VERSION ""

NS_ :

BS_:

BU_: EMS EAS
VAL_TABLE_ FMI 31 "ConditionExists" 19 "Received network data in error" 18 "Below normal (moderately severe)" 17 "Below normal (least severe)" 16 "Above normal (moderately severe)" 15 "Above normal (least severe)" 14 "Special intstructions" 13 "Out of calibration" 12 "Bad intelligent device" 11 "Root cause not known" 10 "Abnormal rate of change" 9 "Abnormal update rate" 8 "Abnormal frequency" 7 "Mechanical system not responding" 6 "Current above normal" 5 "Current below normal" 4 "Voltage below normal" 3 "Voltage above normal" 2 "Data erratic" 1 "Below normal (most severe)" 0 "Above normal (most severe)" ;

BO_ 3221225472 VECTOR__INDEPENDENT_SIG_MSG: 0 Vector__XXX
 SG_ AftrTrtmntOtltOxygnSnsrPrlmnryFM : 0|5@1+ (1,0) [0|31] "" Vector__XXX
 SG_ AftrTrtmntOtltNOxSnsrPrlmnryFMI : 0|5@1+ (1,0) [0|31] "" Vector__XXX
 SG_ AftrTrtmntOtltGsSnsorHeaterCtrl : 0|2@1+ (1,0) [0|3] "" Vector__XXX
 SG_ AftrTrtmntOtltGsSnsrHtrPrlmnryFM : 0|5@1+ (1,0) [0|31] "" Vector__XXX
 SG_ AftrTrtmntOtltWdRngO2RdngStable : 0|2@1+ (1,0) [0|3] "" Vector__XXX
 SG_ AftrTrtmntOtletNOxReadingStable : 0|2@1+ (1,0) [0|3] "" Vector__XXX
 SG_ AftrTrtmntOutletGasSensorAtTemp : 0|2@1+ (1,0) [0|3] "" Vector__XXX
 SG_ AftrTrtmntOtltGsSnsrPwerInRange : 0|2@1+ (1,0) [0|3] "" Vector__XXX
 SG_ AfterTreatmentOutletO2 : 0|16@1+ (0.000514,-12) [-12|21] "%" Vector__XXX
 SG_ AfterTreatmentOutletNOx : 0|16@1+ (0.05,-200) [-200|3012.75] "ppm" Vector__XXX
 SG_ RoadSurfaceTemp : 0|16@1+ (0.03125,-273) [-273|1735] "deg" Vector__XXX
 SG_ EngAirInletTemp : 0|8@1+ (1,-40) [-40|210] "deg" Vector__XXX
 SG_ AmbientAirTemp : 0|16@1+ (0.03125,-273) [-273|1735] "deg" Vector__XXX
 SG_ CabInteriorTemp : 0|16@1+ (0.03125,-273) [-273|1735] "deg" Vector__XXX
 SG_ BarometricPress : 0|8@1+ (0.5,0) [0|125] "kPa" Vector__XXX
 SG_ EngDemandPercentTorque : 0|8@1+ (1,-125) [-125|125] "%" Vector__XXX
 SG_ EngStarterMode : 0|4@1+ (1,0) [0|15] "" Vector__XXX
 SG_ SrcAddrssOfCtrllngDvcForEngCtrl : 0|8@1+ (1,0) [0|255] "" Vector__XXX
 SG_ EngSpeed : 0|16@1+ (0.125,0) [0|8031.875] "rpm" Vector__XXX
 SG_ DriversDemandEngPercentTorque : 0|8@1+ (1,-125) [-125|125] "%" Vector__XXX
 SG_ EngTorqueMode : 0|4@1+ (1,0) [0|15] "" Vector__XXX
 SG_ SPN5 : 0|16@1+ (1,0) [0|65536] "" Vector__XXX
 SG_ SPN4 : 0|16@1+ (1,0) [0|65536] "" Vector__XXX
 SG_ SPN3 : 0|16@1+ (1,0) [0|65536] "" Vector__XXX
 SG_ SPN2 : 0|16@1+ (1,0) [0|65536] "" Vector__XXX
 SG_ FailureModeIdentifier5 : 0|5@1+ (1,0) [0|0] "" Vector__XXX
 SG_ FailureModeIdentifier4 : 0|5@1+ (1,0) [0|0] "" Vector__XXX
 SG_ FailureModeIdentifier3 : 0|5@1+ (1,0) [0|0] "" Vector__XXX
 SG_ FlashRedStopLamp : 0|2@1+ (1,0) [0|3] "" Vector__XXX
 SG_ FlashProtectLamp : 0|2@1+ (1,0) [0|3] "" Vector__XXX
 SG_ FlashMalfuncIndicatorLamp : 0|2@1+ (1,0) [0|3] "" Vector__XXX
 SG_ FlashAmberWarningLamp : 0|2@1+ (1,0) [0|3] "" Vector__XXX
 SG_ MalfunctionIndicatorLampStatus : 0|2@1+ (1,0) [0|3] "" Vector__XXX
 SG_ AmberWarningLampStatus : 0|2@1+ (1,0) [0|3] "" Vector__XXX
 SG_ OccurenceCount1 : 0|7@1+ (1,0) [0|126] "" Vector__XXX
 SG_ SPNConversionMethod1 : 0|1@1+ (1,0) [0|1] "" Vector__XXX
 SG_ FailureModeIdentifier1 : 0|5@1+ (1,0) [0|0] "" Vector__XXX
 SG_ SPN1 : 0|16@1+ (1,0) [0|65536] "" Vector__XXX
 SG_ RedStopLampState : 0|2@1+ (1,0) [0|3] "" Vector__XXX
 SG_ ProtectLampStatus : 0|2@1+ (1,0) [0|3] "" Vector__XXX
 SG_ FailureModeIdentifier2 : 0|5@1+ (1,0) [0|0] "" Vector__XXX
 SG_ SPNConversionMethod5 : 0|1@1+ (1,0) [0|1] "" Vector__XXX
 SG_ SPNConversionMethod4 : 0|1@1+ (1,0) [0|1] "" Vector__XXX
 SG_ SPNConversionMethod3 : 0|1@1+ (1,0) [0|1] "" Vector__XXX
 SG_ SPNConversionMethod2 : 0|1@1+ (1,0) [0|1] "" Vector__XXX
 SG_ OccurenceCount5 : 0|7@1+ (1,0) [0|126] "" Vector__XXX
 SG_ OccurenceCount4 : 0|7@1+ (1,0) [0|126] "" Vector__XXX
 SG_ OccurenceCount3 : 0|7@1+ (1,0) [0|126] "" Vector__XXX
 SG_ OccurenceCount2 : 0|7@1+ (1,0) [0|126] "" Vector__XXX
 SG_ SPN5High : 0|3@1+ (1,0) [0|7] "" Vector__XXX
 SG_ SPN4High : 0|3@1+ (1,0) [0|7] "" Vector__XXX
 SG_ SPN3High : 0|3@1+ (1,0) [0|7] "" Vector__XXX
 SG_ SPN2High : 0|3@1+ (1,0) [0|7] "" Vector__XXX
 SG_ SPN1High : 0|3@1+ (1,0) [0|7] "" Vector__XXX
 SG_ SPN5 : 0|16@1+ (1,0) [0|65536] "" Vector__XXX
 SG_ SPN4 : 0|16@1+ (1,0) [0|65536] "" Vector__XXX
 SG_ SPN3 : 0|16@1+ (1,0) [0|65536] "" Vector__XXX
 SG_ SPN2 : 0|16@1+ (1,0) [0|65536] "" Vector__XXX
 SG_ FailureModeIdentifier5 : 0|5@1+ (1,0) [0|0] "" Vector__XXX
 SG_ FailureModeIdentifier4 : 0|5@1+ (1,0) [0|0] "" Vector__XXX
 SG_ OccurenceCount1 : 0|7@1+ (1,0) [0|126] "" Vector__XXX
 SG_ SPNConversionMethod1 : 0|1@1+ (1,0) [0|1] "" Vector__XXX
 SG_ FailureModeIdentifier1 : 0|5@1+ (1,0) [0|0] "" Vector__XXX
 SG_ SPN1 : 0|16@1+ (1,0) [0|65536] "" Vector__XXX
 SG_ MalfunctionIndicatorLampStatus : 0|2@1+ (1,0) [0|3] "" Vector__XXX
 SG_ RedStopLampState : 0|2@1+ (1,0) [0|3] "" Vector__XXX
 SG_ AmberWarningLampStatus : 0|2@1+ (1,0) [0|3] "" Vector__XXX
 SG_ ProtectLampStatus : 0|2@1+ (1,0) [0|3] "" Vector__XXX
 SG_ FailureModeIdentifier3 : 0|5@1+ (1,0) [0|0] "" Vector__XXX
 SG_ FlashRedStopLamp : 0|2@1+ (1,0) [0|3] "" Vector__XXX
 SG_ FlashProtectLamp : 0|2@1+ (1,0) [0|3] "" Vector__XXX
 SG_ FlashMalfuncIndicatorLamp : 0|2@1+ (1,0) [0|3] "" Vector__XXX
 SG_ FlashAmberWarningLamp : 0|2@1+ (1,0) [0|3] "" Vector__XXX
 SG_ FailureModeIdentifier2 : 0|5@1+ (1,0) [0|0] "" Vector__XXX
 SG_ SPNConversionMethod5 : 0|1@1+ (1,0) [0|1] "" Vector__XXX
 SG_ SPNConversionMethod4 : 0|1@1+ (1,0) [0|1] "" Vector__XXX
 SG_ SPNConversionMethod3 : 0|1@1+ (1,0) [0|1] "" Vector__XXX
 SG_ SPNConversionMethod2 : 0|1@1+ (1,0) [0|1] "" Vector__XXX
 SG_ OccurenceCount5 : 0|7@1+ (1,0) [0|126] "" Vector__XXX
 SG_ OccurenceCount4 : 0|7@1+ (1,0) [0|126] "" Vector__XXX
 SG_ OccurenceCount3 : 0|7@1+ (1,0) [0|126] "" Vector__XXX
 SG_ OccurenceCount2 : 0|7@1+ (1,0) [0|126] "" Vector__XXX
 SG_ SPN5High : 0|3@1+ (1,0) [0|7] "" Vector__XXX
 SG_ SPN4High : 0|3@1+ (1,0) [0|7] "" Vector__XXX
 SG_ SPN3High : 0|3@1+ (1,0) [0|7] "" Vector__XXX
 SG_ SPN2High : 0|3@1+ (1,0) [0|7] "" Vector__XXX
 SG_ SPN1High : 0|3@1+ (1,0) [0|7] "" Vector__XXX
 SG_ LastTransitionState : 0|8@1+ (1,0) [0|250] "" Vector__XXX
 SG_ ActualMachineState : 0|8@1+ (1,0) [0|250] "" Vector__XXX
 SG_ ActualDosingQuantity : 0|16@1+ (0.15,0) [0|9638.25] "g/h" Vector__XXX
 SG_ ExhaustGasTemperature : 0|16@1+ (0.03125,-273) [-273|1734.96875] "°C" Vector__XXX
 SG_ ExhaustGasMassFlow : 0|16@1+ (0.05,0) [0|3212.75] "kg/h" Vector__XXX
 SG_ PowerTakeOffEnable : 0|2@1+ (1,0) [0|2] "" Vector__XXX
 SG_ ExhaustGasTemperature : 0|16@1+ (0.03125,-273) [0|0] "°C" Vector__XXX
 SG_ ExhaustGasMassFlow : 0|16@1+ (0.05,0) [0|0] "kg/h" Vector__XXX
 SG_ PowerTakeOffEnable : 0|2@1+ (1,0) [0|0] "" Vector__XXX
 SG_ EngAverageFuelEconomy : 0|16@1+ (0.001953125,0) [0|125.5] "km/L" Vector__XXX
 SG_ EngInstantaneousFuelEconomy : 0|16@1+ (0.001953125,0) [0|125.5] "km/L" Vector__XXX
 SG_ EngFuelRate : 0|16@1+ (0.05,0) [0|3212.75] "L/h" Vector__XXX
 SG_ EngThrottlePos : 0|8@1+ (0.4,0) [0|100] "%" Vector__XXX
 SG_ EngInletAirMassFlowRate : 0|16@1+ (0.05,0) [0|3212.75] "kg/h" Vector__XXX
 SG_ EngExhstGsRcrcltionMassFlowRate : 0|16@1+ (0.05,0) [0|3212.75] "kg/h" Vector__XXX
 SG_ EngVrblGometryTurbo1ActuatorPos : 0|8@1+ (0.4,0) [0|100] "%" Vector__XXX
 SG_ EngVrblGmtryTrbArCtrlShtffValve : 0|2@1+ (1,0) [0|3] "" Vector__XXX
 SG_ EngExhstGsRcirculationValveCtrl : 0|16@1+ (0.0025,0) [0|160.6375] "%" Vector__XXX
 SG_ EngTrb1ClcltedTurbineOutletTemp : 0|16@1+ (0.03125,-273) [-273|1735] "deg" Vector__XXX
 SG_ EngTrb1ClclatedTurbineInletTemp : 0|16@1+ (0.03125,-273) [-273|1735] "deg" Vector__XXX
 SG_ ExhaustGasMass : 0|16@1+ (2,0) [0|128510] "kg" Vector__XXX
 SG_ AftrTrtmntIntakeDewPointMessage : 0|2@1+ (1,0) [0|3] "" Vector__XXX
 SG_ AftrTrtmntExhustDewPointMessage : 0|2@1+ (1,0) [0|3] "" Vector__XXX
 SG_ EstEngPrsticLossesPercentTorque : 0|8@1+ (1,-125) [-125|125] "%" Vector__XXX
 SG_ EngsDsrdOprtngSpdAsymmtryAdjstmn : 0|8@1+ (1,0) [0|250] "" Vector__XXX
 SG_ EngsDesiredOperatingSpeed : 0|16@1+ (0.125,0) [0|8031.875] "rpm" Vector__XXX
 SG_ NominalFrictionPercentTorque : 0|8@1+ (1,-125) [-125|125] "%" Vector__XXX
 SG_ CatalystTankLevelPreliminaryFMI : 0|5@1+ (1,0) [0|31] "" Vector__XXX
 SG_ CatalystTankLevel2 : 0|16@1+ (0.1,0) [0|6425.5] "mm" Vector__XXX
 SG_ SPN5 : 0|16@1+ (1,0) [0|65536] "" Vector__XXX
 SG_ SPN4 : 0|16@1+ (1,0) [0|65536] "" Vector__XXX
 SG_ SPN3 : 0|16@1+ (1,0) [0|65536] "" Vector__XXX
 SG_ SPN2 : 0|16@1+ (1,0) [0|65536] "" Vector__XXX
 SG_ FailureModeIdentifier5 : 0|5@1+ (1,0) [0|0] "" Vector__XXX
 SG_ FailureModeIdentifier4 : 0|5@1+ (1,0) [0|0] "" Vector__XXX
 SG_ FailureModeIdentifier3 : 0|5@1+ (1,0) [0|0] "" Vector__XXX
 SG_ FlashRedStopLamp : 0|2@1+ (1,0) [0|3] "" Vector__XXX
 SG_ FlashProtectLamp : 0|2@1+ (1,0) [0|3] "" Vector__XXX
 SG_ FlashMalfuncIndicatorLamp : 0|2@1+ (1,0) [0|3] "" Vector__XXX
 SG_ FlashAmberWarningLamp : 0|2@1+ (1,0) [0|3] "" Vector__XXX
 SG_ MalfunctionIndicatorLampStatus : 0|2@1+ (1,0) [0|3] "" Vector__XXX
 SG_ AmberWarningLampStatus : 0|2@1+ (1,0) [0|3] "" Vector__XXX
 SG_ OccurenceCount1 : 0|7@1+ (1,0) [0|126] "" Vector__XXX
 SG_ SPNConversionMethod1 : 0|1@1+ (1,0) [0|1] "" Vector__XXX
 SG_ FailureModeIdentifier1 : 0|5@1+ (1,0) [0|0] "" Vector__XXX
 SG_ SPN1 : 0|16@1+ (1,0) [0|65536] "" Vector__XXX
 SG_ RedStopLampState : 0|2@1+ (1,0) [0|3] "" Vector__XXX
 SG_ ProtectLampStatus : 0|2@1+ (1,0) [0|3] "" Vector__XXX
 SG_ FailureModeIdentifier2 : 0|5@1+ (1,0) [0|0] "" Vector__XXX
 SG_ SPNConversionMethod5 : 0|1@1+ (1,0) [0|1] "" Vector__XXX
 SG_ SPNConversionMethod4 : 0|1@1+ (1,0) [0|1] "" Vector__XXX
 SG_ SPNConversionMethod3 : 0|1@1+ (1,0) [0|1] "" Vector__XXX
 SG_ SPNConversionMethod2 : 0|1@1+ (1,0) [0|1] "" Vector__XXX
 SG_ OccurenceCount5 : 0|7@1+ (1,0) [0|126] "" Vector__XXX
 SG_ OccurenceCount4 : 0|7@1+ (1,0) [0|126] "" Vector__XXX
 SG_ OccurenceCount3 : 0|7@1+ (1,0) [0|126] "" Vector__XXX
 SG_ OccurenceCount2 : 0|7@1+ (1,0) [0|126] "" Vector__XXX
 SG_ SPN5High : 0|3@1+ (1,0) [0|7] "" Vector__XXX
 SG_ SPN4High : 0|3@1+ (1,0) [0|7] "" Vector__XXX
 SG_ SPN3High : 0|3@1+ (1,0) [0|7] "" Vector__XXX
 SG_ SPN2High : 0|3@1+ (1,0) [0|7] "" Vector__XXX
 SG_ SPN1High : 0|3@1+ (1,0) [0|7] "" Vector__XXX
 SG_ EngCoolantFilterDiffPress : 0|8@1+ (0.5,0) [0|125] "kPa" Vector__XXX
 SG_ EngExhaustGasTemp : 0|16@1+ (0.03125,-273) [-273|1735] "deg" Vector__XXX
 SG_ EngAirFilter1DiffPress : 0|8@1+ (0.05,0) [0|12.5] "kPa" Vector__XXX
 SG_ EngAirInletPress : 0|8@1+ (2,0) [0|500] "kPa" Vector__XXX
 SG_ EngIntakeManifold1Temp : 0|8@1+ (1,-40) [-40|210] "deg" Vector__XXX
 SG_ EngTurboBoostPress : 0|8@1+ (2,0) [0|500] "kPa" Vector__XXX
 SG_ EngParticulateTrapInletPress : 0|8@1+ (0.5,0) [0|125] "kPa" Vector__XXX
 SG_ EngIntercoolerThermostatOpening : 0|8@1+ (0.4,0) [0|100] "%" Vector__XXX
 SG_ EngIntercoolerTemp : 0|8@1+ (1,-40) [-40|210] "deg" Vector__XXX
 SG_ EngTurboOilTemp : 0|16@1+ (0.03125,-273) [-273|1735] "deg" Vector__XXX
 SG_ EngOilTemp1 : 0|16@1+ (0.03125,-273) [-273|1735] "deg" Vector__XXX
 SG_ EngFuelTemp : 0|8@1+ (1,-40) [-40|210] "deg" Vector__XXX
 SG_ EngCoolantTemp : 0|8@1+ (1,-40) [-40|210] "deg" Vector__XXX
 SG_ EngDemandPercentTorque : 0|8@1+ (1,-125) [-125|125] "%" Vector__XXX
 SG_ EngStarterMode : 0|4@1+ (1,0) [0|15] "" Vector__XXX
 SG_ SrcAddrssOfCtrllngDvcForEngCtrl : 0|8@1+ (1,0) [0|255] "" Vector__XXX
 SG_ EngSpeed : 0|16@1+ (0.125,0) [0|8031.875] "rpm" Vector__XXX
 SG_ ActualEngPercentTorque : 0|8@1+ (1,-125) [-125|125] "%" Vector__XXX
 SG_ DriversDemandEngPercentTorque : 0|8@1+ (1,-125) [-125|125] "%" Vector__XXX
 SG_ EngTorqueMode : 0|4@1+ (1,0) [0|15] "" Vector__XXX
 SG_ AftrTrtmntOtltOxygnSnsrPrlmnryFM : 0|5@1+ (1,0) [0|31] "" Vector__XXX
 SG_ AftrTrtmntOtltNOxSnsrPrlmnryFMI : 0|5@1+ (1,0) [0|31] "" Vector__XXX
 SG_ AftrTrtmntOtltGsSnsorHeaterCtrl : 0|2@1+ (1,0) [0|3] "" Vector__XXX
 SG_ AftrTrtmntOtltGsSnsrHtrPrlmnryFM : 0|5@1+ (1,0) [0|31] "" Vector__XXX
 SG_ AftrTrtmntOtltWdRngO2RdngStable : 0|2@1+ (1,0) [0|3] "" Vector__XXX
 SG_ AftrTrtmntOtletNOxReadingStable : 0|2@1+ (1,0) [0|3] "" Vector__XXX
 SG_ AftrTrtmntOutletGasSensorAtTemp : 0|2@1+ (1,0) [0|3] "" Vector__XXX
 SG_ AftrTrtmntOtltGsSnsrPwerInRange : 0|2@1+ (1,0) [0|3] "" Vector__XXX
 SG_ AfterTreatmentOutletO2 : 0|16@1+ (0.000514,-12) [-12|21] "%" Vector__XXX
 SG_ AfterTreatmentOutletNOx : 0|16@1+ (0.05,-200) [-200|3012.75] "ppm" Vector__XXX
 SG_ RoadSurfaceTemp : 0|16@1+ (0.03125,-273) [-273|1735] "deg" Vector__XXX
 SG_ EngAirInletTemp : 0|8@1+ (1,-40) [-40|210] "deg" Vector__XXX
 SG_ AmbientAirTemp : 0|16@1+ (0.03125,-273) [-273|1735] "deg" Vector__XXX
 SG_ CabInteriorTemp : 0|16@1+ (0.03125,-273) [-273|1735] "deg" Vector__XXX
 SG_ BarometricPress : 0|8@1+ (0.5,0) [0|125] "kPa" Vector__XXX

BO_ 2565406525 ACKM_EAS: 8 EAS
 SG_ AddressBusy m3 : 32|8@1+ (1,0) [0|255] "" Vector__XXX
 SG_ ParameterGroupNumber : 40|24@1+ (1,0) [0|16777215] "" Vector__XXX
 SG_ GroupFunctionValue : 8|8@1+ (1,0) [0|255] "" Vector__XXX
 SG_ ControlByte M : 0|8@1+ (1,0) [0|255] "" Vector__XXX
 SG_ AddressAccessDenied m2 : 32|8@1+ (1,0) [0|255] "" Vector__XXX
 SG_ AddressNegativeAcknowledgement m1 : 32|8@1+ (1,0) [0|255] "" Vector__XXX
 SG_ AddressAcknowledged m0 : 32|8@1+ (1,0) [0|255] "" Vector__XXX

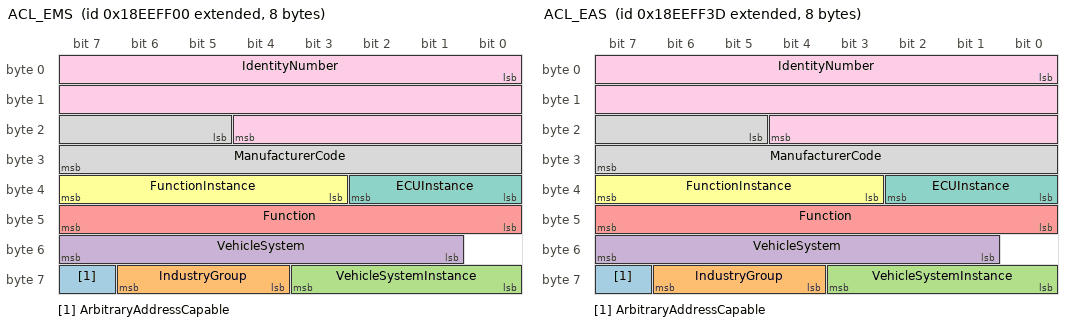
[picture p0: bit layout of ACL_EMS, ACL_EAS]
BO_ 2565799680 ACL_EMS: 8 EMS
 SG_ ArbitraryAddressCapable : 63|1@1+ (1,0) [0|1] "" Vector__XXX
 SG_ IndustryGroup : 60|3@1+ (1,0) [0|7] "" Vector__XXX
 SG_ VehicleSystemInstance : 56|4@1+ (1,0) [0|15] "" Vector__XXX
 SG_ VehicleSystem : 49|7@1+ (1,0) [0|127] "" Vector__XXX
 SG_ Function : 40|8@1+ (1,0) [0|255] "" Vector__XXX
 SG_ FunctionInstance : 35|5@1+ (1,0) [0|31] "" Vector__XXX
 SG_ ECUInstance : 32|3@1+ (1,0) [0|7] "" Vector__XXX
 SG_ ManufacturerCode : 21|11@1+ (1,0) [0|2047] "" Vector__XXX
 SG_ IdentityNumber : 0|21@1+ (1,0) [0|2097152] "" Vector__XXX

BO_ 2565603133 TPDT_EAS: 8 EAS
 SG_ SequenceNumber : 0|8@1+ (1,0) [0|252] "" Vector__XXX

BO_ 2565668669 TPCM_EAS: 8 EAS
 SG_ TotalNumberOfPacketsEoMA m19 : 24|8@1+ (1,0) [0|255] "" Vector__XXX
 SG_ TotalMessageSizeEoMA m19 : 8|16@1+ (1,0) [0|64255] "counts" Vector__XXX
 SG_ TotalMessageSizeBAM m32 : 8|16@1+ (1,0) [0|64255] "counts" Vector__XXX
 SG_ TotalNumberOfPacketsBAM m32 : 24|8@1+ (1,0) [0|255] "" Vector__XXX
 SG_ ConnectionAbortReason m255 : 8|8@1+ (1,0) [0|255] "" Vector__XXX
 SG_ NextPacketNumberToBeSent m17 : 16|8@1+ (1,0) [0|255] "" Vector__XXX
 SG_ NumberOfPacketsThatCanBeSent m17 : 8|8@1+ (1,0) [0|255] "" Vector__XXX
 SG_ PGNumber : 40|24@1+ (1,0) [0|16777200] "" Vector__XXX
 SG_ MaximumNumberOfPackets m16 : 32|8@1+ (1,0) [0|255] "" Vector__XXX
 SG_ TotalNumberOfPackets m16 : 24|8@1+ (1,0) [0|255] "" Vector__XXX
 SG_ TotalMessageSize m16 : 8|16@1+ (1,0) [0|64255] "counts" Vector__XXX
 SG_ ControlByte M : 0|8@1+ (1,0) [0|255] "" Vector__XXX

BO_ 2565799741 ACL_EAS: 8 EAS
 SG_ ArbitraryAddressCapable : 63|1@1+ (1,0) [0|1] "" Vector__XXX
 SG_ IndustryGroup : 60|3@1+ (1,0) [0|7] "" Vector__XXX
 SG_ VehicleSystemInstance : 56|4@1+ (1,0) [0|15] "" Vector__XXX
 SG_ VehicleSystem : 49|7@1+ (1,0) [0|127] "" Vector__XXX
 SG_ Function : 40|8@1+ (1,0) [0|255] "" Vector__XXX
 SG_ FunctionInstance : 35|5@1+ (1,0) [0|31] "" Vector__XXX
 SG_ ECUInstance : 32|3@1+ (1,0) [0|7] "" Vector__XXX
 SG_ ManufacturerCode : 21|11@1+ (1,0) [0|2047] "" Vector__XXX
 SG_ IdentityNumber : 0|21@1+ (1,0) [0|2097152] "" Vector__XXX

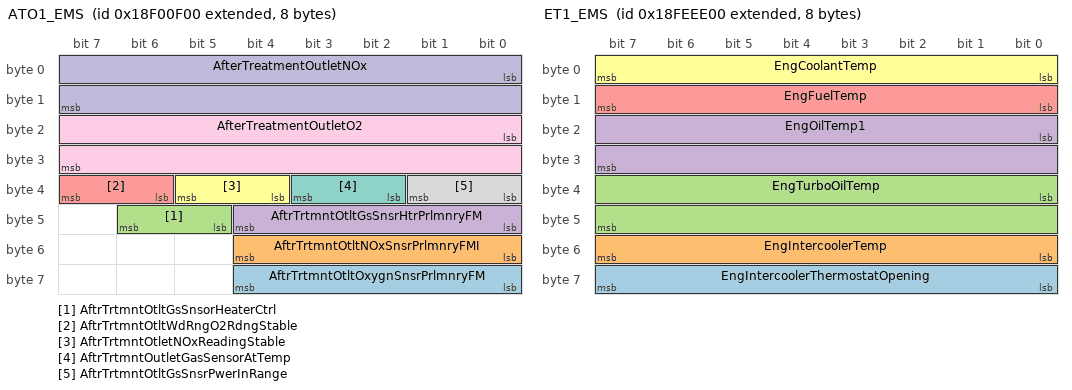
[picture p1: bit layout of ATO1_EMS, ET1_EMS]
BO_ 2565869312 ATO1_EMS: 8 EMS
 SG_ AftrTrtmntOtltOxygnSnsrPrlmnryFM : 56|5@1+ (1,0) [0|31] ""  EAS
 SG_ AftrTrtmntOtltNOxSnsrPrlmnryFMI : 48|5@1+ (1,0) [0|31] ""  EAS
 SG_ AftrTrtmntOtltGsSnsorHeaterCtrl : 45|2@1+ (1,0) [0|3] ""  EAS
 SG_ AftrTrtmntOtltGsSnsrHtrPrlmnryFM : 40|5@1+ (1,0) [0|31] ""  EAS
 SG_ AftrTrtmntOtltWdRngO2RdngStable : 38|2@1+ (1,0) [0|3] ""  EAS
 SG_ AftrTrtmntOtletNOxReadingStable : 36|2@1+ (1,0) [0|3] ""  EAS
 SG_ AftrTrtmntOutletGasSensorAtTemp : 34|2@1+ (1,0) [0|3] ""  EAS
 SG_ AftrTrtmntOtltGsSnsrPwerInRange : 32|2@1+ (1,0) [0|3] ""  EAS
 SG_ AfterTreatmentOutletO2 : 16|16@1+ (0.000514,-12) [-12|21] "%"  EAS
 SG_ AfterTreatmentOutletNOx : 0|16@1+ (0.05,-200) [-200|3012.75] "ppm"  EAS

BO_ 2566843904 ET1_EMS: 8 EMS
 SG_ EngIntercoolerThermostatOpening : 56|8@1+ (0.4,0) [0|100] "%"  EAS
 SG_ EngIntercoolerTemp : 48|8@1+ (1,-40) [-40|210] "deg"  EAS
 SG_ EngTurboOilTemp : 32|16@1+ (0.03125,-273) [-273|1735] "deg"  EAS
 SG_ EngOilTemp1 : 16|16@1+ (0.03125,-273) [-273|1735] "deg"  EAS
 SG_ EngFuelTemp : 8|8@1+ (1,-40) [-40|210] "deg"  EAS
 SG_ EngCoolantTemp : 0|8@1+ (1,-40) [-40|210] "deg"  EAS

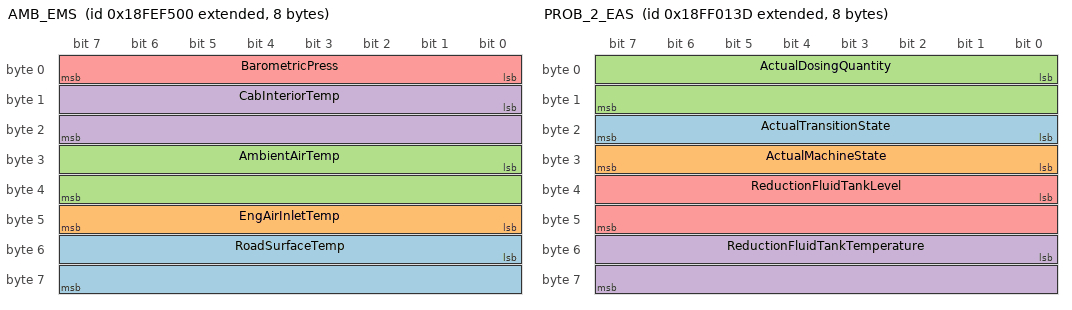
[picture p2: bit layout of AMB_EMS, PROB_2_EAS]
BO_ 2566845696 AMB_EMS: 8 EMS
 SG_ RoadSurfaceTemp : 48|16@1+ (0.03125,-273) [-273|1735] "deg"  EAS
 SG_ EngAirInletTemp : 40|8@1+ (1,-40) [-40|210] "deg"  EAS
 SG_ AmbientAirTemp : 24|16@1+ (0.03125,-273) [-273|1735] "deg"  EAS
 SG_ CabInteriorTemp : 8|16@1+ (0.03125,-273) [-273|1735] "deg"  EAS
 SG_ BarometricPress : 0|8@1+ (0.5,0) [0|125] "kPa"  EAS

BO_ 2364488960 PROA_1_EMS: 8 EMS
 SG_ RequestedUreaQuantity : 48|16@1+ (1,0) [0|64255] "g/h"  EAS

BO_ 2566848829 PROB_2_EAS: 8 EAS
 SG_ ActualTransitionState : 16|8@1+ (1,0) [0|250] "" Vector__XXX
 SG_ ActualMachineState : 24|8@1+ (1,0) [0|250] "" Vector__XXX
 SG_ ActualDosingQuantity : 0|16@1+ (0.15,0) [0|9638.25] "g/h" Vector__XXX
 SG_ ReductionFluidTankTemperature : 48|16@1+ (0.03125,-273) [-273|1734.96875] "°C" Vector__XXX
 SG_ ReductionFluidTankLevel : 32|16@1+ (0.4,0) [0|25702] "%" Vector__XXX

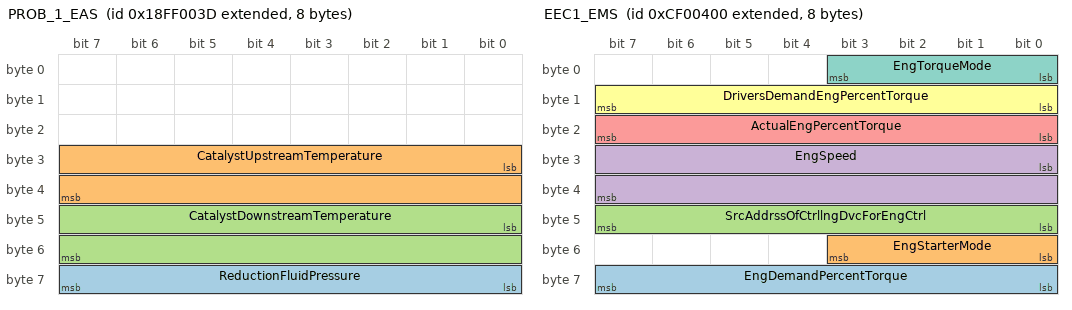
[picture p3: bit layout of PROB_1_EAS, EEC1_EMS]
BO_ 2566848573 PROB_1_EAS: 8 EAS
 SG_ ReductionFluidPressure : 56|8@1+ (2,0) [0|500] "kPa" Vector__XXX
 SG_ CatalystUpstreamTemperature : 24|16@1+ (0.03125,-273) [-273|1734.96875] "°C" Vector__XXX
 SG_ CatalystDownstreamTemperature : 40|16@1+ (0.03125,-273) [-273|1734.96875] "°C" Vector__XXX

BO_ 2364539904 EEC1_EMS: 8 EMS
 SG_ EngDemandPercentTorque : 56|8@1+ (1,-125) [-125|125] "%"  EAS
 SG_ EngStarterMode : 48|4@1+ (1,0) [0|15] ""  EAS
 SG_ SrcAddrssOfCtrllngDvcForEngCtrl : 40|8@1+ (1,0) [0|255] ""  EAS
 SG_ EngSpeed : 24|16@1+ (0.125,0) [0|8031.875] "rpm"  EAS
 SG_ ActualEngPercentTorque : 16|8@1+ (1,-125) [-125|125] "%"  EAS
 SG_ DriversDemandEngPercentTorque : 8|8@1+ (1,-125) [-125|125] "%"  EAS
 SG_ EngTorqueMode : 0|4@1+ (1,0) [0|15] ""  EAS

BO_ 2566835005 DM2_EAS: 22 EAS
 SG_ SPN5 : 144|16@1+ (1,0) [0|65536] "" Vector__XXX
 SG_ SPN4 : 112|16@1+ (1,0) [0|65536] "" Vector__XXX
 SG_ SPN3 : 80|16@1+ (1,0) [0|65536] "" Vector__XXX
 SG_ SPN2 : 48|16@1+ (1,0) [0|65536] "" Vector__XXX
 SG_ FailureModeIdentifier5 : 160|5@1+ (1,0) [0|0] "" Vector__XXX
 SG_ FailureModeIdentifier4 : 128|5@1+ (1,0) [0|0] "" Vector__XXX
 SG_ OccurenceCount1 : 40|7@1+ (1,0) [0|126] "" Vector__XXX
 SG_ SPNConversionMethod1 : 47|1@1+ (1,0) [0|1] "" Vector__XXX
 SG_ FailureModeIdentifier1 : 32|5@1+ (1,0) [0|0] "" Vector__XXX
 SG_ SPN1 : 16|16@1+ (1,0) [0|65536] "" Vector__XXX
 SG_ MalfunctionIndicatorLampStatus : 6|2@1+ (1,0) [0|3] "" Vector__XXX
 SG_ RedStopLampState : 4|2@1+ (1,0) [0|3] "" Vector__XXX
 SG_ AmberWarningLampStatus : 2|2@1+ (1,0) [0|3] "" Vector__XXX
 SG_ ProtectLampStatus : 0|2@1+ (1,0) [0|3] "" Vector__XXX
 SG_ FailureModeIdentifier3 : 96|5@1+ (1,0) [0|0] "" Vector__XXX
 SG_ FlashRedStopLamp : 12|2@1+ (1,0) [0|3] "" Vector__XXX
 SG_ FlashProtectLamp : 8|2@1+ (1,0) [0|3] "" Vector__XXX
 SG_ FlashMalfuncIndicatorLamp : 14|2@1+ (1,0) [0|3] "" Vector__XXX
 SG_ FlashAmberWarningLamp : 10|2@1+ (1,0) [0|3] "" Vector__XXX
 SG_ FailureModeIdentifier2 : 64|5@1+ (1,0) [0|0] "" Vector__XXX
 SG_ SPNConversionMethod5 : 175|1@1+ (1,0) [0|1] "" Vector__XXX
 SG_ SPNConversionMethod4 : 143|1@1+ (1,0) [0|1] "" Vector__XXX
 SG_ SPNConversionMethod3 : 111|1@1+ (1,0) [0|1] "" Vector__XXX
 SG_ SPNConversionMethod2 : 79|1@1+ (1,0) [0|1] "" Vector__XXX
 SG_ OccurenceCount5 : 168|7@1+ (1,0) [0|126] "" Vector__XXX
 SG_ OccurenceCount4 : 136|7@1+ (1,0) [0|126] "" Vector__XXX
 SG_ OccurenceCount3 : 104|7@1+ (1,0) [0|126] "" Vector__XXX
 SG_ OccurenceCount2 : 72|7@1+ (1,0) [0|126] "" Vector__XXX
 SG_ SPN5High : 165|3@1+ (1,0) [0|7] "" Vector__XXX
 SG_ SPN4High : 133|3@1+ (1,0) [0|7] "" Vector__XXX
 SG_ SPN3High : 101|3@1+ (1,0) [0|7] "" Vector__XXX
 SG_ SPN2High : 69|3@1+ (1,0) [0|7] "" Vector__XXX
 SG_ SPN1High : 37|3@1+ (1,0) [0|7] "" Vector__XXX

BO_ 2566834749 DM1_EAS: 22 EAS
 SG_ SPN5 : 144|16@1+ (1,0) [0|65536] "" Vector__XXX
 SG_ SPN4 : 112|16@1+ (1,0) [0|65536] "" Vector__XXX
 SG_ SPN3 : 80|16@1+ (1,0) [0|65536] "" Vector__XXX
 SG_ SPN2 : 48|16@1+ (1,0) [0|65536] "" Vector__XXX
 SG_ FailureModeIdentifier5 : 160|5@1+ (1,0) [0|0] "" Vector__XXX
 SG_ FailureModeIdentifier4 : 128|5@1+ (1,0) [0|0] "" Vector__XXX
 SG_ FailureModeIdentifier3 : 96|5@1+ (1,0) [0|0] "" Vector__XXX
 SG_ FlashRedStopLamp : 12|2@1+ (1,0) [0|3] "" Vector__XXX
 SG_ FlashProtectLamp : 8|2@1+ (1,0) [0|3] "" Vector__XXX
 SG_ FlashMalfuncIndicatorLamp : 14|2@1+ (1,0) [0|3] "" Vector__XXX
 SG_ FlashAmberWarningLamp : 10|2@1+ (1,0) [0|3] "" Vector__XXX
 SG_ MalfunctionIndicatorLampStatus : 6|2@1+ (1,0) [0|3] "" Vector__XXX
 SG_ AmberWarningLampStatus : 2|2@1+ (1,0) [0|3] "" Vector__XXX
 SG_ OccurenceCount1 : 40|7@1+ (1,0) [0|126] "" Vector__XXX
 SG_ SPNConversionMethod1 : 47|1@1+ (1,0) [0|1] "" Vector__XXX
 SG_ FailureModeIdentifier1 : 32|5@1+ (1,0) [0|0] "" Vector__XXX
 SG_ SPN1 : 16|16@1+ (1,0) [0|65536] "" Vector__XXX
 SG_ RedStopLampState : 4|2@1+ (1,0) [0|3] "" Vector__XXX
 SG_ ProtectLampStatus : 0|2@1+ (1,0) [0|3] "" Vector__XXX
 SG_ FailureModeIdentifier2 : 64|5@1+ (1,0) [0|0] "" Vector__XXX
 SG_ SPNConversionMethod5 : 175|1@1+ (1,0) [0|1] "" Vector__XXX
 SG_ SPNConversionMethod4 : 143|1@1+ (1,0) [0|1] "" Vector__XXX
 SG_ SPNConversionMethod3 : 111|1@1+ (1,0) [0|1] "" Vector__XXX
 SG_ SPNConversionMethod2 : 79|1@1+ (1,0) [0|1] "" Vector__XXX
 SG_ OccurenceCount5 : 168|7@1+ (1,0) [0|126] "" Vector__XXX
 SG_ OccurenceCount4 : 136|7@1+ (1,0) [0|126] "" Vector__XXX
 SG_ OccurenceCount3 : 104|7@1+ (1,0) [0|126] "" Vector__XXX
 SG_ OccurenceCount2 : 72|7@1+ (1,0) [0|126] "" Vector__XXX
 SG_ SPN5High : 165|3@1+ (1,0) [0|7] "" Vector__XXX
 SG_ SPN4High : 133|3@1+ (1,0) [0|7] "" Vector__XXX
 SG_ SPN3High : 101|3@1+ (1,0) [0|7] "" Vector__XXX
 SG_ SPN2High : 69|3@1+ (1,0) [0|7] "" Vector__XXX
 SG_ SPN1High : 37|3@1+ (1,0) [0|7] "" Vector__XXX

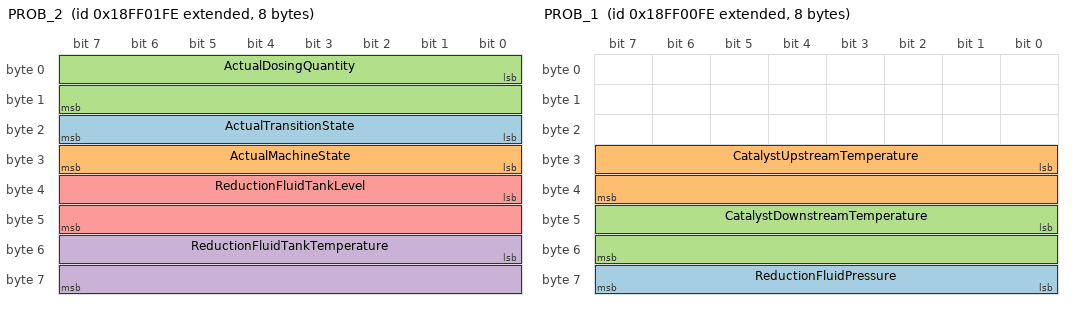
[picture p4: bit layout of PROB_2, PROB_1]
BO_ 2566849022 PROB_2: 8 Vector__XXX
 SG_ ActualTransitionState : 16|8@1+ (1,0) [0|250] "" Vector__XXX
 SG_ ActualMachineState : 24|8@1+ (1,0) [0|250] "" Vector__XXX
 SG_ ActualDosingQuantity : 0|16@1+ (0.15,0) [0|9638.25] "g/h" Vector__XXX
 SG_ ReductionFluidTankTemperature : 48|16@1+ (0.03125,-273) [-273|1734.96875] "°C" Vector__XXX
 SG_ ReductionFluidTankLevel : 32|16@1+ (0.4,0) [0|25702] "%" Vector__XXX

BO_ 2566848766 PROB_1: 8 Vector__XXX
 SG_ ReductionFluidPressure : 56|8@1+ (2,0) [0|500] "kPa" Vector__XXX
 SG_ CatalystUpstreamTemperature : 24|16@1+ (0.03125,-273) [-273|1734.96875] "°C" Vector__XXX
 SG_ CatalystDownstreamTemperature : 40|16@1+ (0.03125,-273) [-273|1734.96875] "°C" Vector__XXX

BO_ 2364538622 PROA_1: 8 Vector__XXX
 SG_ RequestedUreaQuantity : 48|16@1+ (1,0) [0|64255] "g/h" Vector__XXX

BO_ 2633938942 LF: 10 Vector__XXX
 SG_ TotalEngCruiseTime : 48|32@1+ (0.05,0) [0|210554060.75] "hr" Vector__XXX
 SG_ TotalDriveAverageLoadFactor : 40|8@1+ (0.4,0) [0|100] "%" Vector__XXX
 SG_ TripDriveAverageLoadFactor : 32|8@1+ (0.4,0) [0|100] "%" Vector__XXX
 SG_ TripAverageEngSpeed : 16|16@1+ (0.125,0) [0|8031.875] "rpm" Vector__XXX
 SG_ TripMaxEngSpeed : 0|16@1+ (0.125,0) [0|8031.875] "rpm" Vector__XXX

BO_ 2566799614 LD: 8 Vector__XXX
 SG_ ImplementRearWorkLight : 62|2@1+ (1,0) [0|3] "" Vector__XXX
 SG_ ImplementLeftForwardWorkLight : 60|2@1+ (1,0) [0|3] "" Vector__XXX
 SG_ ImplementRightForwardWorkLight : 58|2@1+ (1,0) [0|3] "" Vector__XXX
 SG_ ImplementLeftFacingWorkLight : 54|2@1+ (1,0) [0|3] "" Vector__XXX
 SG_ ImplementRightFacingWorkLight : 52|2@1+ (1,0) [0|3] "" Vector__XXX
 SG_ ImplementOEMOption1Light : 50|2@1+ (1,0) [0|3] "" Vector__XXX
 SG_ ImplementOEMOption2Light : 48|2@1+ (1,0) [0|3] "" Vector__XXX
 SG_ TrctrFrontHighMountedWorkLights : 46|2@1+ (1,0) [0|3] "" Vector__XXX
 SG_ TrctorFrontLowMountedWorkLights : 44|2@1+ (1,0) [0|3] "" Vector__XXX
 SG_ TrctorSideHighMountedWorkLights : 42|2@1+ (1,0) [0|3] "" Vector__XXX
 SG_ TractorSideLowMountedWorkLights : 40|2@1+ (1,0) [0|3] "" Vector__XXX
 SG_ TrctorRearHighMountedWorkLights : 38|2@1+ (1,0) [0|3] "" Vector__XXX
 SG_ TractorRearLowMountedWorkLights : 36|2@1+ (1,0) [0|3] "" Vector__XXX
 SG_ TrctrUndersideMountedWorkLights : 34|2@1+ (1,0) [0|3] "" Vector__XXX
 SG_ RearFogLights : 32|2@1+ (1,0) [0|3] "" Vector__XXX
 SG_ TractorMarkerLight : 30|2@1+ (1,0) [0|3] "" Vector__XXX
 SG_ ImplementMarkerLight : 28|2@1+ (1,0) [0|3] "" Vector__XXX
 SG_ TractorClearanceLight : 26|2@1+ (1,0) [0|3] "" Vector__XXX
 SG_ ImplementClearanceLight : 24|2@1+ (1,0) [0|3] "" Vector__XXX
 SG_ LeftStopLight : 22|2@1+ (1,0) [0|3] "" Vector__XXX
 SG_ RightStopLight : 20|2@1+ (1,0) [0|3] "" Vector__XXX
 SG_ CenterStopLight : 18|2@1+ (1,0) [0|3] "" Vector__XXX
 SG_ BackUpLightAndAlarmHorn : 16|2@1+ (1,0) [0|3] "" Vector__XXX
 SG_ LeftTurnSignalLights : 14|2@1+ (1,0) [0|3] "" Vector__XXX
 SG_ RightTurnSignalLights : 12|2@1+ (1,0) [0|3] "" Vector__XXX
 SG_ RotatingBeaconLight : 10|2@1+ (1,0) [0|3] "" Vector__XXX
 SG_ TractorFrontFogLights : 8|2@1+ (1,0) [0|3] "" Vector__XXX
 SG_ HighBeamHeadLightData : 6|2@1+ (1,0) [0|3] "" Vector__XXX
 SG_ LowBeamHeadLightData : 4|2@1+ (1,0) [0|3] "" Vector__XXX
 SG_ AltBeamHeadLightData : 2|2@1+ (1,0) [0|3] "" Vector__XXX
 SG_ RunningLight : 0|2@1+ (1,0) [0|3] "" Vector__XXX

BO_ 2365473278 LC: 8 Vector__XXX
 SG_ ImplementRearWorkLightCmd : 62|2@1+ (1,0) [0|3] "" Vector__XXX
 SG_ ImplmentLeftForwardWorkLightCmd : 60|2@1+ (1,0) [0|3] "" Vector__XXX
 SG_ ImplmntRightForwardWorkLightCmd : 58|2@1+ (1,0) [0|3] "" Vector__XXX
 SG_ LightingDataRqCmd : 56|2@1+ (1,0) [0|3] "" Vector__XXX
 SG_ ImplementLeftFacingWorkLightCmd : 54|2@1+ (1,0) [0|3] "" Vector__XXX
 SG_ ImplmentRightFacingWorkLightCmd : 52|2@1+ (1,0) [0|3] "" Vector__XXX
 SG_ ImplementOEMOption1LightCmd : 50|2@1+ (1,0) [0|3] "" Vector__XXX
 SG_ ImplementOEMOption2LightCmd : 48|2@1+ (1,0) [0|3] "" Vector__XXX
 SG_ TrctrFrntHghMuntedWorkLightsCmd : 46|2@1+ (1,0) [0|3] "" Vector__XXX
 SG_ TrctrFrntLwMountedWorkLightsCmd : 44|2@1+ (1,0) [0|3] "" Vector__XXX
 SG_ TrctrSdHighMountedWorkLightsCmd : 42|2@1+ (1,0) [0|3] "" Vector__XXX
 SG_ TrctrSdeLowMountedWorkLightsCmd : 40|2@1+ (1,0) [0|3] "" Vector__XXX
 SG_ TrctrRrHighMountedWorkLightsCmd : 38|2@1+ (1,0) [0|3] "" Vector__XXX
 SG_ TrctrRarLowMountedWorkLightsCmd : 36|2@1+ (1,0) [0|3] "" Vector__XXX
 SG_ TrctrUndrsdMountedWorkLightsCmd : 34|2@1+ (1,0) [0|3] "" Vector__XXX
 SG_ RearFogLightCmd : 32|2@1+ (1,0) [0|3] "" Vector__XXX
 SG_ TractorMarkerLightCmd : 30|2@1+ (1,0) [0|3] "" Vector__XXX
 SG_ ImplementMarkerLightCmd : 28|2@1+ (1,0) [0|3] "" Vector__XXX
 SG_ TractorClearanceLightCmd : 26|2@1+ (1,0) [0|3] "" Vector__XXX
 SG_ ImplementClearanceLightCmd : 24|2@1+ (1,0) [0|3] "" Vector__XXX
 SG_ LeftStopLightCmd : 22|2@1+ (1,0) [0|3] "" Vector__XXX
 SG_ RightStopLightCmd : 20|2@1+ (1,0) [0|3] "" Vector__XXX
 SG_ CenterStopLightCmd : 18|2@1+ (1,0) [0|3] "" Vector__XXX
 SG_ BackUpLightAndAlarmHornCmd : 16|2@1+ (1,0) [0|3] "" Vector__XXX
 SG_ LeftTurnSignalLightsCmd : 14|2@1+ (1,0) [0|3] "" Vector__XXX
 SG_ RightTurnSignalLightsCmd : 12|2@1+ (1,0) [0|3] "" Vector__XXX
 SG_ RotatingBeaconLightCmd : 10|2@1+ (1,0) [0|3] "" Vector__XXX
 SG_ TractorFrontFogLightsCmd : 8|2@1+ (1,0) [0|3] "" Vector__XXX
 SG_ HighBeamHeadLightCmd : 6|2@1+ (1,0) [0|3] "" Vector__XXX
 SG_ LowBeamHeadLightCmd : 4|2@1+ (1,0) [0|3] "" Vector__XXX
 SG_ AltBeamHeadLightCmd : 2|2@1+ (1,0) [0|3] "" Vector__XXX
 SG_ RunningLightCmd : 0|2@1+ (1,0) [0|3] "" Vector__XXX

BO_ 2365485822 LBC: 8 Vector__XXX
 SG_ BladeCtrlMode : 16|8@1+ (1,0) [0|255] "" Vector__XXX
 SG_ BladeDurationAndDirection : 0|16@1+ (0.1,-3276.8) [-3276.8|3148.7] "sec" Vector__XXX

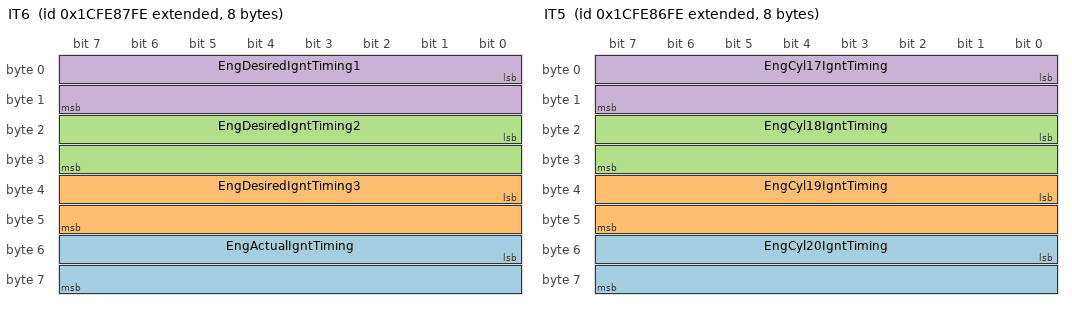
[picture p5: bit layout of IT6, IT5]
BO_ 2633926654 IT6: 8 Vector__XXX
 SG_ EngActualIgntTiming : 48|16@1+ (0.0078125,-200) [-200|301.99] "deg" Vector__XXX
 SG_ EngDesiredIgntTiming3 : 32|16@1+ (0.0078125,-200) [-200|301.99] "deg" Vector__XXX
 SG_ EngDesiredIgntTiming2 : 16|16@1+ (0.0078125,-200) [-200|301.99] "deg" Vector__XXX
 SG_ EngDesiredIgntTiming1 : 0|16@1+ (0.0078125,-200) [-200|301.99] "deg" Vector__XXX

BO_ 2633926398 IT5: 8 Vector__XXX
 SG_ EngCyl20IgntTiming : 48|16@1+ (0.0078125,-200) [-200|301.99] "deg" Vector__XXX
 SG_ EngCyl19IgntTiming : 32|16@1+ (0.0078125,-200) [-200|301.99] "deg" Vector__XXX
 SG_ EngCyl18IgntTiming : 16|16@1+ (0.0078125,-200) [-200|301.99] "deg" Vector__XXX
 SG_ EngCyl17IgntTiming : 0|16@1+ (0.0078125,-200) [-200|301.99] "deg" Vector__XXX

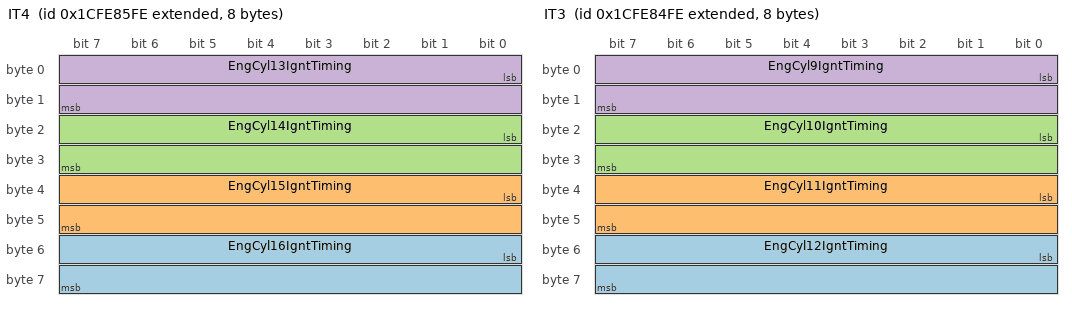
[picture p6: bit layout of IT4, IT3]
BO_ 2633926142 IT4: 8 Vector__XXX
 SG_ EngCyl16IgntTiming : 48|16@1+ (0.0078125,-200) [-200|301.99] "deg" Vector__XXX
 SG_ EngCyl15IgntTiming : 32|16@1+ (0.0078125,-200) [-200|301.99] "deg" Vector__XXX
 SG_ EngCyl14IgntTiming : 16|16@1+ (0.0078125,-200) [-200|301.99] "deg" Vector__XXX
 SG_ EngCyl13IgntTiming : 0|16@1+ (0.0078125,-200) [-200|301.99] "deg" Vector__XXX

BO_ 2633925886 IT3: 8 Vector__XXX
 SG_ EngCyl12IgntTiming : 48|16@1+ (0.0078125,-200) [-200|301.99] "deg" Vector__XXX
 SG_ EngCyl11IgntTiming : 32|16@1+ (0.0078125,-200) [-200|301.99] "deg" Vector__XXX
 SG_ EngCyl10IgntTiming : 16|16@1+ (0.0078125,-200) [-200|301.99] "deg" Vector__XXX
 SG_ EngCyl9IgntTiming : 0|16@1+ (0.0078125,-200) [-200|301.99] "deg" Vector__XXX

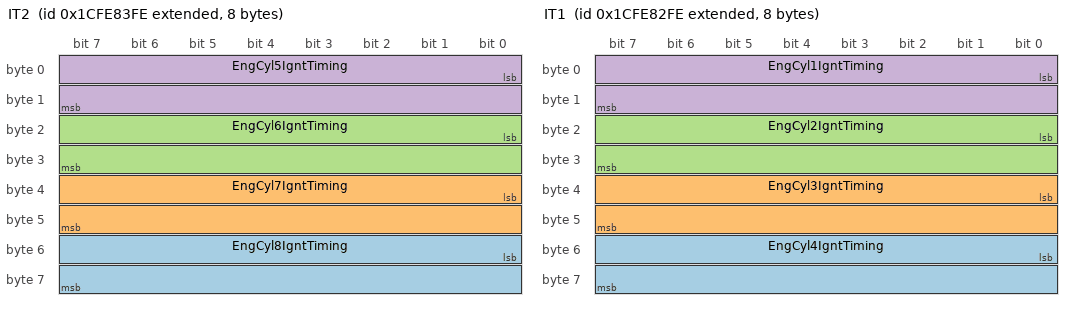
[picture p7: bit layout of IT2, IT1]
BO_ 2633925630 IT2: 8 Vector__XXX
 SG_ EngCyl8IgntTiming : 48|16@1+ (0.0078125,-200) [-200|301.99] "deg" Vector__XXX
 SG_ EngCyl7IgntTiming : 32|16@1+ (0.0078125,-200) [-200|301.99] "deg" Vector__XXX
 SG_ EngCyl6IgntTiming : 16|16@1+ (0.0078125,-200) [-200|301.99] "deg" Vector__XXX
 SG_ EngCyl5IgntTiming : 0|16@1+ (0.0078125,-200) [-200|301.99] "deg" Vector__XXX

BO_ 2633925374 IT1: 8 Vector__XXX
 SG_ EngCyl4IgntTiming : 48|16@1+ (0.0078125,-200) [-200|301.99] "deg" Vector__XXX
 SG_ EngCyl3IgntTiming : 32|16@1+ (0.0078125,-200) [-200|301.99] "deg" Vector__XXX
 SG_ EngCyl2IgntTiming : 16|16@1+ (0.0078125,-200) [-200|301.99] "deg" Vector__XXX
 SG_ EngCyl1IgntTiming : 0|16@1+ (0.0078125,-200) [-200|301.99] "deg" Vector__XXX

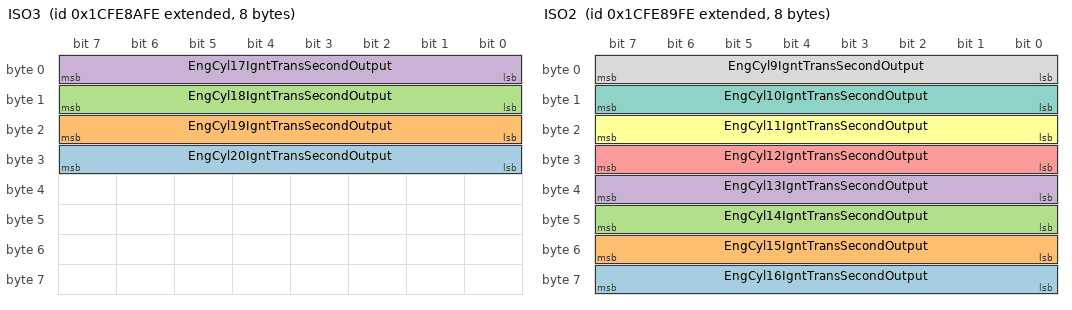
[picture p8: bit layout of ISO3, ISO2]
BO_ 2633927422 ISO3: 8 Vector__XXX
 SG_ EngCyl20IgntTransSecondOutput : 24|8@1+ (1,-125) [-125|125] "%" Vector__XXX
 SG_ EngCyl19IgntTransSecondOutput : 16|8@1+ (1,-125) [-125|125] "%" Vector__XXX
 SG_ EngCyl18IgntTransSecondOutput : 8|8@1+ (1,-125) [-125|125] "%" Vector__XXX
 SG_ EngCyl17IgntTransSecondOutput : 0|8@1+ (1,-125) [-125|125] "%" Vector__XXX

BO_ 2633927166 ISO2: 8 Vector__XXX
 SG_ EngCyl16IgntTransSecondOutput : 56|8@1+ (1,-125) [-125|125] "%" Vector__XXX
 SG_ EngCyl15IgntTransSecondOutput : 48|8@1+ (1,-125) [-125|125] "%" Vector__XXX
 SG_ EngCyl14IgntTransSecondOutput : 40|8@1+ (1,-125) [-125|125] "%" Vector__XXX
 SG_ EngCyl13IgntTransSecondOutput : 32|8@1+ (1,-125) [-125|125] "%" Vector__XXX
 SG_ EngCyl12IgntTransSecondOutput : 24|8@1+ (1,-125) [-125|125] "%" Vector__XXX
 SG_ EngCyl11IgntTransSecondOutput : 16|8@1+ (1,-125) [-125|125] "%" Vector__XXX
 SG_ EngCyl10IgntTransSecondOutput : 8|8@1+ (1,-125) [-125|125] "%" Vector__XXX
 SG_ EngCyl9IgntTransSecondOutput : 0|8@1+ (1,-125) [-125|125] "%" Vector__XXX

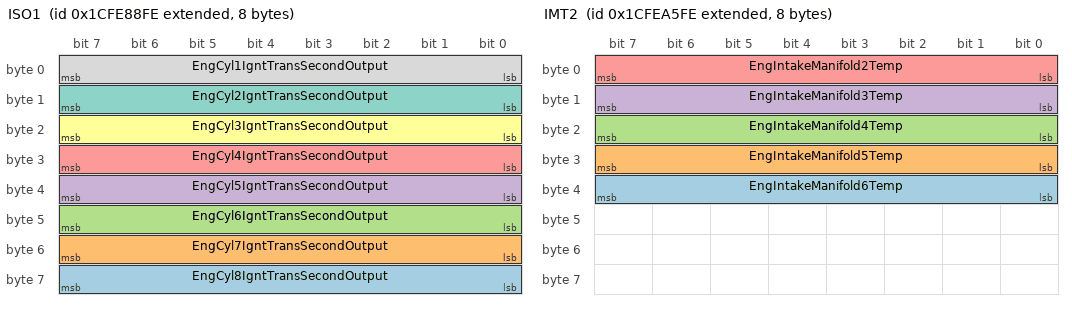
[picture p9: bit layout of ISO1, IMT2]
BO_ 2633926910 ISO1: 8 Vector__XXX
 SG_ EngCyl8IgntTransSecondOutput : 56|8@1+ (1,-125) [-125|125] "%" Vector__XXX
 SG_ EngCyl7IgntTransSecondOutput : 48|8@1+ (1,-125) [-125|125] "%" Vector__XXX
 SG_ EngCyl6IgntTransSecondOutput : 40|8@1+ (1,-125) [-125|125] "%" Vector__XXX
 SG_ EngCyl5IgntTransSecondOutput : 32|8@1+ (1,-125) [-125|125] "%" Vector__XXX
 SG_ EngCyl4IgntTransSecondOutput : 24|8@1+ (1,-125) [-125|125] "%" Vector__XXX
 SG_ EngCyl3IgntTransSecondOutput : 16|8@1+ (1,-125) [-125|125] "%" Vector__XXX
 SG_ EngCyl2IgntTransSecondOutput : 8|8@1+ (1,-125) [-125|125] "%" Vector__XXX
 SG_ EngCyl1IgntTransSecondOutput : 0|8@1+ (1,-125) [-125|125] "%" Vector__XXX

BO_ 2566768894 ISCS: 8 Vector__XXX
 SG_ EngOprtrPrmryIntrmdtSpdSlctStte : 0|4@1+ (1,0) [0|15] "" Vector__XXX

BO_ 2566769406 ISC: 8 Vector__XXX
 SG_ EngOprtrPrmryIntrmdtSpeedSelect : 0|4@1+ (1,0) [0|15] "" Vector__XXX

BO_ 2566839550 IO: 8 Vector__XXX
 SG_ EngTotalIdleHours : 32|32@1+ (0.05,0) [0|210554060.75] "hr" Vector__XXX
 SG_ EngTotalIdleFuelUsed : 0|32@1+ (0.5,0) [0|2105540607.5] "L" Vector__XXX

BO_ 2633934334 IMT2: 8 Vector__XXX
 SG_ EngIntakeManifold6Temp : 32|8@1+ (1,-40) [-40|210] "deg" Vector__XXX
 SG_ EngIntakeManifold5Temp : 24|8@1+ (1,-40) [-40|210] "deg" Vector__XXX
 SG_ EngIntakeManifold4Temp : 16|8@1+ (1,-40) [-40|210] "deg" Vector__XXX
 SG_ EngIntakeManifold3Temp : 8|8@1+ (1,-40) [-40|210] "deg" Vector__XXX
 SG_ EngIntakeManifold2Temp : 0|8@1+ (1,-40) [-40|210] "deg" Vector__XXX

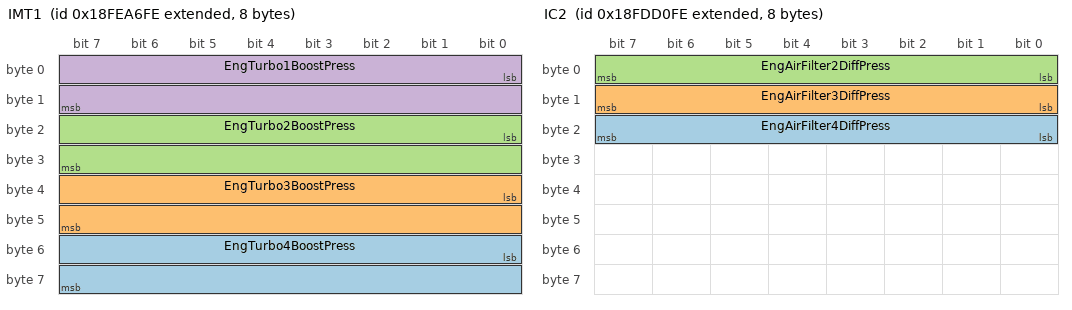
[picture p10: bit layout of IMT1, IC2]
BO_ 2566825726 IMT1: 8 Vector__XXX
 SG_ EngTurbo4BoostPress : 48|16@1+ (0.125,0) [0|8031.875] "kPa" Vector__XXX
 SG_ EngTurbo3BoostPress : 32|16@1+ (0.125,0) [0|8031.875] "kPa" Vector__XXX
 SG_ EngTurbo2BoostPress : 16|16@1+ (0.125,0) [0|8031.875] "kPa" Vector__XXX
 SG_ EngTurbo1BoostPress : 0|16@1+ (0.125,0) [0|8031.875] "kPa" Vector__XXX

BO_ 2566770942 IC2: 8 Vector__XXX
 SG_ EngAirFilter4DiffPress : 16|8@1+ (0.05,0) [0|12.5] "kPa" Vector__XXX
 SG_ EngAirFilter3DiffPress : 8|8@1+ (0.05,0) [0|12.5] "kPa" Vector__XXX
 SG_ EngAirFilter2DiffPress : 0|8@1+ (0.05,0) [0|12.5] "kPa" Vector__XXX

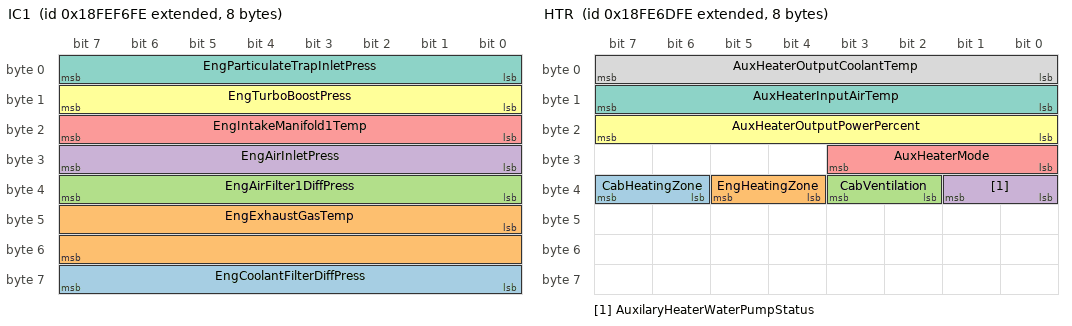
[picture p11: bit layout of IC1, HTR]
BO_ 2566846206 IC1: 8 Vector__XXX
 SG_ EngCoolantFilterDiffPress : 56|8@1+ (0.5,0) [0|125] "kPa" Vector__XXX
 SG_ EngExhaustGasTemp : 40|16@1+ (0.03125,-273) [-273|1735] "deg" Vector__XXX
 SG_ EngAirFilter1DiffPress : 32|8@1+ (0.05,0) [0|12.5] "kPa" Vector__XXX
 SG_ EngAirInletPress : 24|8@1+ (2,0) [0|500] "kPa" Vector__XXX
 SG_ EngIntakeManifold1Temp : 16|8@1+ (1,-40) [-40|210] "deg" Vector__XXX
 SG_ EngTurboBoostPress : 8|8@1+ (2,0) [0|500] "kPa" Vector__XXX
 SG_ EngParticulateTrapInletPress : 0|8@1+ (0.5,0) [0|125] "kPa" Vector__XXX

BO_ 2566811134 HTR: 8 Vector__XXX
 SG_ CabHeatingZone : 38|2@1+ (1,0) [0|3] "" Vector__XXX
 SG_ EngHeatingZone : 36|2@1+ (1,0) [0|3] "" Vector__XXX
 SG_ CabVentilation : 34|2@1+ (1,0) [0|3] "" Vector__XXX
 SG_ AuxilaryHeaterWaterPumpStatus : 32|2@1+ (1,0) [0|3] "" Vector__XXX
 SG_ AuxHeaterMode : 24|4@1+ (1,0) [0|15] "" Vector__XXX
 SG_ AuxHeaterOutputPowerPercent : 16|8@1+ (0.4,0) [0|100] "%" Vector__XXX
 SG_ AuxHeaterInputAirTemp : 8|8@1+ (1,-40) [-40|210] "deg" Vector__XXX
 SG_ AuxHeaterOutputCoolantTemp : 0|8@1+ (1,-40) [-40|210] "deg" Vector__XXX

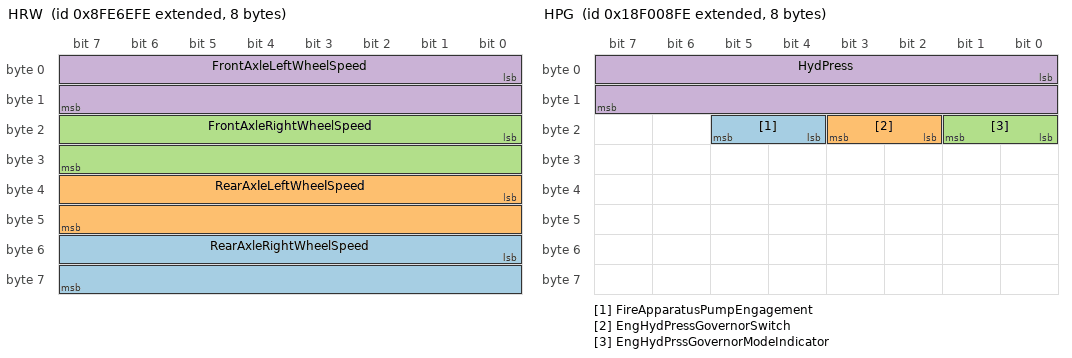
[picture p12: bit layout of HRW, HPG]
BO_ 2298375934 HRW: 8 Vector__XXX
 SG_ RearAxleRightWheelSpeed : 48|16@1+ (0.00390625,0) [0|250.996] "km/h" Vector__XXX
 SG_ RearAxleLeftWheelSpeed : 32|16@1+ (0.00390625,0) [0|250.996] "km/h" Vector__XXX
 SG_ FrontAxleRightWheelSpeed : 16|16@1+ (0.00390625,0) [0|250.996] "km/h" Vector__XXX
 SG_ FrontAxleLeftWheelSpeed : 0|16@1+ (0.00390625,0) [0|250.966] "km/h" Vector__XXX

BO_ 2565867774 HPG: 8 Vector__XXX
 SG_ FireApparatusPumpEngagement : 20|2@1+ (1,0) [0|3] "" Vector__XXX
 SG_ EngHydPressGovernorSwitch : 18|2@1+ (1,0) [0|3] "" Vector__XXX
 SG_ EngHydPrssGovernorModeIndicator : 16|2@1+ (1,0) [0|3] "" Vector__XXX
 SG_ HydPress : 0|16@1+ (2,0) [0|128510] "kPa" Vector__XXX

BO_ 2566841854 HOURS: 8 Vector__XXX
 SG_ EngTotalRevolutions : 32|32@1+ (1000,0) [0|4211081215000] "r" Vector__XXX
 SG_ EngTotalHoursOfOperation : 0|32@1+ (0.05,0) [0|210554060.75] "hr" Vector__XXX

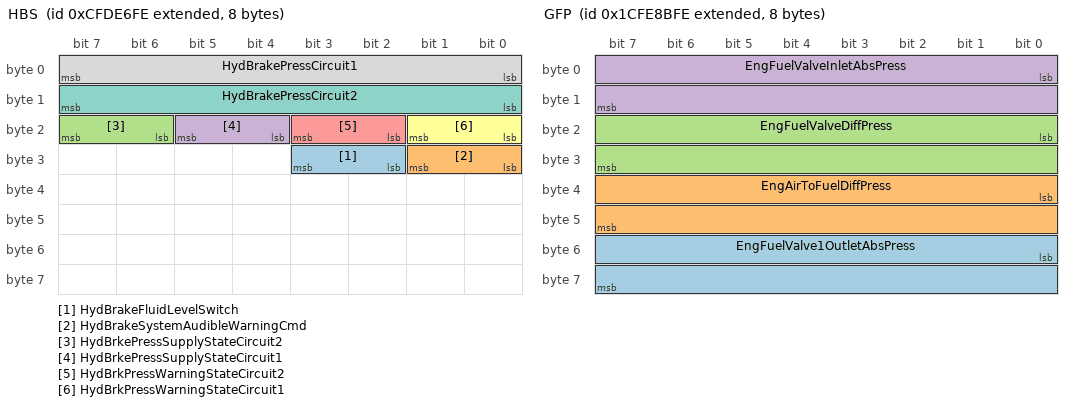
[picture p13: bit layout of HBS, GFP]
BO_ 2365449982 HBS: 8 Vector__XXX
 SG_ HydBrakeFluidLevelSwitch : 26|2@1+ (1,0) [0|3] "" Vector__XXX
 SG_ HydBrakeSystemAudibleWarningCmd : 24|2@1+ (1,0) [0|3] "" Vector__XXX
 SG_ HydBrkePressSupplyStateCircuit2 : 22|2@1+ (1,0) [0|3] "" Vector__XXX
 SG_ HydBrkePressSupplyStateCircuit1 : 20|2@1+ (1,0) [0|3] "" Vector__XXX
 SG_ HydBrkPressWarningStateCircuit2 : 18|2@1+ (1,0) [0|3] "" Vector__XXX
 SG_ HydBrkPressWarningStateCircuit1 : 16|2@1+ (1,0) [0|3] "" Vector__XXX
 SG_ HydBrakePressCircuit2 : 8|8@1+ (100,0) [0|25] "MPa" Vector__XXX
 SG_ HydBrakePressCircuit1 : 0|8@1+ (100,0) [0|25] "MPa" Vector__XXX

BO_ 2633939198 GTFI: 22 Vector__XXX
 SG_ TripDriveFuelEconomy : 160|16@1+ (0.00195313,0) [0|125.5] "km/L" Vector__XXX
 SG_ TripCruiseFuelUsed : 128|32@1+ (0.5,0) [0|2105540607.5] "kg" Vector__XXX
 SG_ TripVehicleIdleFuelUsed : 96|32@1+ (0.5,0) [0|2105540607.5] "kg" Vector__XXX
 SG_ TripPTONonmovingFuelUsed : 64|32@1+ (0.5,0) [0|2105540607.5] "kg" Vector__XXX
 SG_ TripPTOMovingFuelUsed : 32|32@1+ (0.5,0) [0|2105540607.5] "kg" Vector__XXX
 SG_ TripDriveFuelUsed : 0|32@1+ (0.5,0) [0|2105540607.5] "kg" Vector__XXX

BO_ 2633927678 GFP: 8 Vector__XXX
 SG_ EngFuelValve1OutletAbsPress : 48|16@1+ (0.1,0) [0|6425.5] "kPa" Vector__XXX
 SG_ EngAirToFuelDiffPress : 32|16@1+ (0.1,0) [0|6425.5] "kPa" Vector__XXX
 SG_ EngFuelValveDiffPress : 16|16@1+ (0.1,0) [0|6425.5] "kPa" Vector__XXX
 SG_ EngFuelValveInletAbsPress : 0|16@1+ (0.1,0) [0|6425.5] "kPa" Vector__XXX

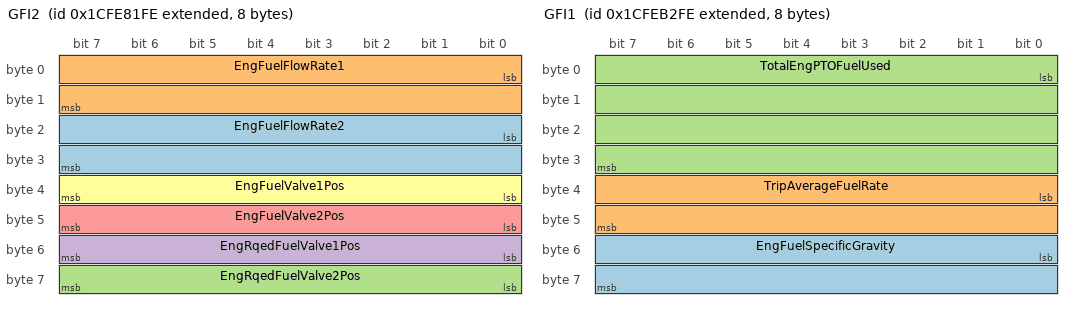
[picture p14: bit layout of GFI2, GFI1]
BO_ 2633925118 GFI2: 8 Vector__XXX
 SG_ EngFuelFlowRate2 : 16|16@1+ (0.1,0) [0|6425.5] "m³/h" Vector__XXX
 SG_ EngFuelFlowRate1 : 0|16@1+ (0.1,0) [0|6425.5] "m³/h" Vector__XXX
 SG_ EngRqedFuelValve2Pos : 56|8@1+ (0.4,0) [0|100] "%" Vector__XXX
 SG_ EngRqedFuelValve1Pos : 48|8@1+ (0.4,0) [0|100] "%" Vector__XXX
 SG_ EngFuelValve2Pos : 40|8@1+ (0.4,0) [0|100] "%" Vector__XXX
 SG_ EngFuelValve1Pos : 32|8@1+ (0.4,0) [0|100] "%" Vector__XXX

BO_ 2633937662 GFI1: 8 Vector__XXX
 SG_ EngFuelSpecificGravity : 48|16@1+ (0.0001,0) [0|6.4255] "" Vector__XXX
 SG_ TripAverageFuelRate : 32|16@1+ (0.05,0) [0|3212.75] "kg/h" Vector__XXX
 SG_ TotalEngPTOFuelUsed : 0|32@1+ (0.5,0) [0|2105540607.5] "kg" Vector__XXX

BO_ 2566804990 GFD: 8 Vector__XXX
 SG_ SpecificHeatRatio : 0|16@1+ (0.001,0) [0|64.255] "" Vector__XXX

BO_ 2633936894 GFC: 8 Vector__XXX
 SG_ TotalFuelUsed : 32|32@1+ (0.5,0) [0|2105540607.5] "kg" Vector__XXX
 SG_ TripFuel : 0|32@1+ (0.5,0) [0|2105540607.5] "kg" Vector__XXX

BO_ 2566757630 SEP2: 8 Vector__XXX
 SG_ SensorSupplyVoltage6 : 16|16@1+ (0.05,0) [0|3212.75] "V" Vector__XXX
 SG_ SensorSupplyVoltage5 : 0|16@1+ (0.05,0) [0|3212.75] "V" Vector__XXX

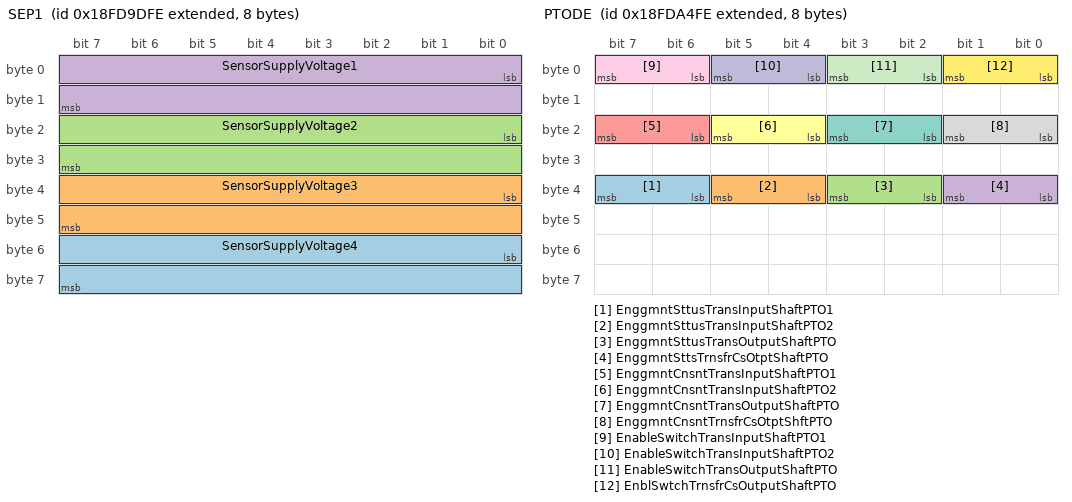
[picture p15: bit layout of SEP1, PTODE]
BO_ 2566757886 SEP1: 8 Vector__XXX
 SG_ SensorSupplyVoltage4 : 48|16@1+ (0.05,0) [0|3212.75] "V" Vector__XXX
 SG_ SensorSupplyVoltage3 : 32|16@1+ (0.05,0) [0|3212.75] "V" Vector__XXX
 SG_ SensorSupplyVoltage2 : 16|16@1+ (0.05,0) [0|3212.75] "V" Vector__XXX
 SG_ SensorSupplyVoltage1 : 0|16@1+ (0.05,0) [0|3212.75] "V" Vector__XXX

BO_ 2566759678 PTODE: 8 Vector__XXX
 SG_ EnggmntSttusTransInputShaftPTO1 : 38|2@1+ (1,0) [0|3] "" Vector__XXX
 SG_ EnggmntSttusTransInputShaftPTO2 : 36|2@1+ (1,0) [0|3] "" Vector__XXX
 SG_ EnggmntSttusTransOutputShaftPTO : 34|2@1+ (1,0) [0|3] "" Vector__XXX
 SG_ EnggmntSttsTrnsfrCsOtptShaftPTO : 32|2@1+ (1,0) [0|3] "" Vector__XXX
 SG_ EnggmntCnsntTransInputShaftPTO1 : 22|2@1+ (1,0) [0|3] "" Vector__XXX
 SG_ EnggmntCnsntTransInputShaftPTO2 : 20|2@1+ (1,0) [0|3] "" Vector__XXX
 SG_ EnggmntCnsntTransOutputShaftPTO : 18|2@1+ (1,0) [0|3] "" Vector__XXX
 SG_ EnggmntCnsntTrnsfrCsOtptShftPTO : 16|2@1+ (1,0) [0|3] "" Vector__XXX
 SG_ EnableSwitchTransInputShaftPTO1 : 6|2@1+ (1,0) [0|3] "" Vector__XXX
 SG_ EnableSwitchTransInputShaftPTO2 : 4|2@1+ (1,0) [0|3] "" Vector__XXX
 SG_ EnableSwitchTransOutputShaftPTO : 2|2@1+ (1,0) [0|3] "" Vector__XXX
 SG_ EnblSwtchTrnsfrCsOutputShaftPTO : 0|2@1+ (1,0) [0|3] "" Vector__XXX

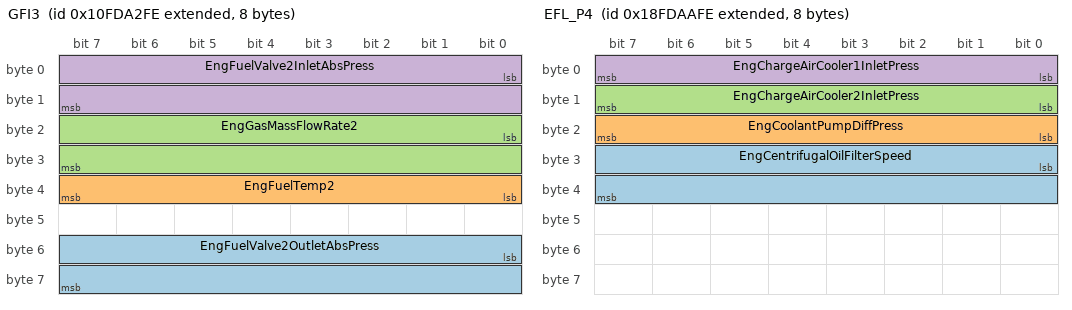
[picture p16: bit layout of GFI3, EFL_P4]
BO_ 2432541438 GFI3: 8 Vector__XXX
 SG_ EngFuelValve2OutletAbsPress : 48|16@1+ (0.1,0) [0|6425.5] "kPa" Vector__XXX
 SG_ EngFuelTemp2 : 32|8@1+ (1,-40) [-40|210] "deg" Vector__XXX
 SG_ EngGasMassFlowRate2 : 16|16@1+ (0.05,0) [0|3212.75] "kg/h" Vector__XXX
 SG_ EngFuelValve2InletAbsPress : 0|16@1+ (0.1,0) [0|6425.5] "kPa" Vector__XXX

BO_ 2566761214 EFL_P4: 8 Vector__XXX
 SG_ EngCentrifugalOilFilterSpeed : 24|16@1+ (4,0) [0|257020] "rpm" Vector__XXX
 SG_ EngCoolantPumpDiffPress : 16|8@1+ (1.64,-7) [-7|403] "kPa" Vector__XXX
 SG_ EngChargeAirCooler2InletPress : 8|8@1+ (2,0) [0|500] "kPa" Vector__XXX
 SG_ EngChargeAirCooler1InletPress : 0|8@1+ (2,0) [0|500] "kPa" Vector__XXX

BO_ 2432541694 EEC6: 8 Vector__XXX
 SG_ EngTurboCompressorCtrl : 0|16@1+ (0.0025,0) [0|160.6375] "%" Vector__XXX

BO_ 2566759934 DC2: 8 Vector__XXX
 SG_ EnableStatusOfDoor10 : 58|2@1+ (1,0) [0|3] "" Vector__XXX
 SG_ OpenStatusOfDoor10 : 56|2@1+ (1,0) [0|3] "" Vector__XXX
 SG_ LockStatusOfDoor10 : 54|2@1+ (1,0) [0|3] "" Vector__XXX
 SG_ EnableStatusOfDoor9 : 52|2@1+ (1,0) [0|3] "" Vector__XXX
 SG_ OpenStatusOfDoor9 : 50|2@1+ (1,0) [0|3] "" Vector__XXX
 SG_ LockStatusOfDoor9 : 48|2@1+ (1,0) [0|3] "" Vector__XXX
 SG_ EnableStatusOfDoor8 : 46|2@1+ (1,0) [0|3] "" Vector__XXX
 SG_ OpenStatusOfDoor8 : 44|2@1+ (1,0) [0|3] "" Vector__XXX
 SG_ LockStatusOfDoor8 : 42|2@1+ (1,0) [0|3] "" Vector__XXX
 SG_ EnableStatusOfDoor7 : 40|2@1+ (1,0) [0|3] "" Vector__XXX
 SG_ OpenStatusOfDoor7 : 38|2@1+ (1,0) [0|3] "" Vector__XXX
 SG_ LockStatusOfDoor7 : 36|2@1+ (1,0) [0|3] "" Vector__XXX
 SG_ EnableStatusOfDoor6 : 34|2@1+ (1,0) [0|3] "" Vector__XXX
 SG_ OpenStatusOfDoor6 : 32|2@1+ (1,0) [0|3] "" Vector__XXX
 SG_ LockStatusOfDoor6 : 30|2@1+ (1,0) [0|3] "" Vector__XXX
 SG_ EnableStatusOfDoor5 : 28|2@1+ (1,0) [0|3] "" Vector__XXX
 SG_ OpenStatusOfDoor5 : 26|2@1+ (1,0) [0|3] "" Vector__XXX
 SG_ LockStatusOfDoor5 : 24|2@1+ (1,0) [0|3] "" Vector__XXX
 SG_ EnableStatusOfDoor4 : 22|2@1+ (1,0) [0|3] "" Vector__XXX
 SG_ OpenStatusOfDoor4 : 20|2@1+ (1,0) [0|3] "" Vector__XXX
 SG_ LockStatusOfDoor4 : 18|2@1+ (1,0) [0|3] "" Vector__XXX
 SG_ EnableStatusOfDoor3 : 16|2@1+ (1,0) [0|3] "" Vector__XXX
 SG_ OpenStatusOfDoor3 : 14|2@1+ (1,0) [0|3] "" Vector__XXX
 SG_ LockStatusOfDoor3 : 12|2@1+ (1,0) [0|3] "" Vector__XXX
 SG_ EnableStatusOfDoor2 : 10|2@1+ (1,0) [0|3] "" Vector__XXX
 SG_ OpenStatusOfDoor2 : 8|2@1+ (1,0) [0|3] "" Vector__XXX
 SG_ LockStatusOfDoor2 : 6|2@1+ (1,0) [0|3] "" Vector__XXX
 SG_ EnableStatusOfDoor1 : 4|2@1+ (1,0) [0|3] "" Vector__XXX
 SG_ OpenStatusOfDoor1 : 2|2@1+ (1,0) [0|3] "" Vector__XXX
 SG_ LockStatusOfDoor1 : 0|2@1+ (1,0) [0|3] "" Vector__XXX

CM_ BU_ EMS "Engine Management System";
CM_ BU_ EAS "Exhaust Aftertreatment System";
CM_ BO_ 3221225472 "This is a message for not used signals, created by Vector CANdb++ DBC OLE DB Provider.";
CM_ SG_ 3221225472 AftrTrtmntOtltGsSnsorHeaterCtrl "Status message indicating the heater status in the warm-up process.Status message indicating the heater status in the warm-up process.";
CM_ SG_ 3221225472 AfterTreatmentOutletO2 "The actual oxidation factor (%O2) of the gas within the exhaust stream.The actual oxidation factor (%O2) of the gas within the exhaust stream.";
CM_ SG_ 3221225472 RoadSurfaceTemp "Indicated temperature of road surface over which vehicle is operating.Indicated temperature of road surface over which vehicle is operating.";
CM_ SG_ 3221225472 EngAirInletTemp "Temperature of air entering vehicle air induction system.Temperature of air entering vehicle air induction system.";
CM_ SG_ 3221225472 AmbientAirTemp "Temperature of air surrounding vehicle.Temperature of air surrounding vehicle.";
CM_ SG_ 3221225472 CabInteriorTemp "Temperature of air inside the part of the vehicle that encloses the driver and vehicle operating controls.Temperature of air inside the part of the vehicle that encloses the driver and vehicle operating controls.";
CM_ SG_ 3221225472 BarometricPress "Absolute air pressure of the atmosphere.Absolute air pressure of the atmosphere.";
CM_ SG_ 3221225472 EngStarterMode "There are several phases in a starting action and different reasons why a start cannot take place.There are several phases in a starting action and different reasons why a start cannot take place.";
CM_ SG_ 3221225472 SrcAddrssOfCtrllngDvcForEngCtrl "The source address of the SAE J1939 device currently controlling the engine.The source address of the SAE J1939 device currently controlling the engine.";
CM_ SG_ 3221225472 EngSpeed "Actual engine speed which is calculated over a minimum crankshaft angle of 720 degrees divided by the number of cylinders.Actual engine speed which is calculated over a minimum crankshaft angle of 720 degrees divided by the number of cylinders.";
CM_ SG_ 3221225472 DriversDemandEngPercentTorque "The requested torque output of the engine by the driver.The requested torque output of the engine by the driver.";
CM_ SG_ 3221225472 EngTorqueMode "State signal which indicates which engine torque mode is currently generating, limiting, or controlling the torque.State signal which indicates which engine torque mode is currently generating, limiting, or controlling the torque.";
CM_ SG_ 3221225472 SPN5 "SPN #5 (Conversion Version 4)SPN #5 (Conversion Version 4)SPN #5 (Conversion Version 4)";
CM_ SG_ 3221225472 SPN4 "SPN #4 (Conversion Version 4)SPN #4 (Conversion Version 4)SPN #4 (Conversion Version 4)";
CM_ SG_ 3221225472 SPN3 "SPN #3 (Conversion Version 4)SPN #3 (Conversion Version 4)SPN #3 (Conversion Version 4)";
CM_ SG_ 3221225472 SPN2 "SPN #2 (Conversion Version 4)SPN #2 (Conversion Version 4)SPN #2 (Conversion Version 4)";
CM_ SG_ 3221225472 FailureModeIdentifier5 "The FMI defines the type of failure detected in the subsystem identified by an SPN.The FMI defines the type of failure detected in the subsystem identified by an SPN.The FMI defines the type of failure detected in the subsystem identified by an SPN.";
CM_ SG_ 3221225472 FailureModeIdentifier4 "The FMI defines the type of failure detected in the subsystem identified by an SPN.The FMI defines the type of failure detected in the subsystem identified by an SPN.The FMI defines the type of failure detected in the subsystem identified by an SPN.";
CM_ SG_ 3221225472 FailureModeIdentifier3 "The FMI defines the type of failure detected in the subsystem identified by an SPN.The FMI defines the type of failure detected in the subsystem identified by an SPN.The FMI defines the type of failure detected in the subsystem identified by an SPN.";
CM_ SG_ 3221225472 FlashRedStopLamp "This parameter provides the capability to flash the RSL (SPN 3039).This parameter provides the capability to flash the RSL (SPN 3039).This parameter provides the capability to flash the RSL (SPN 3039).";
CM_ SG_ 3221225472 FlashProtectLamp "This parameter provides the capability to flash the engine protect lamp (SPN 3041).This parameter provides the capability to flash the engine protect lamp (SPN 3041).This parameter provides the capability to flash the engine protect lamp (SPN 3041).";
CM_ SG_ 3221225472 FlashMalfuncIndicatorLamp "This parameter provides the capability to flash the MIL (SPN 3038).This parameter provides the capability to flash the MIL (SPN 3038).This parameter provides the capability to flash the MIL (SPN 3038).";
CM_ SG_ 3221225472 FlashAmberWarningLamp "This parameter provides the capability to flash the AWL (SPN 3040). This parameter provides the capability to flash the AWL (SPN 3040). This parameter provides the capability to flash the AWL (SPN 3040). ";
CM_ SG_ 3221225472 MalfunctionIndicatorLampStatus "A lamp used to relay only emissions-related trouble code information.A lamp used to relay only emissions-related trouble code information.A lamp used to relay only emissions-related trouble code information.";
CM_ SG_ 3221225472 AmberWarningLampStatus "This lamp is used to relay trouble code information that is reporting a problem with the vehicle system but the vehicle need
not be immediately stopped.This lamp is used to relay trouble code information that is reporting a problem with the vehicle system but the vehicle need
not be immediately stopped.This lamp is used to relay trouble code information that is reporting a problem with the vehicle system but the vehicle need
not be immediately stopped.";
CM_ SG_ 3221225472 OccurenceCount1 "The 7 bit occurence count field contains the number of times a fault has gone from active to previously active.The 7 bit occurence count field contains the number of times a fault has gone from active to previously active.The 7 bit occurence count field contains the number of times a fault has gone from active to previously active.";
CM_ SG_ 3221225472 FailureModeIdentifier1 "The FMI defines the type of failure detected in the subsystem identified by an SPN.The FMI defines the type of failure detected in the subsystem identified by an SPN.The FMI defines the type of failure detected in the subsystem identified by an SPN.";
CM_ SG_ 3221225472 SPN1 "SPN #1 (Conversion Version 4)SPN #1 (Conversion Version 4)SPN #1 (Conversion Version 4)";
CM_ SG_ 3221225472 RedStopLampState "This lamp is uesed to relay trouble code information that is of a severe enought condition that it warrants stopping the vehicle.This lamp is uesed to relay trouble code information that is of a severe enought condition that it warrants stopping the vehicle.This lamp is uesed to relay trouble code information that is of a severe enought condition that it warrants stopping the vehicle.";
CM_ SG_ 3221225472 ProtectLampStatus "This lamp is used to relay trouble code informatio that is reporting a problem with a vehicle system that is most
probably not electronic subsystem related.This lamp is used to relay trouble code informatio that is reporting a problem with a vehicle system that is most
probably not electronic subsystem related.This lamp is used to relay trouble code informatio that is reporting a problem with a vehicle system that is most
probably not electronic subsystem related.";
CM_ SG_ 3221225472 FailureModeIdentifier2 "The FMI defines the type of failure detected in the subsystem identified by an SPN.The FMI defines the type of failure detected in the subsystem identified by an SPN.The FMI defines the type of failure detected in the subsystem identified by an SPN.";
CM_ SG_ 3221225472 OccurenceCount5 "The 7 bit occurence count field contains the number of times a fault has gone from active to previously active.The 7 bit occurence count field contains the number of times a fault has gone from active to previously active.The 7 bit occurence count field contains the number of times a fault has gone from active to previously active.";
CM_ SG_ 3221225472 OccurenceCount4 "The 7 bit occurence count field contains the number of times a fault has gone from active to previously active.The 7 bit occurence count field contains the number of times a fault has gone from active to previously active.The 7 bit occurence count field contains the number of times a fault has gone from active to previously active.";
CM_ SG_ 3221225472 OccurenceCount3 "The 7 bit occurence count field contains the number of times a fault has gone from active to previously active.The 7 bit occurence count field contains the number of times a fault has gone from active to previously active.The 7 bit occurence count field contains the number of times a fault has gone from active to previously active.";
CM_ SG_ 3221225472 OccurenceCount2 "The 7 bit occurence count field contains the number of times a fault has gone from active to previously active.The 7 bit occurence count field contains the number of times a fault has gone from active to previously active.The 7 bit occurence count field contains the number of times a fault has gone from active to previously active.";
CM_ SG_ 3221225472 SPN5High "SPN #5 (Conversion Version 4)SPN #5 (Conversion Version 4)SPN #5 (Conversion Version 4)";
CM_ SG_ 3221225472 SPN4High "SPN #4 (Conversion Version 4)SPN #4 (Conversion Version 4)SPN #4 (Conversion Version 4)";
CM_ SG_ 3221225472 SPN3High "SPN #3 (Conversion Version 4)SPN #3 (Conversion Version 4)SPN #3 (Conversion Version 4)";
CM_ SG_ 3221225472 SPN2High "SPN #2 (Conversion Version 4)SPN #2 (Conversion Version 4)SPN #2 (Conversion Version 4)";
CM_ SG_ 3221225472 SPN1High "SPN #1 (Conversion Version 4)SPN #1 (Conversion Version 4)SPN #1 (Conversion Version 4)";
CM_ SG_ 3221225472 EngAverageFuelEconomy "Average of instantaneous fuel economy for that segment of vehicle operation of interest.";
CM_ SG_ 3221225472 EngInstantaneousFuelEconomy "Current fuel economy at current vehicle velocity.";
CM_ SG_ 3221225472 EngFuelRate "Amount of fuel consumed by engine per unit of time.";
CM_ SG_ 3221225472 EngThrottlePos "The position of the valve used to regulate the supply of a fluid, usually air or fuel/air mixture, to an engine.";
CM_ SG_ 3221225472 EngInletAirMassFlowRate "Mass flow rate of fresh air entering the engine air intake, before any EGR mixer, if used.";
CM_ SG_ 3221225472 EngExhstGsRcrcltionMassFlowRate "Flow rate of gas through the EGR system.";
CM_ SG_ 3221225472 EngVrblGometryTurbo1ActuatorPos "Sensor that measures the position of the variable geometry turbocharger actuator.";
CM_ SG_ 3221225472 EngVrblGmtryTrbArCtrlShtffValve "Isolates vehicle brake air from the Variable Geometry Turbocharger (VGT) system when engine is not running.";
CM_ SG_ 3221225472 EngExhstGsRcirculationValveCtrl "Desired percentage of maximum Exhaust Gas Recirculation (EGR) valve opening.";
CM_ SG_ 3221225472 EngTrb1ClcltedTurbineOutletTemp "Calculated value of turbocharger compressor outlet air temperature.";
CM_ SG_ 3221225472 ExhaustGasMass "Measured/calculated exhaust gas mass upstream of the after-treatment system.";
CM_ SG_ 3221225472 EngsDesiredOperatingSpeed "An indication by the engine of the optimal operating speed of the engine for the current existing conditions.";
CM_ SG_ 3221225472 CatalystTankLevelPreliminaryFMI "Used to identify the applicable J1939-73 FMI that applies to the most significant failure of the catalyst tank level sensor.";
CM_ SG_ 3221225472 CatalystTankLevel2 "The measure of the reagent level in the catalyst tank.";
CM_ SG_ 3221225472 EngExhaustGasTemp "Temperature of combustion byproducts leaving the engine.";
CM_ SG_ 3221225472 EngAirInletPress "Absolute air pressure at inlet to intake manifold or air box.";
CM_ SG_ 3221225472 EngIntakeManifold1Temp "Temperature of pre-combustion air found in intake manifold of engine air supply system.";
CM_ SG_ 3221225472 EngTurboBoostPress "Gage pressure of air measured downstream on the compressor discharge side of the turbocharger.";
CM_ SG_ 3221225472 EngParticulateTrapInletPress "Exhaust back pressure as a result of particle accumulation on filter media placed in the exhaust stream.";
CM_ SG_ 3221225472 EngIntercoolerThermostatOpening "The current position of the thermostat used to regulate the temperature of the engine intercooler.";
CM_ SG_ 3221225472 EngIntercoolerTemp "Temperature of liquid found in the intercooler located after the turbocharger.";
CM_ SG_ 3221225472 EngTurboOilTemp "Temperature of the turbocharger lubricant.";
CM_ SG_ 3221225472 EngOilTemp1 "Temperature of the engine lubricant.";
CM_ SG_ 3221225472 EngFuelTemp "Temperature of fuel entering injectors.";
CM_ SG_ 3221225472 EngCoolantTemp "Temperature of liquid found in engine cooling system.";
CM_ SG_ 3221225472 ActualEngPercentTorque "The calculated output torque of the engine.";
CM_ BO_ 2565406525 "Acknowledgment Message";
CM_ SG_ 2565406525 ParameterGroupNumber "PGN which is requested by Request2 message";
CM_ SG_ 2565406525 GroupFunctionValue "Indicates the acknowledgement response.Indicates the acknowledgement response.Negative Acknowledgement Group Function valuePositive Acknowledgement Group Function value";
CM_ BO_ 2565799680 "Address Claimed";
CM_ BO_ 2565603133 "Transport Protocol - Data Transfer";
CM_ BO_ 2565668669 "Transport Protocol - Connection Management";
CM_ SG_ 2565668669 TotalNumberOfPacketsEoMA "Total number of packets for BAM message.Total number of packets received for RTS/CTS message.Total number of packets for RTS/CTS message.";
CM_ SG_ 2565668669 TotalMessageSizeEoMA "Total message size (in bytes) for BAM message.Total message size (in bytes) for RTS/CTS message.Total message size (in bytes) for RTS/CTS message.";
CM_ SG_ 2565668669 TotalMessageSizeBAM "Total message size (in bytes) for BAM message.Total message size (in bytes) for RTS/CTS message.Total message size (in bytes) for RTS/CTS message.";
CM_ SG_ 2565668669 TotalNumberOfPacketsBAM "Total number of packets for BAM message.Total number of packets received for RTS/CTS message.Total number of packets for RTS/CTS message.";
CM_ SG_ 2565668669 ConnectionAbortReason "Reason for connection abort message.";
CM_ SG_ 2565668669 NextPacketNumberToBeSent "Next Packet Number to be sent (TP.CM_CTS)";
CM_ SG_ 2565668669 NumberOfPacketsThatCanBeSent "Number of Packets that can be sent (TP.CM_CTS)";
CM_ SG_ 2565668669 MaximumNumberOfPackets "Maximum number of packets for RTS/CTS message.";
CM_ SG_ 2565668669 TotalNumberOfPackets "Total number of packets for BAM message.Total number of packets received for RTS/CTS message.Total number of packets for RTS/CTS message.";
CM_ SG_ 2565668669 TotalMessageSize "Total message size (in bytes) for BAM message.Total message size (in bytes) for RTS/CTS message.Total message size (in bytes) for RTS/CTS message.";
CM_ BO_ 2565799741 "Address Claimed";
CM_ BO_ 2565869312 "After Treatment Outlet Gas 1";
CM_ SG_ 2565869312 AftrTrtmntOtltGsSnsorHeaterCtrl "Status message indicating the heater status in the warm-up process.";
CM_ SG_ 2565869312 AfterTreatmentOutletO2 "The actual oxidation factor (%O2) of the gas within the exhaust stream.";
CM_ BO_ 2566843904 "Engine Temperature 1";
CM_ SG_ 2566843904 EngIntercoolerThermostatOpening "The current position of the thermostat used to regulate the temperature of the engine intercooler.";
CM_ SG_ 2566843904 EngIntercoolerTemp "Temperature of liquid found in the intercooler located after the turbocharger.";
CM_ SG_ 2566843904 EngTurboOilTemp "Temperature of the turbocharger lubricant.";
CM_ SG_ 2566843904 EngOilTemp1 "Temperature of the engine lubricant.";
CM_ SG_ 2566843904 EngFuelTemp "Temperature of fuel entering injectors.";
CM_ SG_ 2566843904 EngCoolantTemp "Temperature of liquid found in engine cooling system.";
CM_ BO_ 2566845696 "Ambient Conditions";
CM_ SG_ 2566845696 RoadSurfaceTemp "Indicated temperature of road surface over which vehicle is operating.";
CM_ SG_ 2566845696 EngAirInletTemp "Temperature of air entering vehicle air induction system.";
CM_ SG_ 2566845696 AmbientAirTemp "Temperature of air surrounding vehicle.";
CM_ SG_ 2566845696 CabInteriorTemp "Temperature of air inside the part of the vehicle that encloses the driver and vehicle operating controls.";
CM_ SG_ 2566845696 BarometricPress "Absolute air pressure of the atmosphere.";
CM_ BO_ 2364539904 "Electronic Engine Controller 1";
CM_ SG_ 2364539904 EngStarterMode "There are several phases in a starting action and different reasons why a start cannot take place.";
CM_ SG_ 2364539904 SrcAddrssOfCtrllngDvcForEngCtrl "The source address of the SAE J1939 device currently controlling the engine.";
CM_ SG_ 2364539904 EngSpeed "Actual engine speed which is calculated over a minimum crankshaft angle of 720 degrees divided by the number of cylinders.";
CM_ SG_ 2364539904 ActualEngPercentTorque "The calculated output torque of the engine.";
CM_ SG_ 2364539904 DriversDemandEngPercentTorque "The requested torque output of the engine by the driver.";
CM_ SG_ 2364539904 EngTorqueMode "State signal which indicates which engine torque mode is currently generating, limiting, or controlling the torque.";
CM_ BO_ 2566835005 "Previously active diagnostic trouble codes";
CM_ SG_ 2566835005 SPN5 "SPN #5 (Conversion Version 4)";
CM_ SG_ 2566835005 SPN4 "SPN #4 (Conversion Version 4)";
CM_ SG_ 2566835005 SPN3 "SPN #3 (Conversion Version 4)";
CM_ SG_ 2566835005 SPN2 "SPN #2 (Conversion Version 4)";
CM_ SG_ 2566835005 FailureModeIdentifier5 "The FMI defines the type of failure detected in the subsystem identified by an SPN.";
CM_ SG_ 2566835005 FailureModeIdentifier4 "The FMI defines the type of failure detected in the subsystem identified by an SPN.";
CM_ SG_ 2566835005 OccurenceCount1 "The 7 bit occurence count field contains the number of times a fault has gone from active to previously active.";
CM_ SG_ 2566835005 FailureModeIdentifier1 "The FMI defines the type of failure detected in the subsystem identified by an SPN.";
CM_ SG_ 2566835005 SPN1 "SPN #1 (Conversion Version 4)";
CM_ SG_ 2566835005 MalfunctionIndicatorLampStatus "A lamp used to relay only emissions-related trouble code information.";
CM_ SG_ 2566835005 RedStopLampState "This lamp is uesed to relay trouble code information that is of a severe enought condition that it warrants stopping the vehicle.";
CM_ SG_ 2566835005 AmberWarningLampStatus "This lamp is used to relay trouble code information that is reporting a problem with the vehicle system but the vehicle need
not be immediately stopped.";
CM_ SG_ 2566835005 ProtectLampStatus "This lamp is used to relay trouble code informatio that is reporting a problem with a vehicle system that is most
probably not electronic subsystem related.";
CM_ SG_ 2566835005 FailureModeIdentifier3 "The FMI defines the type of failure detected in the subsystem identified by an SPN.";
CM_ SG_ 2566835005 FlashRedStopLamp "This parameter provides the capability to flash the RSL (SPN 3039).";
CM_ SG_ 2566835005 FlashProtectLamp "This parameter provides the capability to flash the engine protect lamp (SPN 3041).";
CM_ SG_ 2566835005 FlashMalfuncIndicatorLamp "This parameter provides the capability to flash the MIL (SPN 3038).";
CM_ SG_ 2566835005 FlashAmberWarningLamp "This parameter provides the capability to flash the AWL (SPN 3040). ";
CM_ SG_ 2566835005 FailureModeIdentifier2 "The FMI defines the type of failure detected in the subsystem identified by an SPN.";
CM_ SG_ 2566835005 OccurenceCount5 "The 7 bit occurence count field contains the number of times a fault has gone from active to previously active.";
CM_ SG_ 2566835005 OccurenceCount4 "The 7 bit occurence count field contains the number of times a fault has gone from active to previously active.";
CM_ SG_ 2566835005 OccurenceCount3 "The 7 bit occurence count field contains the number of times a fault has gone from active to previously active.";
CM_ SG_ 2566835005 OccurenceCount2 "The 7 bit occurence count field contains the number of times a fault has gone from active to previously active.";
CM_ SG_ 2566835005 SPN5High "SPN #5 (Conversion Version 4)";
CM_ SG_ 2566835005 SPN4High "SPN #4 (Conversion Version 4)";
CM_ SG_ 2566835005 SPN3High "SPN #3 (Conversion Version 4)";
CM_ SG_ 2566835005 SPN2High "SPN #2 (Conversion Version 4)";
CM_ SG_ 2566835005 SPN1High "SPN #1 (Conversion Version 4)";
CM_ BO_ 2566834749 "Active diagnostic trouble codes";
CM_ SG_ 2566834749 SPN5 "SPN #5 (Conversion Version 4)";
CM_ SG_ 2566834749 SPN4 "SPN #4 (Conversion Version 4)";
CM_ SG_ 2566834749 SPN3 "SPN #3 (Conversion Version 4)";
CM_ SG_ 2566834749 SPN2 "SPN #2 (Conversion Version 4)";
CM_ SG_ 2566834749 FailureModeIdentifier5 "The FMI defines the type of failure detected in the subsystem identified by an SPN.";
CM_ SG_ 2566834749 FailureModeIdentifier4 "The FMI defines the type of failure detected in the subsystem identified by an SPN.";
CM_ SG_ 2566834749 FailureModeIdentifier3 "The FMI defines the type of failure detected in the subsystem identified by an SPN.";
CM_ SG_ 2566834749 FlashRedStopLamp "This parameter provides the capability to flash the RSL (SPN 3039).";
CM_ SG_ 2566834749 FlashProtectLamp "This parameter provides the capability to flash the engine protect lamp (SPN 3041).";
CM_ SG_ 2566834749 FlashMalfuncIndicatorLamp "This parameter provides the capability to flash the MIL (SPN 3038).";
CM_ SG_ 2566834749 FlashAmberWarningLamp "This parameter provides the capability to flash the AWL (SPN 3040). ";
CM_ SG_ 2566834749 MalfunctionIndicatorLampStatus "A lamp used to relay only emissions-related trouble code information.";
CM_ SG_ 2566834749 AmberWarningLampStatus "This lamp is used to relay trouble code information that is reporting a problem with the vehicle system but the vehicle need
not be immediately stopped.";
CM_ SG_ 2566834749 OccurenceCount1 "The 7 bit occurence count field contains the number of times a fault has gone from active to previously active.";
CM_ SG_ 2566834749 FailureModeIdentifier1 "The FMI defines the type of failure detected in the subsystem identified by an SPN.";
CM_ SG_ 2566834749 SPN1 "SPN #1 (Conversion Version 4)";
CM_ SG_ 2566834749 RedStopLampState "This lamp is uesed to relay trouble code information that is of a severe enought condition that it warrants stopping the vehicle.";
CM_ SG_ 2566834749 ProtectLampStatus "This lamp is used to relay trouble code informatio that is reporting a problem with a vehicle system that is most
probably not electronic subsystem related.";
CM_ SG_ 2566834749 FailureModeIdentifier2 "The FMI defines the type of failure detected in the subsystem identified by an SPN.";
CM_ SG_ 2566834749 OccurenceCount5 "The 7 bit occurence count field contains the number of times a fault has gone from active to previously active.";
CM_ SG_ 2566834749 OccurenceCount4 "The 7 bit occurence count field contains the number of times a fault has gone from active to previously active.";
CM_ SG_ 2566834749 OccurenceCount3 "The 7 bit occurence count field contains the number of times a fault has gone from active to previously active.";
CM_ SG_ 2566834749 OccurenceCount2 "The 7 bit occurence count field contains the number of times a fault has gone from active to previously active.";
CM_ SG_ 2566834749 SPN5High "SPN #5 (Conversion Version 4)";
CM_ SG_ 2566834749 SPN4High "SPN #4 (Conversion Version 4)";
CM_ SG_ 2566834749 SPN3High "SPN #3 (Conversion Version 4)";
CM_ SG_ 2566834749 SPN2High "SPN #2 (Conversion Version 4)";
CM_ SG_ 2566834749 SPN1High "SPN #1 (Conversion Version 4)";
CM_ BO_ 2633938942 "Engine Speed/Load Factor Information";
CM_ SG_ 2633938942 TotalEngCruiseTime "Total time that the engine has operated in the cruise hold state, excluding time in accelerator override, over the life of the engine.";
CM_ SG_ 2633938942 TripAverageEngSpeed "Average speed of the engine since the last trip reset.";
CM_ SG_ 2633938942 TripMaxEngSpeed "Maximum engine speed achieved since the last trip reset.";
CM_ BO_ 2566799614 "Lighting Data";
CM_ SG_ 2566799614 ImplementRearWorkLight "This parameter provides measured data from the implement rear work lamps.";
CM_ SG_ 2566799614 ImplementLeftForwardWorkLight "This parameter provides measured data from the forward facing work lights toward the left end of the implement.";
CM_ SG_ 2566799614 ImplementRightForwardWorkLight "This parameter provides measured data from the forward facing work lights toward the right end of the implement.";
CM_ SG_ 2566799614 ImplementOEMOption1Light "This parameter provides measured data from the implement OEM option 1 light.";
CM_ SG_ 2566799614 ImplementOEMOption2Light "This parameter provides measured data from the implement OEM option 2 light.";
CM_ SG_ 2566799614 TrctrFrontHighMountedWorkLights "This parameter provides measured data from the tractor front high mounted work lights.";
CM_ SG_ 2566799614 TrctorFrontLowMountedWorkLights "This parameter provides measured data from the tractor front low mounted work lights.";
CM_ SG_ 2566799614 TrctorSideHighMountedWorkLights "This parameter provides measured data from the tractor side high mounted work lights.";
CM_ SG_ 2566799614 TractorSideLowMountedWorkLights "This parameter provides measured data from the tractor side low mounted work lights.";
CM_ SG_ 2566799614 TrctorRearHighMountedWorkLights "This parameter provides measured data from the tractor rear high mounted work lights.";
CM_ SG_ 2566799614 TractorRearLowMountedWorkLights "This parameter provides measured data from the tractor rear low mounted work lights.";
CM_ SG_ 2566799614 TrctrUndersideMountedWorkLights "This parameter provides measured data from the tractor underside mounted work lights.";
CM_ SG_ 2566799614 RearFogLights "This parameter provides measured data from the tractor and/or implement rear fog lights.";
CM_ SG_ 2566799614 TractorClearanceLight "This parameter provides measured data from the tractor high mounted clearance and center ID lights.";
CM_ SG_ 2566799614 ImplementClearanceLight "This parameter provides measured data from an attached implement high mounted clearance lights.";
CM_ SG_ 2566799614 LeftStopLight "This parameter provides measured data from the tractor and attached implement left stop lights.";
CM_ SG_ 2566799614 RightStopLight "This parameter provides measured data from the tractor and attached implement right stop lights.";
CM_ SG_ 2566799614 CenterStopLight "This parameter provides measured data from the tractor and attached implement center stop lights.";
CM_ SG_ 2566799614 BackUpLightAndAlarmHorn "This parameter provides measured data from the back up lights and/ or associated alarm.";
CM_ SG_ 2566799614 LeftTurnSignalLights "This parameter provides measured data from the tractor and attached implement left turn signal lights.";
CM_ SG_ 2566799614 RightTurnSignalLights "This parameter provides measured data from the tractor and attached implement right turn signal lights.";
CM_ SG_ 2566799614 RotatingBeaconLight "This parameter provides measured data from the beacon light on tractor or attached implements.";
CM_ SG_ 2566799614 TractorFrontFogLights "This parameter provides measured data from the tractor front fog lights.";
CM_ SG_ 2566799614 HighBeamHeadLightData "This parameter provides measured data from the tractor high beam head light lamps.";
CM_ SG_ 2566799614 LowBeamHeadLightData "This parameter provides measured data from the tractor low beam head light lamps.";
CM_ SG_ 2566799614 AltBeamHeadLightData "This parameter provides measured data from the tractor alternate beam head light lamps.";
CM_ SG_ 2566799614 RunningLight "This parameter provides measured data from the vehicle’s running lights.";
CM_ BO_ 2365473278 "Lighting Command";
CM_ SG_ 2365473278 ImplementRearWorkLightCmd "Command to activate or de-activate implement rear work lights.";
CM_ SG_ 2365473278 ImplmentLeftForwardWorkLightCmd "Command to activate or de-activate the forward facing work lights toward the left end of the implement.";
CM_ SG_ 2365473278 ImplmntRightForwardWorkLightCmd "Command to activate or de-activate the forward facing work lights toward the right end of the implement.";
CM_ SG_ 2365473278 ImplementLeftFacingWorkLightCmd "Command to activate or de-activate work lights mounted on an implement to illuminate beyond left end of the implement.";
CM_ SG_ 2365473278 ImplmentRightFacingWorkLightCmd "Command to activate or de-activate work lights mounted on an implement to illuminate beyond right end of the implement.";
CM_ SG_ 2365473278 ImplementOEMOption1LightCmd "Command to activate or de-activate an implement OEM option 1 light.";
CM_ SG_ 2365473278 ImplementOEMOption2LightCmd "Command to activate or de-activate an implement OEM option 2 light.";
CM_ SG_ 2365473278 TrctrFrntHghMuntedWorkLightsCmd "Command to activate or de-activate the tractor front high mounted work lights.";
CM_ SG_ 2365473278 TrctrFrntLwMountedWorkLightsCmd "Command to activate or de-activate the tractor front low mounted work lights.";
CM_ SG_ 2365473278 TrctrSdHighMountedWorkLightsCmd "Command to activate or de-activate the tractor side high mounted work lights.";
CM_ SG_ 2365473278 TrctrSdeLowMountedWorkLightsCmd "Command to activate or de-activate the tractor side low mounted work lights.";
CM_ SG_ 2365473278 TrctrRrHighMountedWorkLightsCmd "Command to activate or de-activate the tractor rear high mounted work lights.";
CM_ SG_ 2365473278 TrctrRarLowMountedWorkLightsCmd "Command to activate or de-activate the tractor rear low mounted work lights.";
CM_ SG_ 2365473278 TrctrUndrsdMountedWorkLightsCmd "Command to activate or de-activate the tractor underside mounted work lights.";
CM_ SG_ 2365473278 RearFogLightCmd "Command to activate or de-activate tractor or implement rear fog lights.";
CM_ SG_ 2365473278 ImplementClearanceLightCmd "Command to activate or de-activate the implement high mounted clearance and lights.";
CM_ SG_ 2365473278 RotatingBeaconLightCmd "Command to activate or de-activate slow moving vehicle indicator lights on tractor and/or implements.";
CM_ SG_ 2365473278 TractorFrontFogLightsCmd "Command to activate or de-activate tractor front fog lights.";
CM_ SG_ 2365473278 HighBeamHeadLightCmd "Command to activate or de-activate the tractor high beam head light lamps.";
CM_ SG_ 2365473278 LowBeamHeadLightCmd "Command to activate or de-activate the tractor low beam head light lamps.";
CM_ SG_ 2365473278 AltBeamHeadLightCmd "Command to activate or de-activate the tractor alternate head lights (only low beam is available on alternate head lights).";
CM_ SG_ 2365473278 RunningLightCmd "Command to activate or de-activate the tractor or powered vehicle running lights.";
CM_ BO_ 2365485822 "Laser Leveling System Blade Control";
CM_ SG_ 2365485822 BladeCtrlMode "Allows the user to select the type of blade control for the land leveling system.";
CM_ SG_ 2365485822 BladeDurationAndDirection "Used to indicate the duration and direction that the land leveling system blade moves.";
CM_ BO_ 2633926654 "Ignition Timing 6";
CM_ SG_ 2633926654 EngActualIgntTiming "The actual ignition timing at the current engine conditions.";
CM_ SG_ 2633926654 EngDesiredIgntTiming3 "A programmable timing value specific to the engine’s application.";
CM_ SG_ 2633926654 EngDesiredIgntTiming2 "A programmable timing value specific to the engine’s application.";
CM_ SG_ 2633926654 EngDesiredIgntTiming1 "A programmable timing value specific to the engine’s application.";
CM_ BO_ 2633926398 "Ignition Timing 5";
CM_ SG_ 2633926398 EngCyl20IgntTiming "The ignition timing of the cylinder.";
CM_ SG_ 2633926398 EngCyl19IgntTiming "The ignition timing of the cylinder.";
CM_ SG_ 2633926398 EngCyl18IgntTiming "The ignition timing of the cylinder.";
CM_ SG_ 2633926398 EngCyl17IgntTiming "The ignition timing of the cylinder.";
CM_ BO_ 2633926142 "Ignition Timing 4";
CM_ SG_ 2633926142 EngCyl16IgntTiming "The ignition timing of the cylinder.";
CM_ SG_ 2633926142 EngCyl15IgntTiming "The ignition timing of the cylinder.";
CM_ SG_ 2633926142 EngCyl14IgntTiming "The ignition timing of the cylinder.";
CM_ SG_ 2633926142 EngCyl13IgntTiming "The ignition timing of the cylinder.";
CM_ BO_ 2633925886 "Ignition Timing 3";
CM_ SG_ 2633925886 EngCyl12IgntTiming "The ignition timing of the cylinder.";
CM_ SG_ 2633925886 EngCyl11IgntTiming "The ignition timing of the cylinder.";
CM_ SG_ 2633925886 EngCyl10IgntTiming "The ignition timing of the cylinder.";
CM_ SG_ 2633925886 EngCyl9IgntTiming "The ignition timing of the cylinder.";
CM_ BO_ 2633925630 "Ignition Timing 2";
CM_ SG_ 2633925630 EngCyl8IgntTiming "The ignition timing of the cylinder.";
CM_ SG_ 2633925630 EngCyl7IgntTiming "The ignition timing of the cylinder.";
CM_ SG_ 2633925630 EngCyl6IgntTiming "The ignition timing of the cylinder.";
CM_ SG_ 2633925630 EngCyl5IgntTiming "The ignition timing of the cylinder.";
CM_ BO_ 2633925374 "Ignition Timing 1";
CM_ SG_ 2633925374 EngCyl4IgntTiming "The ignition timing of the cylinder.";
CM_ SG_ 2633925374 EngCyl3IgntTiming "The ignition timing of the cylinder.";
CM_ SG_ 2633925374 EngCyl2IgntTiming "The ignition timing of the cylinder.";
CM_ SG_ 2633925374 EngCyl1IgntTiming "The ignition timing of the cylinder.";
CM_ BO_ 2633927422 "Ignition Transformer Secondary Output 3";
CM_ SG_ 2633927422 EngCyl20IgntTransSecondOutput "This parameter indicates the relative intensity of the secondary output voltage of the ignition transformer.";
CM_ SG_ 2633927422 EngCyl19IgntTransSecondOutput "This parameter indicates the relative intensity of the secondary output voltage of the ignition transformer.";
CM_ SG_ 2633927422 EngCyl18IgntTransSecondOutput "This parameter indicates the relative intensity of the secondary output voltage of the ignition transformer.";
CM_ SG_ 2633927422 EngCyl17IgntTransSecondOutput "This parameter indicates the relative intensity of the secondary output voltage of the ignition transformer.";
CM_ BO_ 2633927166 "Ignition Transformer Secondary Output 2";
CM_ SG_ 2633927166 EngCyl16IgntTransSecondOutput "This parameter indicates the relative intensity of the secondary output voltage of the ignition transformer.";
CM_ SG_ 2633927166 EngCyl15IgntTransSecondOutput "This parameter indicates the relative intensity of the secondary output voltage of the ignition transformer.";
CM_ SG_ 2633927166 EngCyl14IgntTransSecondOutput "This parameter indicates the relative intensity of the secondary output voltage of the ignition transformer.";
CM_ SG_ 2633927166 EngCyl13IgntTransSecondOutput "This parameter indicates the relative intensity of the secondary output voltage of the ignition transformer.";
CM_ SG_ 2633927166 EngCyl12IgntTransSecondOutput "This parameter indicates the relative intensity of the secondary output voltage of the ignition transformer.";
CM_ SG_ 2633927166 EngCyl11IgntTransSecondOutput "This parameter indicates the relative intensity of the secondary output voltage of the ignition transformer.";
CM_ SG_ 2633927166 EngCyl10IgntTransSecondOutput "This parameter indicates the relative intensity of the secondary output voltage of the ignition transformer.";
CM_ SG_ 2633927166 EngCyl9IgntTransSecondOutput "This parameter indicates the relative intensity of the secondary output voltage of the ignition transformer.";
CM_ BO_ 2633926910 "Ignition Transformer Secondary Output 1";
CM_ SG_ 2633926910 EngCyl8IgntTransSecondOutput "This parameter indicates the relative intensity of the secondary output voltage of the ignition transformer.";
CM_ SG_ 2633926910 EngCyl7IgntTransSecondOutput "This parameter indicates the relative intensity of the secondary output voltage of the ignition transformer.";
CM_ SG_ 2633926910 EngCyl6IgntTransSecondOutput "This parameter indicates the relative intensity of the secondary output voltage of the ignition transformer.";
CM_ SG_ 2633926910 EngCyl5IgntTransSecondOutput "This parameter indicates the relative intensity of the secondary output voltage of the ignition transformer.";
CM_ SG_ 2633926910 EngCyl4IgntTransSecondOutput "This parameter indicates the relative intensity of the secondary output voltage of the ignition transformer.";
CM_ SG_ 2633926910 EngCyl3IgntTransSecondOutput "This parameter indicates the relative intensity of the secondary output voltage of the ignition transformer.";
CM_ SG_ 2633926910 EngCyl2IgntTransSecondOutput "This parameter indicates the relative intensity of the secondary output voltage of the ignition transformer.";
CM_ SG_ 2633926910 EngCyl1IgntTransSecondOutput "This parameter indicates the relative intensity of the secondary output voltage of the ignition transformer.";
CM_ BO_ 2566768894 "Operator Primary Intermediate Speed Control state";
CM_ SG_ 2566768894 EngOprtrPrmryIntrmdtSpdSlctStte "13 preprogrammed intermediate speed control settings are availible for the contolling ECM to select.";
CM_ BO_ 2566769406 "Intermediate Speed Control";
CM_ SG_ 2566769406 EngOprtrPrmryIntrmdtSpeedSelect "Allows the operator to select one of 13 preprogrammed Intermediate Speed Control settings.";
CM_ BO_ 2566839550 "Idle Operation";
CM_ SG_ 2566839550 EngTotalIdleHours "Accumulated time of operation of the engine while under idle conditions.";
CM_ SG_ 2566839550 EngTotalIdleFuelUsed "Accumulated amount of fuel used during vehicle operation while under idle conditions.";
CM_ BO_ 2633934334 "Intake Manifold Information 2";
CM_ SG_ 2633934334 EngIntakeManifold6Temp "Temperature of pre-combustion air found in intake manifold number 6 of engine air supply system.";
CM_ SG_ 2633934334 EngIntakeManifold5Temp "Temperature of pre-combustion air found in intake manifold number 5 of engine air supply system.";
CM_ SG_ 2633934334 EngIntakeManifold4Temp "Temperature of pre-combustion air found in intake manifold of engine air supply system.";
CM_ SG_ 2633934334 EngIntakeManifold3Temp "Temperature of pre-combustion air found in intake manifold of engine air supply system.";
CM_ SG_ 2633934334 EngIntakeManifold2Temp "Temperature of pre-combustion air found in intake manifold of engine air supply system.";
CM_ BO_ 2566825726 "Intake Manifold Information 1";
CM_ SG_ 2566825726 EngTurbo4BoostPress "Gage pressure of air measured downstream of the compressor discharge side of the turbocharger.";
CM_ SG_ 2566825726 EngTurbo3BoostPress "Gage pressure of air measured downstream of the compressor discharge side of the turbocharger.";
CM_ SG_ 2566825726 EngTurbo2BoostPress "Gage pressure of air measured downstream of the compressor discharge side of the turbocharger.";
CM_ SG_ 2566825726 EngTurbo1BoostPress "Gage pressure of air measured downstream of the compressor discharge side of the turbocharger.";
CM_ BO_ 2566770942 "Inlet/Exhaust Conditions 2";
CM_ BO_ 2566846206 "Inlet/Exhaust Conditions 1";
CM_ SG_ 2566846206 EngExhaustGasTemp "Temperature of combustion byproducts leaving the engine.";
CM_ SG_ 2566846206 EngAirInletPress "Absolute air pressure at inlet to intake manifold or air box.";
CM_ SG_ 2566846206 EngIntakeManifold1Temp "Temperature of pre-combustion air found in intake manifold of engine air supply system.";
CM_ SG_ 2566846206 EngTurboBoostPress "Gage pressure of air measured downstream on the compressor discharge side of the turbocharger.";
CM_ SG_ 2566846206 EngParticulateTrapInletPress "Exhaust back pressure as a result of particle accumulation on filter media placed in the exhaust stream.";
CM_ BO_ 2566811134 "Heater Information";
CM_ SG_ 2566811134 CabHeatingZone "Parameter indicating whether the cab zone is being heated.";
CM_ SG_ 2566811134 EngHeatingZone "Parameter indicating whether the engine zone is being heated.";
CM_ SG_ 2566811134 CabVentilation "Indicates whether the cab is being ventilated or not.";
CM_ SG_ 2566811134 AuxHeaterOutputPowerPercent "Current auxiliary heater output power, relative to the auxiliary heater maximum output power.";
CM_ SG_ 2566811134 AuxHeaterInputAirTemp "Temperature of the input air in an auxiliary heater system.";
CM_ SG_ 2566811134 AuxHeaterOutputCoolantTemp "Temperature of the auxiliary heater output coolant (I.";
CM_ BO_ 2298375934 "High Resolution Wheel Speed";
CM_ SG_ 2298375934 RearAxleRightWheelSpeed "High resolution measurement of the speed of the right wheel on the rear axle.";
CM_ SG_ 2298375934 RearAxleLeftWheelSpeed "High resolution measurement of the speed of the left wheel on the rear axle.";
CM_ SG_ 2298375934 FrontAxleRightWheelSpeed "High resolution measurement of the speed of the right wheel on the front axle.";
CM_ SG_ 2298375934 FrontAxleLeftWheelSpeed "High resolution measurement of the speed of the left wheel on the front axle.";
CM_ BO_ 2565867774 "Hydraulic Pressure Governor Info";
CM_ SG_ 2565867774 EngHydPrssGovernorModeIndicator "Mode for governor operation is hydraulic pressure control.";
CM_ SG_ 2565867774 HydPress "Hydraulic pressure measured at the output of the hydraulic pump.";
CM_ BO_ 2566841854 "Engine Hours, Revolutions";
CM_ SG_ 2566841854 EngTotalRevolutions "Accumulated number of revolutions of engine crankshaft during its operation.";
CM_ SG_ 2566841854 EngTotalHoursOfOperation "Accumulated time of operation of engine.";
CM_ BO_ 2365449982 "Hydraulic Braking System";
CM_ SG_ 2365449982 HydBrakeFluidLevelSwitch "Signal which indicates whether the hydraulic fluid level in the reservoir(s) is sufficient.";
CM_ SG_ 2365449982 HydBrakeSystemAudibleWarningCmd "Signal which commands an audible warning by the hydraulic braking system.";
CM_ BO_ 2633939198 "Trip Fuel Information (Gaseous)";
CM_ SG_ 2633939198 TripCruiseFuelUsed "Total fuel consumed while the engine is in the cruise hold state since the last trip reset.";
CM_ BO_ 2633927678 "Gaseous Fuel Pressure";
CM_ SG_ 2633927678 EngFuelValve1OutletAbsPress "Absolute Pressure of gas on outlet side of the first or only fuel system control valve.";
CM_ SG_ 2633927678 EngAirToFuelDiffPress "The differential pressure between the gaseous fuel and the air intake manifold.";
CM_ SG_ 2633927678 EngFuelValveDiffPress "The differential pressure between the inlet and the outlet of a gaseous fuel valve.";
CM_ SG_ 2633927678 EngFuelValveInletAbsPress "The absolute pressure at the inlet of the gaseous fuel valve.";
CM_ BO_ 2633925118 "Fuel Information 2 (Gaseous)";
CM_ SG_ 2633925118 EngFuelFlowRate2 "The rate at which the fuel is flowing through a fuel valve.";
CM_ SG_ 2633925118 EngFuelFlowRate1 "The rate at which the fuel is flowing through a fuel valve.";
CM_ SG_ 2633925118 EngRqedFuelValve1Pos "The requested position of a gaseous fuel valve 1 that is metering the fuel flow to the engine.";
CM_ SG_ 2633925118 EngFuelValve2Pos "The position of a gaseous fuel valve that is metering the fuel flow to the engine.";
CM_ SG_ 2633925118 EngFuelValve1Pos "The position of a gaseous fuel valve that is metering the fuel flow to the engine.";
CM_ BO_ 2633937662 "Fuel Information 1 (Gaseous)";
CM_ SG_ 2633937662 EngFuelSpecificGravity "This parameter conveys the specific gravity of the gaseous fuel being used by the engine.";
CM_ SG_ 2633937662 TripAverageFuelRate "Average fuel rate, equal to trip fuel divided by trip time while the engine speed is above zero, since the last trip reset.";
CM_ SG_ 2633937662 TotalEngPTOFuelUsed "Total fuel used while the PTO or remote PTO is in the hold state and engine speed is above zero, over the life of the engine.";
CM_ BO_ 2566804990 "Gaseous Fuel Properties";
CM_ SG_ 2566804990 SpecificHeatRatio "The specific heat ratio of the fuel.";
CM_ BO_ 2633936894 "Fuel Consumption (Gaseous)";
CM_ SG_ 2633936894 TotalFuelUsed "Total fuel consumed (trip drive fuel + trip PTO moving fuel + trip PTO non-moving fuel + trip idle fuel) over the life of the engine.";
CM_ SG_ 2633936894 TripFuel "Total fuel consumed (trip drive fuel + trip PTO moving fuel + trip PTO non-moving fuel + trip idle fuel) since the last trip reset.";
CM_ BO_ 2566757630 "Sensor Electrical Power #2";
CM_ BO_ 2566757886 "Sensor Electrical Power #1";
CM_ BO_ 2566759678 "PTO Drive Engagement";
CM_ SG_ 2566759678 EnggmntSttusTransInputShaftPTO1 "Reports if this specific PTO drive is engaged.";
CM_ SG_ 2566759678 EnggmntSttusTransInputShaftPTO2 "Reports if this specific PTO drive is engaged.";
CM_ SG_ 2566759678 EnggmntSttusTransOutputShaftPTO "Reports if this specific PTO drive is engaged.";
CM_ SG_ 2566759678 EnggmntSttsTrnsfrCsOtptShaftPTO "Reports if this specific PTO drive is engaged.";
CM_ SG_ 2566759678 EnggmntCnsntTransInputShaftPTO1 "Status of the transmission controller’s consent to engage the first or sole PTO drive mounted on the transmission case.";
CM_ SG_ 2566759678 EnggmntCnsntTransInputShaftPTO2 "Status of the transmission controller’s consent to engage the second PTO drive mounted on the transmission case.";
CM_ SG_ 2566759678 EnggmntCnsntTransOutputShaftPTO "Status of the transmission controller’s consent to engage the PTO drive connected to the transmission output shaft.";
CM_ SG_ 2566759678 EnggmntCnsntTrnsfrCsOtptShftPTO "Status of the transmission controller’s consent to engage the PTO drive connected to the transfer case output shaft.";
CM_ BO_ 2432541438 "Fuel Information 3 (Gaseous)";
CM_ SG_ 2432541438 EngFuelValve2OutletAbsPress "Absolute pressure of gas on outlet side of the second fuel system control valve.";
CM_ SG_ 2432541438 EngFuelTemp2 "Temperature 2 of fuel (or gas).";
CM_ BO_ 2566761214 "Engine Fluid Level/Pressure 4";
CM_ SG_ 2566761214 EngCentrifugalOilFilterSpeed "The speed of a rotating (centrifugal) engine oil filter.";
CM_ SG_ 2566761214 EngCoolantPumpDiffPress "The differential pressure measured across the input and output of the engine coolant pump.";
CM_ BO_ 2432541694 "Electronic Engine Controller 6";
CM_ BO_ 2566759934 "Door Control 2";
CM_ SG_ 2566759934 EnableStatusOfDoor10 "Enable status of bus door 10.";
CM_ SG_ 2566759934 EnableStatusOfDoor9 "Enable status of bus door 9.";
CM_ SG_ 2566759934 EnableStatusOfDoor8 "Enable status of bus door 8.";
CM_ SG_ 2566759934 EnableStatusOfDoor7 "Enable status of bus door 7.";
CM_ SG_ 2566759934 EnableStatusOfDoor6 "Enable status of bus door 6.";
CM_ SG_ 2566759934 EnableStatusOfDoor5 "Enable status of bus door 5.";
CM_ SG_ 2566759934 EnableStatusOfDoor4 "Enable status of bus door 4.";
CM_ SG_ 2566759934 EnableStatusOfDoor3 "Enable status of bus door 3.";
CM_ SG_ 2566759934 EnableStatusOfDoor2 "Enable status of bus door 2.";
CM_ SG_ 2566759934 EnableStatusOfDoor1 "Enable status of bus door 1.";
BA_DEF_ BO_  "FrameFormat" ENUM  "StandardCAN","ExtendedCAN","reserved","J1939PG";
BA_DEF_  "Manufacturer" ENUM  "DBAG","VAG","BMW","PAG","GM","Fiat","Vector","DC(NFZ)","FORD";
BA_DEF_ SG_  "SigType" STRING ;
BA_DEF_ SG_  "SPN" INT 0 524287;
BA_DEF_ BO_  "GenMsgRequestable" INT 0 1;
BA_DEF_ BO_  "GenMsgSendType" ENUM  "cyclic","spontan","cyclicIfActive","spontanWithDelay","cyclicAndSpontan","cyclicAndSpontanWithDelay","spontanWithRepetition","cyclicIfActiveAndSpontanWD","noMsgSendType";
BA_DEF_ BO_  "VFrameFormat" ENUM  "StandardCAN","ExtendedCAN","reserved","J1939PG";
BA_DEF_ BO_  "GenMsgCycleTime" INT 0 3600000;
BA_DEF_ BU_  "NodeLayerModules" STRING ;
BA_DEF_ BU_  "NmStationAddress" INT 0 255;
BA_DEF_ BU_  "NmJ1939AAC" INT 0 1;
BA_DEF_ BU_  "NmJ1939IndustryGroup" INT 0 7;
BA_DEF_ BU_  "NmJ1939System" INT 0 127;
BA_DEF_ BU_  "NmJ1939SystemInstance" INT 0 15;
BA_DEF_ BU_  "NmJ1939Function" INT 0 255;
BA_DEF_ BU_  "NmJ1939FunctionInstance" INT 0 7;
BA_DEF_ BU_  "NmJ1939ECUInstance" INT 0 7;
BA_DEF_ BU_  "NmJ1939ManufacturerCode" INT 0 2047;
BA_DEF_ BU_  "NmJ1939IdentityNumber" INT 0 2097151;
BA_DEF_ BU_  "ECU" STRING ;
BA_DEF_  "DatabaseVersion" STRING ;
BA_DEF_  "BusType" STRING ;
BA_DEF_  "ProtocolType" STRING ;
BA_DEF_  "SAE_J1939-75_SpecVersion" STRING ;
BA_DEF_  "SAE_J1939-21_SpecVersion" STRING ;
BA_DEF_  "SAE_J1939-73_SpecVersion" STRING ;
BA_DEF_  "SAE_J1939-71_SpecVersion" STRING ;
BA_DEF_DEF_  "FrameFormat" "J1939PG";
BA_DEF_DEF_  "Manufacturer" "Vector";
BA_DEF_DEF_  "SigType" "";
BA_DEF_DEF_  "SPN" 0;
BA_DEF_DEF_  "GenMsgRequestable" 1;
BA_DEF_DEF_  "GenMsgSendType" "noMsgSendType";
BA_DEF_DEF_  "VFrameFormat" "J1939PG";
BA_DEF_DEF_  "GenMsgCycleTime" 0;
BA_DEF_DEF_  "NodeLayerModules" "J1939_NL.dll";
BA_DEF_DEF_  "NmStationAddress" 254;
BA_DEF_DEF_  "NmJ1939AAC" 0;
BA_DEF_DEF_  "NmJ1939IndustryGroup" 0;
BA_DEF_DEF_  "NmJ1939System" 0;
BA_DEF_DEF_  "NmJ1939SystemInstance" 0;
BA_DEF_DEF_  "NmJ1939Function" 0;
BA_DEF_DEF_  "NmJ1939FunctionInstance" 0;
BA_DEF_DEF_  "NmJ1939ECUInstance" 0;
BA_DEF_DEF_  "NmJ1939ManufacturerCode" 0;
BA_DEF_DEF_  "NmJ1939IdentityNumber" 0;
BA_DEF_DEF_  "ECU" "(null)";
BA_DEF_DEF_  "DatabaseVersion" "";
BA_DEF_DEF_  "BusType" "";
BA_DEF_DEF_  "ProtocolType" "J1939";
BA_DEF_DEF_  "SAE_J1939-75_SpecVersion" "";
BA_DEF_DEF_  "SAE_J1939-21_SpecVersion" "";
BA_DEF_DEF_  "SAE_J1939-73_SpecVersion" "";
BA_DEF_DEF_  "SAE_J1939-71_SpecVersion" "";
BA_ "BusType" "CAN";
BA_ "SAE_J1939-75_SpecVersion" "2005-01-21";
BA_ "SAE_J1939-21_SpecVersion" "2004-10-21";
BA_ "SAE_J1939-73_SpecVersion" "2004-09-17";
BA_ "SAE_J1939-71_SpecVersion" "2005-06-01";
BA_ "DatabaseVersion" "5.2 SP2";
BA_ "NmJ1939AAC" BU_ EMS 1;
BA_ "NmStationAddress" BU_ EMS 0;
BA_ "ECU" BU_ EMS "EMS";
BA_ "NmJ1939ManufacturerCode" BU_ EMS 1861;
BA_ "NmJ1939IndustryGroup" BU_ EMS 1;
BA_ "NmJ1939IdentityNumber" BU_ EMS 2;
BA_ "NmJ1939Function" BU_ EAS 44;
BA_ "NmJ1939AAC" BU_ EAS 1;
BA_ "NmStationAddress" BU_ EAS 61;
BA_ "ECU" BU_ EAS "EAS";
BA_ "NmJ1939IndustryGroup" BU_ EAS 1;
BA_ "NmJ1939ManufacturerCode" BU_ EAS 1861;
BA_ "NmJ1939IdentityNumber" BU_ EAS 1;
BA_ "GenMsgSendType" BO_ 2565869312 0;
BA_ "GenMsgCycleTime" BO_ 2565869312 50;
BA_ "GenMsgSendType" BO_ 2566843904 0;
BA_ "GenMsgCycleTime" BO_ 2566843904 1000;
BA_ "GenMsgSendType" BO_ 2566845696 0;
BA_ "GenMsgCycleTime" BO_ 2566845696 1000;
BA_ "GenMsgSendType" BO_ 2364488960 0;
BA_ "GenMsgCycleTime" BO_ 2364488960 100;
BA_ "GenMsgSendType" BO_ 2566848829 0;
BA_ "GenMsgCycleTime" BO_ 2566848829 100;
BA_ "GenMsgSendType" BO_ 2566848573 0;
BA_ "GenMsgCycleTime" BO_ 2566848573 100;
BA_ "GenMsgSendType" BO_ 2364539904 0;
BA_ "GenMsgCycleTime" BO_ 2364539904 100;
BA_ "GenMsgSendType" BO_ 2566849022 0;
BA_ "GenMsgCycleTime" BO_ 2566849022 100;
BA_ "GenMsgSendType" BO_ 2566848766 0;
BA_ "GenMsgCycleTime" BO_ 2566848766 100;
BA_ "GenMsgSendType" BO_ 2364538622 0;
BA_ "GenMsgCycleTime" BO_ 2364538622 100;
BA_ "GenMsgSendType" BO_ 2365485822 0;
BA_ "GenMsgCycleTime" BO_ 2365485822 50;
BA_ "GenMsgSendType" BO_ 2566768894 0;
BA_ "GenMsgCycleTime" BO_ 2566768894 1000;
BA_ "GenMsgSendType" BO_ 2566769406 0;
BA_ "GenMsgCycleTime" BO_ 2566769406 1000;
BA_ "GenMsgSendType" BO_ 2633934334 0;
BA_ "GenMsgCycleTime" BO_ 2633934334 1000;
BA_ "GenMsgSendType" BO_ 2566825726 0;
BA_ "GenMsgCycleTime" BO_ 2566825726 500;
BA_ "GenMsgSendType" BO_ 2566770942 0;
BA_ "GenMsgCycleTime" BO_ 2566770942 500;
BA_ "GenMsgSendType" BO_ 2566846206 0;
BA_ "GenMsgCycleTime" BO_ 2566846206 500;
BA_ "GenMsgSendType" BO_ 2566811134 0;
BA_ "GenMsgCycleTime" BO_ 2566811134 1000;
BA_ "GenMsgSendType" BO_ 2298375934 0;
BA_ "GenMsgCycleTime" BO_ 2298375934 20;
BA_ "GenMsgSendType" BO_ 2565867774 0;
BA_ "GenMsgCycleTime" BO_ 2565867774 50;
BA_ "GenMsgSendType" BO_ 2365449982 0;
BA_ "GenMsgCycleTime" BO_ 2365449982 100;
BA_ "GenMsgSendType" BO_ 2566757630 0;
BA_ "GenMsgCycleTime" BO_ 2566757630 1000;
BA_ "GenMsgSendType" BO_ 2566757886 0;
BA_ "GenMsgCycleTime" BO_ 2566757886 1000;
BA_ "GenMsgSendType" BO_ 2566759678 0;
BA_ "GenMsgCycleTime" BO_ 2566759678 100;
BA_ "GenMsgSendType" BO_ 2432541438 0;
BA_ "GenMsgCycleTime" BO_ 2432541438 500;
BA_ "GenMsgSendType" BO_ 2566761214 0;
BA_ "GenMsgCycleTime" BO_ 2566761214 500;
BA_ "GenMsgSendType" BO_ 2432541694 0;
BA_ "GenMsgCycleTime" BO_ 2432541694 100;
BA_ "GenMsgSendType" BO_ 2566759934 0;
BA_ "GenMsgCycleTime" BO_ 2566759934 100;
BA_ "SigType" SG_ 3221225472 AftrTrtmntOtltOxygnSnsrPrlmnryFM "RANGE";
BA_ "SPN" SG_ 3221225472 AftrTrtmntOtltOxygnSnsrPrlmnryFM 3235;
BA_ "SigType" SG_ 3221225472 AftrTrtmntOtltNOxSnsrPrlmnryFMI "RANGE";
BA_ "SPN" SG_ 3221225472 AftrTrtmntOtltNOxSnsrPrlmnryFMI 3234;
BA_ "SigType" SG_ 3221225472 AftrTrtmntOtltGsSnsorHeaterCtrl "DISCRETE";
BA_ "SPN" SG_ 3221225472 AftrTrtmntOtltGsSnsorHeaterCtrl 3233;
BA_ "SigType" SG_ 3221225472 AftrTrtmntOtltGsSnsrHtrPrlmnryFM "RANGE";
BA_ "SPN" SG_ 3221225472 AftrTrtmntOtltGsSnsrHtrPrlmnryFM 3232;
BA_ "SigType" SG_ 3221225472 AftrTrtmntOtltWdRngO2RdngStable "DISCRETE";
BA_ "SPN" SG_ 3221225472 AftrTrtmntOtltWdRngO2RdngStable 3231;
BA_ "SigType" SG_ 3221225472 AftrTrtmntOtletNOxReadingStable "DISCRETE";
BA_ "SPN" SG_ 3221225472 AftrTrtmntOtletNOxReadingStable 3230;
BA_ "SigType" SG_ 3221225472 AftrTrtmntOutletGasSensorAtTemp "DISCRETE";
BA_ "SPN" SG_ 3221225472 AftrTrtmntOutletGasSensorAtTemp 3229;
BA_ "SigType" SG_ 3221225472 AftrTrtmntOtltGsSnsrPwerInRange "DISCRETE";
BA_ "SPN" SG_ 3221225472 AftrTrtmntOtltGsSnsrPwerInRange 3228;
BA_ "SigType" SG_ 3221225472 AfterTreatmentOutletO2 "RANGE";
BA_ "SPN" SG_ 3221225472 AfterTreatmentOutletO2 3227;
BA_ "SigType" SG_ 3221225472 AfterTreatmentOutletNOx "RANGE";
BA_ "SPN" SG_ 3221225472 AfterTreatmentOutletNOx 3226;
BA_ "SigType" SG_ 3221225472 RoadSurfaceTemp "RANGE";
BA_ "SPN" SG_ 3221225472 RoadSurfaceTemp 79;
BA_ "SigType" SG_ 3221225472 EngAirInletTemp "RANGE";
BA_ "SPN" SG_ 3221225472 EngAirInletTemp 172;
BA_ "SigType" SG_ 3221225472 AmbientAirTemp "RANGE";
BA_ "SPN" SG_ 3221225472 AmbientAirTemp 171;
BA_ "SigType" SG_ 3221225472 CabInteriorTemp "RANGE";
BA_ "SPN" SG_ 3221225472 CabInteriorTemp 170;
BA_ "SigType" SG_ 3221225472 BarometricPress "RANGE";
BA_ "SPN" SG_ 3221225472 BarometricPress 108;
BA_ "SigType" SG_ 3221225472 EngDemandPercentTorque "RANGE";
BA_ "SPN" SG_ 3221225472 EngDemandPercentTorque 2432;
BA_ "SigType" SG_ 3221225472 EngStarterMode "DISCRETE";
BA_ "SPN" SG_ 3221225472 EngStarterMode 1675;
BA_ "SigType" SG_ 3221225472 SrcAddrssOfCtrllngDvcForEngCtrl "RANGE";
BA_ "SPN" SG_ 3221225472 SrcAddrssOfCtrllngDvcForEngCtrl 1483;
BA_ "SigType" SG_ 3221225472 EngSpeed "RANGE";
BA_ "SPN" SG_ 3221225472 EngSpeed 190;
BA_ "SigType" SG_ 3221225472 DriversDemandEngPercentTorque "RANGE";
BA_ "SPN" SG_ 3221225472 DriversDemandEngPercentTorque 512;
BA_ "SigType" SG_ 3221225472 EngTorqueMode "DISCRETE";
BA_ "SPN" SG_ 3221225472 EngTorqueMode 899;
BA_ "SPN" SG_ 3221225472 FlashRedStopLamp 3039;
BA_ "SPN" SG_ 3221225472 FlashProtectLamp 3041;
BA_ "SigType" SG_ 3221225472 FlashMalfuncIndicatorLamp "DISCRETE";
BA_ "SPN" SG_ 3221225472 FlashMalfuncIndicatorLamp 3038;
BA_ "SPN" SG_ 3221225472 FlashAmberWarningLamp 3040;
BA_ "SigType" SG_ 3221225472 MalfunctionIndicatorLampStatus "DISCRETE";
BA_ "SPN" SG_ 3221225472 MalfunctionIndicatorLampStatus 1213;
BA_ "SigType" SG_ 3221225472 AmberWarningLampStatus "DISCRETE";
BA_ "SPN" SG_ 3221225472 AmberWarningLampStatus 624;
BA_ "SigType" SG_ 3221225472 OccurenceCount1 "RANGE";
BA_ "SPN" SG_ 3221225472 OccurenceCount1 1216;
BA_ "SPN" SG_ 3221225472 SPNConversionMethod1 1706;
BA_ "SPN" SG_ 3221225472 FailureModeIdentifier1 1215;
BA_ "SPN" SG_ 3221225472 SPN1 1214;
BA_ "SigType" SG_ 3221225472 RedStopLampState "DISCRETE";
BA_ "SPN" SG_ 3221225472 RedStopLampState 623;
BA_ "SigType" SG_ 3221225472 ProtectLampStatus "DISCRETE";
BA_ "SPN" SG_ 3221225472 ProtectLampStatus 987;
BA_ "SigType" SG_ 3221225472 OccurenceCount5 "RANGE";
BA_ "SigType" SG_ 3221225472 OccurenceCount4 "RANGE";
BA_ "SigType" SG_ 3221225472 OccurenceCount3 "RANGE";
BA_ "SigType" SG_ 3221225472 OccurenceCount2 "RANGE";
BA_ "SPN" SG_ 3221225472 SPN1High 1214;
BA_ "SigType" SG_ 3221225472 EngAverageFuelEconomy "RANGE";
BA_ "SPN" SG_ 3221225472 EngAverageFuelEconomy 185;
BA_ "SigType" SG_ 3221225472 EngInstantaneousFuelEconomy "RANGE";
BA_ "SPN" SG_ 3221225472 EngInstantaneousFuelEconomy 184;
BA_ "SigType" SG_ 3221225472 EngFuelRate "RANGE";
BA_ "SPN" SG_ 3221225472 EngFuelRate 183;
BA_ "SigType" SG_ 3221225472 EngThrottlePos "RANGE";
BA_ "SPN" SG_ 3221225472 EngThrottlePos 51;
BA_ "SigType" SG_ 3221225472 EngInletAirMassFlowRate "RANGE";
BA_ "SPN" SG_ 3221225472 EngInletAirMassFlowRate 132;
BA_ "SigType" SG_ 3221225472 EngExhstGsRcrcltionMassFlowRate "RANGE";
BA_ "SPN" SG_ 3221225472 EngExhstGsRcrcltionMassFlowRate 2659;
BA_ "SigType" SG_ 3221225472 EngVrblGometryTurbo1ActuatorPos "RANGE";
BA_ "SPN" SG_ 3221225472 EngVrblGometryTurbo1ActuatorPos 2795;
BA_ "SigType" SG_ 3221225472 EngVrblGmtryTrbArCtrlShtffValve "DISCRETE";
BA_ "SPN" SG_ 3221225472 EngVrblGmtryTrbArCtrlShtffValve 2792;
BA_ "SigType" SG_ 3221225472 EngExhstGsRcirculationValveCtrl "RANGE";
BA_ "SPN" SG_ 3221225472 EngExhstGsRcirculationValveCtrl 2791;
BA_ "SigType" SG_ 3221225472 EngTrb1ClcltedTurbineOutletTemp "RANGE";
BA_ "SPN" SG_ 3221225472 EngTrb1ClcltedTurbineOutletTemp 2790;
BA_ "SigType" SG_ 3221225472 EngTrb1ClclatedTurbineInletTemp "RANGE";
BA_ "SPN" SG_ 3221225472 EngTrb1ClclatedTurbineInletTemp 2789;
BA_ "SigType" SG_ 3221225472 ExhaustGasMass "RANGE";
BA_ "SPN" SG_ 3221225472 ExhaustGasMass 3236;
BA_ "SPN" SG_ 3221225472 AftrTrtmntIntakeDewPointMessage 3237;
BA_ "SPN" SG_ 3221225472 AftrTrtmntExhustDewPointMessage 3238;
BA_ "SigType" SG_ 3221225472 EstEngPrsticLossesPercentTorque "RANGE";
BA_ "SPN" SG_ 3221225472 EstEngPrsticLossesPercentTorque 2978;
BA_ "SigType" SG_ 3221225472 EngsDsrdOprtngSpdAsymmtryAdjstmn "RANGE";
BA_ "SPN" SG_ 3221225472 EngsDsrdOprtngSpdAsymmtryAdjstmn 519;
BA_ "SigType" SG_ 3221225472 EngsDesiredOperatingSpeed "RANGE";
BA_ "SPN" SG_ 3221225472 EngsDesiredOperatingSpeed 515;
BA_ "SigType" SG_ 3221225472 NominalFrictionPercentTorque "RANGE";
BA_ "SPN" SG_ 3221225472 NominalFrictionPercentTorque 514;
BA_ "SigType" SG_ 3221225472 CatalystTankLevelPreliminaryFMI "DISCRETE";
BA_ "SPN" SG_ 3221225472 CatalystTankLevelPreliminaryFMI 3532;
BA_ "SigType" SG_ 3221225472 CatalystTankLevel2 "RANGE";
BA_ "SPN" SG_ 3221225472 CatalystTankLevel2 3517;
BA_ "SigType" SG_ 3221225472 EngCoolantFilterDiffPress "RANGE";
BA_ "SPN" SG_ 3221225472 EngCoolantFilterDiffPress 112;
BA_ "SigType" SG_ 3221225472 EngExhaustGasTemp "RANGE";
BA_ "SPN" SG_ 3221225472 EngExhaustGasTemp 173;
BA_ "SigType" SG_ 3221225472 EngAirFilter1DiffPress "RANGE";
BA_ "SPN" SG_ 3221225472 EngAirFilter1DiffPress 107;
BA_ "SigType" SG_ 3221225472 EngAirInletPress "RANGE";
BA_ "SPN" SG_ 3221225472 EngAirInletPress 106;
BA_ "SigType" SG_ 3221225472 EngIntakeManifold1Temp "RANGE";
BA_ "SPN" SG_ 3221225472 EngIntakeManifold1Temp 105;
BA_ "SigType" SG_ 3221225472 EngTurboBoostPress "RANGE";
BA_ "SPN" SG_ 3221225472 EngTurboBoostPress 102;
BA_ "SigType" SG_ 3221225472 EngParticulateTrapInletPress "RANGE";
BA_ "SPN" SG_ 3221225472 EngParticulateTrapInletPress 81;
BA_ "SigType" SG_ 3221225472 EngIntercoolerThermostatOpening "RANGE";
BA_ "SPN" SG_ 3221225472 EngIntercoolerThermostatOpening 1134;
BA_ "SigType" SG_ 3221225472 EngIntercoolerTemp "RANGE";
BA_ "SPN" SG_ 3221225472 EngIntercoolerTemp 52;
BA_ "SigType" SG_ 3221225472 EngTurboOilTemp "RANGE";
BA_ "SPN" SG_ 3221225472 EngTurboOilTemp 176;
BA_ "SigType" SG_ 3221225472 EngOilTemp1 "RANGE";
BA_ "SPN" SG_ 3221225472 EngOilTemp1 175;
BA_ "SigType" SG_ 3221225472 EngFuelTemp "RANGE";
BA_ "SPN" SG_ 3221225472 EngFuelTemp 174;
BA_ "SigType" SG_ 3221225472 EngCoolantTemp "RANGE";
BA_ "SPN" SG_ 3221225472 EngCoolantTemp 110;
BA_ "SigType" SG_ 3221225472 ActualEngPercentTorque "RANGE";
BA_ "SPN" SG_ 3221225472 ActualEngPercentTorque 513;
BA_ "SigType" SG_ 2565406525 ParameterGroupNumber "RANGE";
BA_ "SPN" SG_ 2565406525 ParameterGroupNumber 2574;
BA_ "SigType" SG_ 2565406525 GroupFunctionValue "RANGE";
BA_ "SPN" SG_ 2565406525 GroupFunctionValue 2542;
BA_ "SPN" SG_ 2565406525 ControlByte 2556;
BA_ "SigType" SG_ 2565603133 SequenceNumber "RANGE";
BA_ "SPN" SG_ 2565603133 SequenceNumber 2572;
BA_ "SigType" SG_ 2565668669 TotalNumberOfPacketsEoMA "RANGE";
BA_ "SPN" SG_ 2565668669 TotalNumberOfPacketsEoMA 2558;
BA_ "SigType" SG_ 2565668669 TotalMessageSizeEoMA "RANGE";
BA_ "SPN" SG_ 2565668669 TotalMessageSizeEoMA 2557;
BA_ "SigType" SG_ 2565668669 TotalMessageSizeBAM "RANGE";
BA_ "SPN" SG_ 2565668669 TotalMessageSizeBAM 2557;
BA_ "SigType" SG_ 2565668669 TotalNumberOfPacketsBAM "RANGE";
BA_ "SPN" SG_ 2565668669 TotalNumberOfPacketsBAM 2558;
BA_ "SigType" SG_ 2565668669 ConnectionAbortReason "RANGE";
BA_ "SPN" SG_ 2565668669 ConnectionAbortReason 2570;
BA_ "SigType" SG_ 2565668669 NextPacketNumberToBeSent "RANGE";
BA_ "SPN" SG_ 2565668669 NextPacketNumberToBeSent 2562;
BA_ "SigType" SG_ 2565668669 NumberOfPacketsThatCanBeSent "RANGE";
BA_ "SPN" SG_ 2565668669 NumberOfPacketsThatCanBeSent 2561;
BA_ "SPN" SG_ 2565668669 PGNumber 2560;
BA_ "SigType" SG_ 2565668669 MaximumNumberOfPackets "RANGE";
BA_ "SPN" SG_ 2565668669 MaximumNumberOfPackets 2559;
BA_ "SigType" SG_ 2565668669 TotalNumberOfPackets "RANGE";
BA_ "SPN" SG_ 2565668669 TotalNumberOfPackets 2558;
BA_ "SigType" SG_ 2565668669 TotalMessageSize "RANGE";
BA_ "SPN" SG_ 2565668669 TotalMessageSize 2557;
BA_ "SPN" SG_ 2565668669 ControlByte 2556;
BA_ "SigType" SG_ 2565869312 AftrTrtmntOtltOxygnSnsrPrlmnryFM "RANGE";
BA_ "SPN" SG_ 2565869312 AftrTrtmntOtltOxygnSnsrPrlmnryFM 3235;
BA_ "SigType" SG_ 2565869312 AftrTrtmntOtltNOxSnsrPrlmnryFMI "RANGE";
BA_ "SPN" SG_ 2565869312 AftrTrtmntOtltNOxSnsrPrlmnryFMI 3234;
BA_ "SigType" SG_ 2565869312 AftrTrtmntOtltGsSnsorHeaterCtrl "DISCRETE";
BA_ "SPN" SG_ 2565869312 AftrTrtmntOtltGsSnsorHeaterCtrl 3233;
BA_ "SigType" SG_ 2565869312 AftrTrtmntOtltGsSnsrHtrPrlmnryFM "RANGE";
BA_ "SPN" SG_ 2565869312 AftrTrtmntOtltGsSnsrHtrPrlmnryFM 3232;
BA_ "SigType" SG_ 2565869312 AftrTrtmntOtltWdRngO2RdngStable "DISCRETE";
BA_ "SPN" SG_ 2565869312 AftrTrtmntOtltWdRngO2RdngStable 3231;
BA_ "SigType" SG_ 2565869312 AftrTrtmntOtletNOxReadingStable "DISCRETE";
BA_ "SPN" SG_ 2565869312 AftrTrtmntOtletNOxReadingStable 3230;
BA_ "SigType" SG_ 2565869312 AftrTrtmntOutletGasSensorAtTemp "DISCRETE";
BA_ "SPN" SG_ 2565869312 AftrTrtmntOutletGasSensorAtTemp 3229;
BA_ "SigType" SG_ 2565869312 AftrTrtmntOtltGsSnsrPwerInRange "DISCRETE";
BA_ "SPN" SG_ 2565869312 AftrTrtmntOtltGsSnsrPwerInRange 3228;
BA_ "SigType" SG_ 2565869312 AfterTreatmentOutletO2 "RANGE";
BA_ "SPN" SG_ 2565869312 AfterTreatmentOutletO2 3227;
BA_ "SigType" SG_ 2565869312 AfterTreatmentOutletNOx "RANGE";
BA_ "SPN" SG_ 2565869312 AfterTreatmentOutletNOx 3226;
BA_ "SigType" SG_ 2566843904 EngIntercoolerThermostatOpening "RANGE";
BA_ "SPN" SG_ 2566843904 EngIntercoolerThermostatOpening 1134;
BA_ "SigType" SG_ 2566843904 EngIntercoolerTemp "RANGE";
BA_ "SPN" SG_ 2566843904 EngIntercoolerTemp 52;
BA_ "SigType" SG_ 2566843904 EngTurboOilTemp "RANGE";
BA_ "SPN" SG_ 2566843904 EngTurboOilTemp 176;
BA_ "SigType" SG_ 2566843904 EngOilTemp1 "RANGE";
BA_ "SPN" SG_ 2566843904 EngOilTemp1 175;
BA_ "SigType" SG_ 2566843904 EngFuelTemp "RANGE";
BA_ "SPN" SG_ 2566843904 EngFuelTemp 174;
BA_ "SigType" SG_ 2566843904 EngCoolantTemp "RANGE";
BA_ "SPN" SG_ 2566843904 EngCoolantTemp 110;
BA_ "SigType" SG_ 2566845696 RoadSurfaceTemp "RANGE";
BA_ "SPN" SG_ 2566845696 RoadSurfaceTemp 79;
BA_ "SigType" SG_ 2566845696 EngAirInletTemp "RANGE";
BA_ "SPN" SG_ 2566845696 EngAirInletTemp 172;
BA_ "SigType" SG_ 2566845696 AmbientAirTemp "RANGE";
BA_ "SPN" SG_ 2566845696 AmbientAirTemp 171;
BA_ "SigType" SG_ 2566845696 CabInteriorTemp "RANGE";
BA_ "SPN" SG_ 2566845696 CabInteriorTemp 170;
BA_ "SigType" SG_ 2566845696 BarometricPress "RANGE";
BA_ "SPN" SG_ 2566845696 BarometricPress 108;
BA_ "SPN" SG_ 2566848829 ReductionFluidTankLevel 520196;
BA_ "SPN" SG_ 2566848573 ReductionFluidPressure 520195;
BA_ "SPN" SG_ 2566848573 CatalystUpstreamTemperature 520193;
BA_ "SPN" SG_ 2566848573 CatalystDownstreamTemperature 520192;
BA_ "SigType" SG_ 2364539904 EngDemandPercentTorque "RANGE";
BA_ "SPN" SG_ 2364539904 EngDemandPercentTorque 2432;
BA_ "SigType" SG_ 2364539904 EngStarterMode "DISCRETE";
BA_ "SPN" SG_ 2364539904 EngStarterMode 1675;
BA_ "SigType" SG_ 2364539904 SrcAddrssOfCtrllngDvcForEngCtrl "RANGE";
BA_ "SPN" SG_ 2364539904 SrcAddrssOfCtrllngDvcForEngCtrl 1483;
BA_ "SigType" SG_ 2364539904 EngSpeed "RANGE";
BA_ "SPN" SG_ 2364539904 EngSpeed 190;
BA_ "SigType" SG_ 2364539904 ActualEngPercentTorque "RANGE";
BA_ "SPN" SG_ 2364539904 ActualEngPercentTorque 513;
BA_ "SigType" SG_ 2364539904 DriversDemandEngPercentTorque "RANGE";
BA_ "SPN" SG_ 2364539904 DriversDemandEngPercentTorque 512;
BA_ "SigType" SG_ 2364539904 EngTorqueMode "DISCRETE";
BA_ "SPN" SG_ 2364539904 EngTorqueMode 899;
BA_ "SigType" SG_ 2566835005 OccurenceCount1 "RANGE";
BA_ "SPN" SG_ 2566835005 OccurenceCount1 1216;
BA_ "SPN" SG_ 2566835005 SPNConversionMethod1 1706;
BA_ "SPN" SG_ 2566835005 FailureModeIdentifier1 1215;
BA_ "SPN" SG_ 2566835005 SPN1 1214;
BA_ "SigType" SG_ 2566835005 MalfunctionIndicatorLampStatus "DISCRETE";
BA_ "SPN" SG_ 2566835005 MalfunctionIndicatorLampStatus 1213;
BA_ "SigType" SG_ 2566835005 RedStopLampState "DISCRETE";
BA_ "SPN" SG_ 2566835005 RedStopLampState 623;
BA_ "SigType" SG_ 2566835005 AmberWarningLampStatus "DISCRETE";
BA_ "SPN" SG_ 2566835005 AmberWarningLampStatus 624;
BA_ "SigType" SG_ 2566835005 ProtectLampStatus "DISCRETE";
BA_ "SPN" SG_ 2566835005 ProtectLampStatus 987;
BA_ "SPN" SG_ 2566835005 FlashRedStopLamp 3039;
BA_ "SPN" SG_ 2566835005 FlashProtectLamp 3041;
BA_ "SigType" SG_ 2566835005 FlashMalfuncIndicatorLamp "DISCRETE";
BA_ "SPN" SG_ 2566835005 FlashMalfuncIndicatorLamp 3038;
BA_ "SPN" SG_ 2566835005 FlashAmberWarningLamp 3040;
BA_ "SigType" SG_ 2566835005 OccurenceCount5 "RANGE";
BA_ "SigType" SG_ 2566835005 OccurenceCount4 "RANGE";
BA_ "SigType" SG_ 2566835005 OccurenceCount3 "RANGE";
BA_ "SigType" SG_ 2566835005 OccurenceCount2 "RANGE";
BA_ "SPN" SG_ 2566835005 SPN1High 1214;
BA_ "SPN" SG_ 2566834749 FlashRedStopLamp 3039;
BA_ "SPN" SG_ 2566834749 FlashProtectLamp 3041;
BA_ "SigType" SG_ 2566834749 FlashMalfuncIndicatorLamp "DISCRETE";
BA_ "SPN" SG_ 2566834749 FlashMalfuncIndicatorLamp 3038;
BA_ "SPN" SG_ 2566834749 FlashAmberWarningLamp 3040;
BA_ "SigType" SG_ 2566834749 MalfunctionIndicatorLampStatus "DISCRETE";
BA_ "SPN" SG_ 2566834749 MalfunctionIndicatorLampStatus 1213;
BA_ "SigType" SG_ 2566834749 AmberWarningLampStatus "DISCRETE";
BA_ "SPN" SG_ 2566834749 AmberWarningLampStatus 624;
BA_ "SigType" SG_ 2566834749 OccurenceCount1 "RANGE";
BA_ "SPN" SG_ 2566834749 OccurenceCount1 1216;
BA_ "SPN" SG_ 2566834749 SPNConversionMethod1 1706;
BA_ "SPN" SG_ 2566834749 FailureModeIdentifier1 1215;
BA_ "SPN" SG_ 2566834749 SPN1 1214;
BA_ "SigType" SG_ 2566834749 RedStopLampState "DISCRETE";
BA_ "SPN" SG_ 2566834749 RedStopLampState 623;
BA_ "SigType" SG_ 2566834749 ProtectLampStatus "DISCRETE";
BA_ "SPN" SG_ 2566834749 ProtectLampStatus 987;
BA_ "SigType" SG_ 2566834749 OccurenceCount5 "RANGE";
BA_ "SigType" SG_ 2566834749 OccurenceCount4 "RANGE";
BA_ "SigType" SG_ 2566834749 OccurenceCount3 "RANGE";
BA_ "SigType" SG_ 2566834749 OccurenceCount2 "RANGE";
BA_ "SPN" SG_ 2566834749 SPN1High 1214;
BA_ "SPN" SG_ 2566849022 ReductionFluidTankLevel 520196;
BA_ "SPN" SG_ 2566848766 ReductionFluidPressure 520195;
BA_ "SPN" SG_ 2566848766 CatalystUpstreamTemperature 520193;
BA_ "SPN" SG_ 2566848766 CatalystDownstreamTemperature 520192;
BA_ "SigType" SG_ 2633938942 TotalEngCruiseTime "RANGE";
BA_ "SPN" SG_ 2633938942 TotalEngCruiseTime 1017;
BA_ "SigType" SG_ 2633938942 TotalDriveAverageLoadFactor "RANGE";
BA_ "SPN" SG_ 2633938942 TotalDriveAverageLoadFactor 1016;
BA_ "SigType" SG_ 2633938942 TripDriveAverageLoadFactor "RANGE";
BA_ "SPN" SG_ 2633938942 TripDriveAverageLoadFactor 1015;
BA_ "SigType" SG_ 2633938942 TripAverageEngSpeed "RANGE";
BA_ "SPN" SG_ 2633938942 TripAverageEngSpeed 1014;
BA_ "SigType" SG_ 2633938942 TripMaxEngSpeed "RANGE";
BA_ "SPN" SG_ 2633938942 TripMaxEngSpeed 1013;
BA_ "SigType" SG_ 2566799614 ImplementRearWorkLight "DISCRETE";
BA_ "SPN" SG_ 2566799614 ImplementRearWorkLight 2394;
BA_ "SigType" SG_ 2566799614 ImplementLeftForwardWorkLight "DISCRETE";
BA_ "SPN" SG_ 2566799614 ImplementLeftForwardWorkLight 2400;
BA_ "SigType" SG_ 2566799614 ImplementRightForwardWorkLight "DISCRETE";
BA_ "SPN" SG_ 2566799614 ImplementRightForwardWorkLight 2402;
BA_ "SigType" SG_ 2566799614 ImplementLeftFacingWorkLight "DISCRETE";
BA_ "SPN" SG_ 2566799614 ImplementLeftFacingWorkLight 2598;
BA_ "SigType" SG_ 2566799614 ImplementRightFacingWorkLight "DISCRETE";
BA_ "SPN" SG_ 2566799614 ImplementRightFacingWorkLight 2407;
BA_ "SigType" SG_ 2566799614 ImplementOEMOption1Light "DISCRETE";
BA_ "SPN" SG_ 2566799614 ImplementOEMOption1Light 2396;
BA_ "SigType" SG_ 2566799614 ImplementOEMOption2Light "DISCRETE";
BA_ "SPN" SG_ 2566799614 ImplementOEMOption2Light 2398;
BA_ "SigType" SG_ 2566799614 TrctrFrontHighMountedWorkLights "DISCRETE";
BA_ "SPN" SG_ 2566799614 TrctrFrontHighMountedWorkLights 2356;
BA_ "SigType" SG_ 2566799614 TrctorFrontLowMountedWorkLights "DISCRETE";
BA_ "SPN" SG_ 2566799614 TrctorFrontLowMountedWorkLights 2354;
BA_ "SigType" SG_ 2566799614 TrctorSideHighMountedWorkLights "DISCRETE";
BA_ "SPN" SG_ 2566799614 TrctorSideHighMountedWorkLights 2366;
BA_ "SigType" SG_ 2566799614 TractorSideLowMountedWorkLights "DISCRETE";
BA_ "SPN" SG_ 2566799614 TractorSideLowMountedWorkLights 2364;
BA_ "SigType" SG_ 2566799614 TrctorRearHighMountedWorkLights "DISCRETE";
BA_ "SPN" SG_ 2566799614 TrctorRearHighMountedWorkLights 2362;
BA_ "SigType" SG_ 2566799614 TractorRearLowMountedWorkLights "DISCRETE";
BA_ "SPN" SG_ 2566799614 TractorRearLowMountedWorkLights 2360;
BA_ "SigType" SG_ 2566799614 TrctrUndersideMountedWorkLights "DISCRETE";
BA_ "SPN" SG_ 2566799614 TrctrUndersideMountedWorkLights 2358;
BA_ "SigType" SG_ 2566799614 RearFogLights "DISCRETE";
BA_ "SPN" SG_ 2566799614 RearFogLights 2390;
BA_ "SigType" SG_ 2566799614 TractorMarkerLight "DISCRETE";
BA_ "SPN" SG_ 2566799614 TractorMarkerLight 2378;
BA_ "SigType" SG_ 2566799614 ImplementMarkerLight "DISCRETE";
BA_ "SPN" SG_ 2566799614 ImplementMarkerLight 2380;
BA_ "SigType" SG_ 2566799614 TractorClearanceLight "DISCRETE";
BA_ "SPN" SG_ 2566799614 TractorClearanceLight 2382;
BA_ "SigType" SG_ 2566799614 ImplementClearanceLight "DISCRETE";
BA_ "SPN" SG_ 2566799614 ImplementClearanceLight 2384;
BA_ "SigType" SG_ 2566799614 LeftStopLight "DISCRETE";
BA_ "SPN" SG_ 2566799614 LeftStopLight 2372;
BA_ "SigType" SG_ 2566799614 RightStopLight "DISCRETE";
BA_ "SPN" SG_ 2566799614 RightStopLight 2374;
BA_ "SigType" SG_ 2566799614 CenterStopLight "DISCRETE";
BA_ "SPN" SG_ 2566799614 CenterStopLight 2376;
BA_ "SigType" SG_ 2566799614 BackUpLightAndAlarmHorn "DISCRETE";
BA_ "SPN" SG_ 2566799614 BackUpLightAndAlarmHorn 2392;
BA_ "SigType" SG_ 2566799614 LeftTurnSignalLights "DISCRETE";
BA_ "SPN" SG_ 2566799614 LeftTurnSignalLights 2368;
BA_ "SigType" SG_ 2566799614 RightTurnSignalLights "DISCRETE";
BA_ "SPN" SG_ 2566799614 RightTurnSignalLights 2370;
BA_ "SigType" SG_ 2566799614 RotatingBeaconLight "DISCRETE";
BA_ "SPN" SG_ 2566799614 RotatingBeaconLight 2386;
BA_ "SigType" SG_ 2566799614 TractorFrontFogLights "DISCRETE";
BA_ "SPN" SG_ 2566799614 TractorFrontFogLights 2388;
BA_ "SigType" SG_ 2566799614 HighBeamHeadLightData "DISCRETE";
BA_ "SPN" SG_ 2566799614 HighBeamHeadLightData 2348;
BA_ "SigType" SG_ 2566799614 LowBeamHeadLightData "DISCRETE";
BA_ "SPN" SG_ 2566799614 LowBeamHeadLightData 2350;
BA_ "SigType" SG_ 2566799614 AltBeamHeadLightData "DISCRETE";
BA_ "SPN" SG_ 2566799614 AltBeamHeadLightData 2352;
BA_ "SigType" SG_ 2566799614 RunningLight "DISCRETE";
BA_ "SPN" SG_ 2566799614 RunningLight 2404;
BA_ "SigType" SG_ 2365473278 ImplementRearWorkLightCmd "DISCRETE";
BA_ "SPN" SG_ 2365473278 ImplementRearWorkLightCmd 2405;
BA_ "SigType" SG_ 2365473278 ImplmentLeftForwardWorkLightCmd "DISCRETE";
BA_ "SPN" SG_ 2365473278 ImplmentLeftForwardWorkLightCmd 2399;
BA_ "SigType" SG_ 2365473278 ImplmntRightForwardWorkLightCmd "DISCRETE";
BA_ "SPN" SG_ 2365473278 ImplmntRightForwardWorkLightCmd 2401;
BA_ "SigType" SG_ 2365473278 LightingDataRqCmd "DISCRETE";
BA_ "SPN" SG_ 2365473278 LightingDataRqCmd 2393;
BA_ "SigType" SG_ 2365473278 ImplementLeftFacingWorkLightCmd "DISCRETE";
BA_ "SPN" SG_ 2365473278 ImplementLeftFacingWorkLightCmd 2597;
BA_ "SigType" SG_ 2365473278 ImplmentRightFacingWorkLightCmd "DISCRETE";
BA_ "SPN" SG_ 2365473278 ImplmentRightFacingWorkLightCmd 2406;
BA_ "SigType" SG_ 2365473278 ImplementOEMOption1LightCmd "DISCRETE";
BA_ "SPN" SG_ 2365473278 ImplementOEMOption1LightCmd 2395;
BA_ "SigType" SG_ 2365473278 ImplementOEMOption2LightCmd "DISCRETE";
BA_ "SPN" SG_ 2365473278 ImplementOEMOption2LightCmd 2397;
BA_ "SigType" SG_ 2365473278 TrctrFrntHghMuntedWorkLightsCmd "DISCRETE";
BA_ "SPN" SG_ 2365473278 TrctrFrntHghMuntedWorkLightsCmd 2355;
BA_ "SigType" SG_ 2365473278 TrctrFrntLwMountedWorkLightsCmd "DISCRETE";
BA_ "SPN" SG_ 2365473278 TrctrFrntLwMountedWorkLightsCmd 2353;
BA_ "SigType" SG_ 2365473278 TrctrSdHighMountedWorkLightsCmd "DISCRETE";
BA_ "SPN" SG_ 2365473278 TrctrSdHighMountedWorkLightsCmd 2365;
BA_ "SigType" SG_ 2365473278 TrctrSdeLowMountedWorkLightsCmd "DISCRETE";
BA_ "SPN" SG_ 2365473278 TrctrSdeLowMountedWorkLightsCmd 2363;
BA_ "SigType" SG_ 2365473278 TrctrRrHighMountedWorkLightsCmd "DISCRETE";
BA_ "SPN" SG_ 2365473278 TrctrRrHighMountedWorkLightsCmd 2361;
BA_ "SigType" SG_ 2365473278 TrctrRarLowMountedWorkLightsCmd "DISCRETE";
BA_ "SPN" SG_ 2365473278 TrctrRarLowMountedWorkLightsCmd 2359;
BA_ "SigType" SG_ 2365473278 TrctrUndrsdMountedWorkLightsCmd "DISCRETE";
BA_ "SPN" SG_ 2365473278 TrctrUndrsdMountedWorkLightsCmd 2357;
BA_ "SigType" SG_ 2365473278 RearFogLightCmd "DISCRETE";
BA_ "SPN" SG_ 2365473278 RearFogLightCmd 2389;
BA_ "SigType" SG_ 2365473278 TractorMarkerLightCmd "DISCRETE";
BA_ "SPN" SG_ 2365473278 TractorMarkerLightCmd 2377;
BA_ "SigType" SG_ 2365473278 ImplementMarkerLightCmd "DISCRETE";
BA_ "SPN" SG_ 2365473278 ImplementMarkerLightCmd 2379;
BA_ "SigType" SG_ 2365473278 TractorClearanceLightCmd "DISCRETE";
BA_ "SPN" SG_ 2365473278 TractorClearanceLightCmd 2381;
BA_ "SigType" SG_ 2365473278 ImplementClearanceLightCmd "DISCRETE";
BA_ "SPN" SG_ 2365473278 ImplementClearanceLightCmd 2383;
BA_ "SigType" SG_ 2365473278 LeftStopLightCmd "DISCRETE";
BA_ "SPN" SG_ 2365473278 LeftStopLightCmd 2371;
BA_ "SigType" SG_ 2365473278 RightStopLightCmd "DISCRETE";
BA_ "SPN" SG_ 2365473278 RightStopLightCmd 2373;
BA_ "SigType" SG_ 2365473278 CenterStopLightCmd "DISCRETE";
BA_ "SPN" SG_ 2365473278 CenterStopLightCmd 2375;
BA_ "SigType" SG_ 2365473278 BackUpLightAndAlarmHornCmd "DISCRETE";
BA_ "SPN" SG_ 2365473278 BackUpLightAndAlarmHornCmd 2391;
BA_ "SigType" SG_ 2365473278 LeftTurnSignalLightsCmd "DISCRETE";
BA_ "SPN" SG_ 2365473278 LeftTurnSignalLightsCmd 2367;
BA_ "SigType" SG_ 2365473278 RightTurnSignalLightsCmd "DISCRETE";
BA_ "SPN" SG_ 2365473278 RightTurnSignalLightsCmd 2369;
BA_ "SigType" SG_ 2365473278 RotatingBeaconLightCmd "DISCRETE";
BA_ "SPN" SG_ 2365473278 RotatingBeaconLightCmd 2385;
BA_ "SigType" SG_ 2365473278 TractorFrontFogLightsCmd "DISCRETE";
BA_ "SPN" SG_ 2365473278 TractorFrontFogLightsCmd 2387;
BA_ "SigType" SG_ 2365473278 HighBeamHeadLightCmd "DISCRETE";
BA_ "SPN" SG_ 2365473278 HighBeamHeadLightCmd 2347;
BA_ "SigType" SG_ 2365473278 LowBeamHeadLightCmd "DISCRETE";
BA_ "SPN" SG_ 2365473278 LowBeamHeadLightCmd 2349;
BA_ "SigType" SG_ 2365473278 AltBeamHeadLightCmd "DISCRETE";
BA_ "SPN" SG_ 2365473278 AltBeamHeadLightCmd 2351;
BA_ "SigType" SG_ 2365473278 RunningLightCmd "DISCRETE";
BA_ "SPN" SG_ 2365473278 RunningLightCmd 2403;
BA_ "SigType" SG_ 2365485822 BladeCtrlMode "RANGE";
BA_ "SPN" SG_ 2365485822 BladeCtrlMode 1578;
BA_ "SigType" SG_ 2365485822 BladeDurationAndDirection "RANGE";
BA_ "SPN" SG_ 2365485822 BladeDurationAndDirection 1577;
BA_ "SigType" SG_ 2633926654 EngActualIgntTiming "RANGE";
BA_ "SPN" SG_ 2633926654 EngActualIgntTiming 1436;
BA_ "SigType" SG_ 2633926654 EngDesiredIgntTiming3 "RANGE";
BA_ "SPN" SG_ 2633926654 EngDesiredIgntTiming3 1435;
BA_ "SigType" SG_ 2633926654 EngDesiredIgntTiming2 "RANGE";
BA_ "SPN" SG_ 2633926654 EngDesiredIgntTiming2 1434;
BA_ "SigType" SG_ 2633926654 EngDesiredIgntTiming1 "RANGE";
BA_ "SPN" SG_ 2633926654 EngDesiredIgntTiming1 1433;
BA_ "SigType" SG_ 2633926398 EngCyl20IgntTiming "RANGE";
BA_ "SPN" SG_ 2633926398 EngCyl20IgntTiming 1432;
BA_ "SigType" SG_ 2633926398 EngCyl19IgntTiming "RANGE";
BA_ "SPN" SG_ 2633926398 EngCyl19IgntTiming 1431;
BA_ "SigType" SG_ 2633926398 EngCyl18IgntTiming "RANGE";
BA_ "SPN" SG_ 2633926398 EngCyl18IgntTiming 1430;
BA_ "SigType" SG_ 2633926398 EngCyl17IgntTiming "RANGE";
BA_ "SPN" SG_ 2633926398 EngCyl17IgntTiming 1429;
BA_ "SigType" SG_ 2633926142 EngCyl16IgntTiming "RANGE";
BA_ "SPN" SG_ 2633926142 EngCyl16IgntTiming 1428;
BA_ "SigType" SG_ 2633926142 EngCyl15IgntTiming "RANGE";
BA_ "SPN" SG_ 2633926142 EngCyl15IgntTiming 1427;
BA_ "SigType" SG_ 2633926142 EngCyl14IgntTiming "RANGE";
BA_ "SPN" SG_ 2633926142 EngCyl14IgntTiming 1426;
BA_ "SigType" SG_ 2633926142 EngCyl13IgntTiming "RANGE";
BA_ "SPN" SG_ 2633926142 EngCyl13IgntTiming 1425;
BA_ "SigType" SG_ 2633925886 EngCyl12IgntTiming "RANGE";
BA_ "SPN" SG_ 2633925886 EngCyl12IgntTiming 1424;
BA_ "SigType" SG_ 2633925886 EngCyl11IgntTiming "RANGE";
BA_ "SPN" SG_ 2633925886 EngCyl11IgntTiming 1423;
BA_ "SigType" SG_ 2633925886 EngCyl10IgntTiming "RANGE";
BA_ "SPN" SG_ 2633925886 EngCyl10IgntTiming 1422;
BA_ "SigType" SG_ 2633925886 EngCyl9IgntTiming "RANGE";
BA_ "SPN" SG_ 2633925886 EngCyl9IgntTiming 1421;
BA_ "SigType" SG_ 2633925630 EngCyl8IgntTiming "RANGE";
BA_ "SPN" SG_ 2633925630 EngCyl8IgntTiming 1420;
BA_ "SigType" SG_ 2633925630 EngCyl7IgntTiming "RANGE";
BA_ "SPN" SG_ 2633925630 EngCyl7IgntTiming 1419;
BA_ "SigType" SG_ 2633925630 EngCyl6IgntTiming "RANGE";
BA_ "SPN" SG_ 2633925630 EngCyl6IgntTiming 1418;
BA_ "SigType" SG_ 2633925630 EngCyl5IgntTiming "RANGE";
BA_ "SPN" SG_ 2633925630 EngCyl5IgntTiming 1417;
BA_ "SigType" SG_ 2633925374 EngCyl4IgntTiming "RANGE";
BA_ "SPN" SG_ 2633925374 EngCyl4IgntTiming 1416;
BA_ "SigType" SG_ 2633925374 EngCyl3IgntTiming "RANGE";
BA_ "SPN" SG_ 2633925374 EngCyl3IgntTiming 1415;
BA_ "SigType" SG_ 2633925374 EngCyl2IgntTiming "RANGE";
BA_ "SPN" SG_ 2633925374 EngCyl2IgntTiming 1414;
BA_ "SigType" SG_ 2633925374 EngCyl1IgntTiming "RANGE";
BA_ "SPN" SG_ 2633925374 EngCyl1IgntTiming 1413;
BA_ "SigType" SG_ 2633927422 EngCyl20IgntTransSecondOutput "RANGE";
BA_ "SPN" SG_ 2633927422 EngCyl20IgntTransSecondOutput 1412;
BA_ "SigType" SG_ 2633927422 EngCyl19IgntTransSecondOutput "RANGE";
BA_ "SPN" SG_ 2633927422 EngCyl19IgntTransSecondOutput 1411;
BA_ "SigType" SG_ 2633927422 EngCyl18IgntTransSecondOutput "RANGE";
BA_ "SPN" SG_ 2633927422 EngCyl18IgntTransSecondOutput 1410;
BA_ "SigType" SG_ 2633927422 EngCyl17IgntTransSecondOutput "RANGE";
BA_ "SPN" SG_ 2633927422 EngCyl17IgntTransSecondOutput 1409;
BA_ "SigType" SG_ 2633927166 EngCyl16IgntTransSecondOutput "RANGE";
BA_ "SPN" SG_ 2633927166 EngCyl16IgntTransSecondOutput 1408;
BA_ "SigType" SG_ 2633927166 EngCyl15IgntTransSecondOutput "RANGE";
BA_ "SPN" SG_ 2633927166 EngCyl15IgntTransSecondOutput 1407;
BA_ "SigType" SG_ 2633927166 EngCyl14IgntTransSecondOutput "RANGE";
BA_ "SPN" SG_ 2633927166 EngCyl14IgntTransSecondOutput 1406;
BA_ "SigType" SG_ 2633927166 EngCyl13IgntTransSecondOutput "RANGE";
BA_ "SPN" SG_ 2633927166 EngCyl13IgntTransSecondOutput 1405;
BA_ "SigType" SG_ 2633927166 EngCyl12IgntTransSecondOutput "RANGE";
BA_ "SPN" SG_ 2633927166 EngCyl12IgntTransSecondOutput 1404;
BA_ "SigType" SG_ 2633927166 EngCyl11IgntTransSecondOutput "RANGE";
BA_ "SPN" SG_ 2633927166 EngCyl11IgntTransSecondOutput 1403;
BA_ "SigType" SG_ 2633927166 EngCyl10IgntTransSecondOutput "RANGE";
BA_ "SPN" SG_ 2633927166 EngCyl10IgntTransSecondOutput 1402;
BA_ "SigType" SG_ 2633927166 EngCyl9IgntTransSecondOutput "RANGE";
BA_ "SPN" SG_ 2633927166 EngCyl9IgntTransSecondOutput 1401;
BA_ "SigType" SG_ 2633926910 EngCyl8IgntTransSecondOutput "RANGE";
BA_ "SPN" SG_ 2633926910 EngCyl8IgntTransSecondOutput 1400;
BA_ "SigType" SG_ 2633926910 EngCyl7IgntTransSecondOutput "RANGE";
BA_ "SPN" SG_ 2633926910 EngCyl7IgntTransSecondOutput 1399;
BA_ "SigType" SG_ 2633926910 EngCyl6IgntTransSecondOutput "RANGE";
BA_ "SPN" SG_ 2633926910 EngCyl6IgntTransSecondOutput 1398;
BA_ "SigType" SG_ 2633926910 EngCyl5IgntTransSecondOutput "RANGE";
BA_ "SPN" SG_ 2633926910 EngCyl5IgntTransSecondOutput 1397;
BA_ "SigType" SG_ 2633926910 EngCyl4IgntTransSecondOutput "RANGE";
BA_ "SPN" SG_ 2633926910 EngCyl4IgntTransSecondOutput 1396;
BA_ "SigType" SG_ 2633926910 EngCyl3IgntTransSecondOutput "RANGE";
BA_ "SPN" SG_ 2633926910 EngCyl3IgntTransSecondOutput 1395;
BA_ "SigType" SG_ 2633926910 EngCyl2IgntTransSecondOutput "RANGE";
BA_ "SPN" SG_ 2633926910 EngCyl2IgntTransSecondOutput 1394;
BA_ "SigType" SG_ 2633926910 EngCyl1IgntTransSecondOutput "RANGE";
BA_ "SPN" SG_ 2633926910 EngCyl1IgntTransSecondOutput 1393;
BA_ "SigType" SG_ 2566768894 EngOprtrPrmryIntrmdtSpdSlctStte "DISCRETE";
BA_ "SPN" SG_ 2566768894 EngOprtrPrmryIntrmdtSpdSlctStte 2892;
BA_ "SigType" SG_ 2566769406 EngOprtrPrmryIntrmdtSpeedSelect "DISCRETE";
BA_ "SPN" SG_ 2566769406 EngOprtrPrmryIntrmdtSpeedSelect 2880;
BA_ "SigType" SG_ 2566839550 EngTotalIdleHours "RANGE";
BA_ "SPN" SG_ 2566839550 EngTotalIdleHours 235;
BA_ "SigType" SG_ 2566839550 EngTotalIdleFuelUsed "RANGE";
BA_ "SPN" SG_ 2566839550 EngTotalIdleFuelUsed 236;
BA_ "SigType" SG_ 2633934334 EngIntakeManifold6Temp "RANGE";
BA_ "SPN" SG_ 2633934334 EngIntakeManifold6Temp 1803;
BA_ "SigType" SG_ 2633934334 EngIntakeManifold5Temp "RANGE";
BA_ "SPN" SG_ 2633934334 EngIntakeManifold5Temp 1802;
BA_ "SigType" SG_ 2633934334 EngIntakeManifold4Temp "RANGE";
BA_ "SPN" SG_ 2633934334 EngIntakeManifold4Temp 1133;
BA_ "SigType" SG_ 2633934334 EngIntakeManifold3Temp "RANGE";
BA_ "SPN" SG_ 2633934334 EngIntakeManifold3Temp 1132;
BA_ "SigType" SG_ 2633934334 EngIntakeManifold2Temp "RANGE";
BA_ "SPN" SG_ 2633934334 EngIntakeManifold2Temp 1131;
BA_ "SigType" SG_ 2566825726 EngTurbo4BoostPress "RANGE";
BA_ "SPN" SG_ 2566825726 EngTurbo4BoostPress 1130;
BA_ "SigType" SG_ 2566825726 EngTurbo3BoostPress "RANGE";
BA_ "SPN" SG_ 2566825726 EngTurbo3BoostPress 1129;
BA_ "SigType" SG_ 2566825726 EngTurbo2BoostPress "RANGE";
BA_ "SPN" SG_ 2566825726 EngTurbo2BoostPress 1128;
BA_ "SigType" SG_ 2566825726 EngTurbo1BoostPress "RANGE";
BA_ "SPN" SG_ 2566825726 EngTurbo1BoostPress 1127;
BA_ "SigType" SG_ 2566770942 EngAirFilter4DiffPress "RANGE";
BA_ "SPN" SG_ 2566770942 EngAirFilter4DiffPress 2811;
BA_ "SigType" SG_ 2566770942 EngAirFilter3DiffPress "RANGE";
BA_ "SPN" SG_ 2566770942 EngAirFilter3DiffPress 2810;
BA_ "SigType" SG_ 2566770942 EngAirFilter2DiffPress "RANGE";
BA_ "SPN" SG_ 2566770942 EngAirFilter2DiffPress 2809;
BA_ "SigType" SG_ 2566846206 EngCoolantFilterDiffPress "RANGE";
BA_ "SPN" SG_ 2566846206 EngCoolantFilterDiffPress 112;
BA_ "SigType" SG_ 2566846206 EngExhaustGasTemp "RANGE";
BA_ "SPN" SG_ 2566846206 EngExhaustGasTemp 173;
BA_ "SigType" SG_ 2566846206 EngAirFilter1DiffPress "RANGE";
BA_ "SPN" SG_ 2566846206 EngAirFilter1DiffPress 107;
BA_ "SigType" SG_ 2566846206 EngAirInletPress "RANGE";
BA_ "SPN" SG_ 2566846206 EngAirInletPress 106;
BA_ "SigType" SG_ 2566846206 EngIntakeManifold1Temp "RANGE";
BA_ "SPN" SG_ 2566846206 EngIntakeManifold1Temp 105;
BA_ "SigType" SG_ 2566846206 EngTurboBoostPress "RANGE";
BA_ "SPN" SG_ 2566846206 EngTurboBoostPress 102;
BA_ "SigType" SG_ 2566846206 EngParticulateTrapInletPress "RANGE";
BA_ "SPN" SG_ 2566846206 EngParticulateTrapInletPress 81;
BA_ "SigType" SG_ 2566811134 CabHeatingZone "DISCRETE";
BA_ "SPN" SG_ 2566811134 CabHeatingZone 1680;
BA_ "SigType" SG_ 2566811134 EngHeatingZone "DISCRETE";
BA_ "SPN" SG_ 2566811134 EngHeatingZone 1679;
BA_ "SigType" SG_ 2566811134 CabVentilation "DISCRETE";
BA_ "SPN" SG_ 2566811134 CabVentilation 1678;
BA_ "SigType" SG_ 2566811134 AuxilaryHeaterWaterPumpStatus "DISCRETE";
BA_ "SPN" SG_ 2566811134 AuxilaryHeaterWaterPumpStatus 1676;
BA_ "SigType" SG_ 2566811134 AuxHeaterMode "DISCRETE";
BA_ "SPN" SG_ 2566811134 AuxHeaterMode 1677;
BA_ "SigType" SG_ 2566811134 AuxHeaterOutputPowerPercent "RANGE";
BA_ "SPN" SG_ 2566811134 AuxHeaterOutputPowerPercent 1689;
BA_ "SigType" SG_ 2566811134 AuxHeaterInputAirTemp "RANGE";
BA_ "SPN" SG_ 2566811134 AuxHeaterInputAirTemp 1688;
BA_ "SigType" SG_ 2566811134 AuxHeaterOutputCoolantTemp "RANGE";
BA_ "SPN" SG_ 2566811134 AuxHeaterOutputCoolantTemp 1687;
BA_ "SigType" SG_ 2298375934 RearAxleRightWheelSpeed "RANGE";
BA_ "SPN" SG_ 2298375934 RearAxleRightWheelSpeed 1595;
BA_ "SigType" SG_ 2298375934 RearAxleLeftWheelSpeed "RANGE";
BA_ "SPN" SG_ 2298375934 RearAxleLeftWheelSpeed 1594;
BA_ "SigType" SG_ 2298375934 FrontAxleRightWheelSpeed "RANGE";
BA_ "SPN" SG_ 2298375934 FrontAxleRightWheelSpeed 1593;
BA_ "SigType" SG_ 2298375934 FrontAxleLeftWheelSpeed "RANGE";
BA_ "SPN" SG_ 2298375934 FrontAxleLeftWheelSpeed 1592;
BA_ "SigType" SG_ 2565867774 FireApparatusPumpEngagement "DISCRETE";
BA_ "SPN" SG_ 2565867774 FireApparatusPumpEngagement 2599;
BA_ "SigType" SG_ 2565867774 EngHydPressGovernorSwitch "DISCRETE";
BA_ "SPN" SG_ 2565867774 EngHydPressGovernorSwitch 1764;
BA_ "SigType" SG_ 2565867774 EngHydPrssGovernorModeIndicator "DISCRETE";
BA_ "SPN" SG_ 2565867774 EngHydPrssGovernorModeIndicator 1763;
BA_ "SigType" SG_ 2565867774 HydPress "RANGE";
BA_ "SPN" SG_ 2565867774 HydPress 1762;
BA_ "SigType" SG_ 2566841854 EngTotalRevolutions "RANGE";
BA_ "SPN" SG_ 2566841854 EngTotalRevolutions 249;
BA_ "SigType" SG_ 2566841854 EngTotalHoursOfOperation "RANGE";
BA_ "SPN" SG_ 2566841854 EngTotalHoursOfOperation 247;
BA_ "SigType" SG_ 2365449982 HydBrakeFluidLevelSwitch "DISCRETE";
BA_ "SPN" SG_ 2365449982 HydBrakeFluidLevelSwitch 2931;
BA_ "SigType" SG_ 2365449982 HydBrakeSystemAudibleWarningCmd "DISCRETE";
BA_ "SPN" SG_ 2365449982 HydBrakeSystemAudibleWarningCmd 2930;
BA_ "SigType" SG_ 2365449982 HydBrkePressSupplyStateCircuit2 "DISCRETE";
BA_ "SPN" SG_ 2365449982 HydBrkePressSupplyStateCircuit2 2583;
BA_ "SigType" SG_ 2365449982 HydBrkePressSupplyStateCircuit1 "DISCRETE";
BA_ "SPN" SG_ 2365449982 HydBrkePressSupplyStateCircuit1 2582;
BA_ "SigType" SG_ 2365449982 HydBrkPressWarningStateCircuit2 "DISCRETE";
BA_ "SPN" SG_ 2365449982 HydBrkPressWarningStateCircuit2 2585;
BA_ "SigType" SG_ 2365449982 HydBrkPressWarningStateCircuit1 "DISCRETE";
BA_ "SPN" SG_ 2365449982 HydBrkPressWarningStateCircuit1 2584;
BA_ "SigType" SG_ 2365449982 HydBrakePressCircuit2 "RANGE";
BA_ "SPN" SG_ 2365449982 HydBrakePressCircuit2 2581;
BA_ "SigType" SG_ 2365449982 HydBrakePressCircuit1 "RANGE";
BA_ "SPN" SG_ 2365449982 HydBrakePressCircuit1 2580;
BA_ "SigType" SG_ 2633939198 TripDriveFuelEconomy "RANGE";
BA_ "SPN" SG_ 2633939198 TripDriveFuelEconomy 1006;
BA_ "SigType" SG_ 2633939198 TripCruiseFuelUsed "RANGE";
BA_ "SPN" SG_ 2633939198 TripCruiseFuelUsed 1011;
BA_ "SigType" SG_ 2633939198 TripVehicleIdleFuelUsed "RANGE";
BA_ "SPN" SG_ 2633939198 TripVehicleIdleFuelUsed 1010;
BA_ "SigType" SG_ 2633939198 TripPTONonmovingFuelUsed "RANGE";
BA_ "SPN" SG_ 2633939198 TripPTONonmovingFuelUsed 1009;
BA_ "SigType" SG_ 2633939198 TripPTOMovingFuelUsed "RANGE";
BA_ "SPN" SG_ 2633939198 TripPTOMovingFuelUsed 1008;
BA_ "SigType" SG_ 2633939198 TripDriveFuelUsed "RANGE";
BA_ "SPN" SG_ 2633939198 TripDriveFuelUsed 1007;
BA_ "SigType" SG_ 2633927678 EngFuelValve1OutletAbsPress "RANGE";
BA_ "SPN" SG_ 2633927678 EngFuelValve1OutletAbsPress 2980;
BA_ "SigType" SG_ 2633927678 EngAirToFuelDiffPress "RANGE";
BA_ "SPN" SG_ 2633927678 EngAirToFuelDiffPress 1392;
BA_ "SigType" SG_ 2633927678 EngFuelValveDiffPress "RANGE";
BA_ "SPN" SG_ 2633927678 EngFuelValveDiffPress 1391;
BA_ "SigType" SG_ 2633927678 EngFuelValveInletAbsPress "RANGE";
BA_ "SPN" SG_ 2633927678 EngFuelValveInletAbsPress 1390;
BA_ "SigType" SG_ 2633925118 EngFuelFlowRate2 "RANGE";
BA_ "SPN" SG_ 2633925118 EngFuelFlowRate2 1441;
BA_ "SigType" SG_ 2633925118 EngFuelFlowRate1 "RANGE";
BA_ "SPN" SG_ 2633925118 EngFuelFlowRate1 1440;
BA_ "SigType" SG_ 2633925118 EngRqedFuelValve2Pos "RANGE";
BA_ "SPN" SG_ 2633925118 EngRqedFuelValve2Pos 1766;
BA_ "SigType" SG_ 2633925118 EngRqedFuelValve1Pos "RANGE";
BA_ "SPN" SG_ 2633925118 EngRqedFuelValve1Pos 1765;
BA_ "SigType" SG_ 2633925118 EngFuelValve2Pos "RANGE";
BA_ "SPN" SG_ 2633925118 EngFuelValve2Pos 1443;
BA_ "SigType" SG_ 2633925118 EngFuelValve1Pos "RANGE";
BA_ "SPN" SG_ 2633925118 EngFuelValve1Pos 1442;
BA_ "SigType" SG_ 2633937662 EngFuelSpecificGravity "RANGE";
BA_ "SPN" SG_ 2633937662 EngFuelSpecificGravity 1389;
BA_ "SigType" SG_ 2633937662 TripAverageFuelRate "RANGE";
BA_ "SPN" SG_ 2633937662 TripAverageFuelRate 1031;
BA_ "SigType" SG_ 2633937662 TotalEngPTOFuelUsed "RANGE";
BA_ "SPN" SG_ 2633937662 TotalEngPTOFuelUsed 1030;
BA_ "SigType" SG_ 2566804990 SpecificHeatRatio "RANGE";
BA_ "SPN" SG_ 2566804990 SpecificHeatRatio 1767;
BA_ "SigType" SG_ 2633936894 TotalFuelUsed "RANGE";
BA_ "SPN" SG_ 2633936894 TotalFuelUsed 1040;
BA_ "SigType" SG_ 2633936894 TripFuel "RANGE";
BA_ "SPN" SG_ 2633936894 TripFuel 1039;
BA_ "SigType" SG_ 2566757630 SensorSupplyVoltage6 "RANGE";
BA_ "SPN" SG_ 2566757630 SensorSupplyVoltage6 3514;
BA_ "SigType" SG_ 2566757630 SensorSupplyVoltage5 "RANGE";
BA_ "SPN" SG_ 2566757630 SensorSupplyVoltage5 3513;
BA_ "SigType" SG_ 2566757886 SensorSupplyVoltage4 "RANGE";
BA_ "SPN" SG_ 2566757886 SensorSupplyVoltage4 3512;
BA_ "SigType" SG_ 2566757886 SensorSupplyVoltage3 "RANGE";
BA_ "SPN" SG_ 2566757886 SensorSupplyVoltage3 3511;
BA_ "SigType" SG_ 2566757886 SensorSupplyVoltage2 "RANGE";
BA_ "SPN" SG_ 2566757886 SensorSupplyVoltage2 3510;
BA_ "SigType" SG_ 2566757886 SensorSupplyVoltage1 "RANGE";
BA_ "SPN" SG_ 2566757886 SensorSupplyVoltage1 3509;
BA_ "SigType" SG_ 2566759678 EnggmntSttusTransInputShaftPTO1 "DISCRETE";
BA_ "SPN" SG_ 2566759678 EnggmntSttusTransInputShaftPTO1 3460;
BA_ "SigType" SG_ 2566759678 EnggmntSttusTransInputShaftPTO2 "DISCRETE";
BA_ "SPN" SG_ 2566759678 EnggmntSttusTransInputShaftPTO2 3461;
BA_ "SigType" SG_ 2566759678 EnggmntSttusTransOutputShaftPTO "DISCRETE";
BA_ "SPN" SG_ 2566759678 EnggmntSttusTransOutputShaftPTO 3462;
BA_ "SigType" SG_ 2566759678 EnggmntSttsTrnsfrCsOtptShaftPTO "DISCRETE";
BA_ "SPN" SG_ 2566759678 EnggmntSttsTrnsfrCsOtptShaftPTO 3463;
BA_ "SigType" SG_ 2566759678 EnggmntCnsntTransInputShaftPTO1 "DISCRETE";
BA_ "SPN" SG_ 2566759678 EnggmntCnsntTransInputShaftPTO1 3456;
BA_ "SigType" SG_ 2566759678 EnggmntCnsntTransInputShaftPTO2 "DISCRETE";
BA_ "SPN" SG_ 2566759678 EnggmntCnsntTransInputShaftPTO2 3457;
BA_ "SigType" SG_ 2566759678 EnggmntCnsntTransOutputShaftPTO "DISCRETE";
BA_ "SPN" SG_ 2566759678 EnggmntCnsntTransOutputShaftPTO 3458;
BA_ "SigType" SG_ 2566759678 EnggmntCnsntTrnsfrCsOtptShftPTO "DISCRETE";
BA_ "SPN" SG_ 2566759678 EnggmntCnsntTrnsfrCsOtptShftPTO 3459;
BA_ "SigType" SG_ 2566759678 EnableSwitchTransInputShaftPTO1 "DISCRETE";
BA_ "SPN" SG_ 2566759678 EnableSwitchTransInputShaftPTO1 3452;
BA_ "SigType" SG_ 2566759678 EnableSwitchTransInputShaftPTO2 "DISCRETE";
BA_ "SPN" SG_ 2566759678 EnableSwitchTransInputShaftPTO2 3453;
BA_ "SigType" SG_ 2566759678 EnableSwitchTransOutputShaftPTO "DISCRETE";
BA_ "SPN" SG_ 2566759678 EnableSwitchTransOutputShaftPTO 3454;
BA_ "SigType" SG_ 2566759678 EnblSwtchTrnsfrCsOutputShaftPTO "DISCRETE";
BA_ "SPN" SG_ 2566759678 EnblSwtchTrnsfrCsOutputShaftPTO 3455;
BA_ "SigType" SG_ 2432541438 EngFuelValve2OutletAbsPress "RANGE";
BA_ "SPN" SG_ 2432541438 EngFuelValve2OutletAbsPress 3469;
BA_ "SigType" SG_ 2432541438 EngFuelTemp2 "RANGE";
BA_ "SPN" SG_ 2432541438 EngFuelTemp2 3468;
BA_ "SigType" SG_ 2432541438 EngGasMassFlowRate2 "RANGE";
BA_ "SPN" SG_ 2432541438 EngGasMassFlowRate2 3467;
BA_ "SigType" SG_ 2432541438 EngFuelValve2InletAbsPress "RANGE";
BA_ "SPN" SG_ 2432541438 EngFuelValve2InletAbsPress 3466;
BA_ "SigType" SG_ 2566761214 EngCentrifugalOilFilterSpeed "RANGE";
BA_ "SPN" SG_ 2566761214 EngCentrifugalOilFilterSpeed 3343;
BA_ "SigType" SG_ 2566761214 EngCoolantPumpDiffPress "RANGE";
BA_ "SPN" SG_ 2566761214 EngCoolantPumpDiffPress 3342;
BA_ "SigType" SG_ 2566761214 EngChargeAirCooler2InletPress "RANGE";
BA_ "SPN" SG_ 2566761214 EngChargeAirCooler2InletPress 3341;
BA_ "SigType" SG_ 2566761214 EngChargeAirCooler1InletPress "RANGE";
BA_ "SPN" SG_ 2566761214 EngChargeAirCooler1InletPress 3340;
BA_ "SigType" SG_ 2432541694 EngTurboCompressorCtrl "RANGE";
BA_ "SPN" SG_ 2432541694 EngTurboCompressorCtrl 3470;
BA_ "SigType" SG_ 2566759934 EnableStatusOfDoor10 "DISCRETE";
BA_ "SPN" SG_ 2566759934 EnableStatusOfDoor10 3441;
BA_ "SigType" SG_ 2566759934 OpenStatusOfDoor10 "DISCRETE";
BA_ "SPN" SG_ 2566759934 OpenStatusOfDoor10 3440;
BA_ "SigType" SG_ 2566759934 LockStatusOfDoor10 "DISCRETE";
BA_ "SPN" SG_ 2566759934 LockStatusOfDoor10 3439;
BA_ "SigType" SG_ 2566759934 EnableStatusOfDoor9 "DISCRETE";
BA_ "SPN" SG_ 2566759934 EnableStatusOfDoor9 3438;
BA_ "SigType" SG_ 2566759934 OpenStatusOfDoor9 "DISCRETE";
BA_ "SPN" SG_ 2566759934 OpenStatusOfDoor9 3437;
BA_ "SigType" SG_ 2566759934 LockStatusOfDoor9 "DISCRETE";
BA_ "SPN" SG_ 2566759934 LockStatusOfDoor9 3436;
BA_ "SigType" SG_ 2566759934 EnableStatusOfDoor8 "DISCRETE";
BA_ "SPN" SG_ 2566759934 EnableStatusOfDoor8 3435;
BA_ "SigType" SG_ 2566759934 OpenStatusOfDoor8 "DISCRETE";
BA_ "SPN" SG_ 2566759934 OpenStatusOfDoor8 3434;
BA_ "SigType" SG_ 2566759934 LockStatusOfDoor8 "DISCRETE";
BA_ "SPN" SG_ 2566759934 LockStatusOfDoor8 3433;
BA_ "SigType" SG_ 2566759934 EnableStatusOfDoor7 "DISCRETE";
BA_ "SPN" SG_ 2566759934 EnableStatusOfDoor7 3432;
BA_ "SigType" SG_ 2566759934 OpenStatusOfDoor7 "DISCRETE";
BA_ "SPN" SG_ 2566759934 OpenStatusOfDoor7 3431;
BA_ "SigType" SG_ 2566759934 LockStatusOfDoor7 "DISCRETE";
BA_ "SPN" SG_ 2566759934 LockStatusOfDoor7 3430;
BA_ "SigType" SG_ 2566759934 EnableStatusOfDoor6 "DISCRETE";
BA_ "SPN" SG_ 2566759934 EnableStatusOfDoor6 3429;
BA_ "SigType" SG_ 2566759934 OpenStatusOfDoor6 "DISCRETE";
BA_ "SPN" SG_ 2566759934 OpenStatusOfDoor6 3428;
BA_ "SigType" SG_ 2566759934 LockStatusOfDoor6 "DISCRETE";
BA_ "SPN" SG_ 2566759934 LockStatusOfDoor6 3427;
BA_ "SigType" SG_ 2566759934 EnableStatusOfDoor5 "DISCRETE";
BA_ "SPN" SG_ 2566759934 EnableStatusOfDoor5 3426;
BA_ "SigType" SG_ 2566759934 OpenStatusOfDoor5 "DISCRETE";
BA_ "SPN" SG_ 2566759934 OpenStatusOfDoor5 3425;
BA_ "SigType" SG_ 2566759934 LockStatusOfDoor5 "DISCRETE";
BA_ "SPN" SG_ 2566759934 LockStatusOfDoor5 3424;
BA_ "SigType" SG_ 2566759934 EnableStatusOfDoor4 "DISCRETE";
BA_ "SPN" SG_ 2566759934 EnableStatusOfDoor4 3423;
BA_ "SigType" SG_ 2566759934 OpenStatusOfDoor4 "DISCRETE";
BA_ "SPN" SG_ 2566759934 OpenStatusOfDoor4 3422;
BA_ "SigType" SG_ 2566759934 LockStatusOfDoor4 "DISCRETE";
BA_ "SPN" SG_ 2566759934 LockStatusOfDoor4 3421;
BA_ "SigType" SG_ 2566759934 EnableStatusOfDoor3 "DISCRETE";
BA_ "SPN" SG_ 2566759934 EnableStatusOfDoor3 3420;
BA_ "SigType" SG_ 2566759934 OpenStatusOfDoor3 "DISCRETE";
BA_ "SPN" SG_ 2566759934 OpenStatusOfDoor3 3419;
BA_ "SigType" SG_ 2566759934 LockStatusOfDoor3 "DISCRETE";
BA_ "SPN" SG_ 2566759934 LockStatusOfDoor3 3418;
BA_ "SigType" SG_ 2566759934 EnableStatusOfDoor2 "DISCRETE";
BA_ "SPN" SG_ 2566759934 EnableStatusOfDoor2 3417;
BA_ "SigType" SG_ 2566759934 OpenStatusOfDoor2 "DISCRETE";
BA_ "SPN" SG_ 2566759934 OpenStatusOfDoor2 3416;
BA_ "SigType" SG_ 2566759934 LockStatusOfDoor2 "DISCRETE";
BA_ "SPN" SG_ 2566759934 LockStatusOfDoor2 3415;
BA_ "SigType" SG_ 2566759934 EnableStatusOfDoor1 "DISCRETE";
BA_ "SPN" SG_ 2566759934 EnableStatusOfDoor1 3414;
BA_ "SigType" SG_ 2566759934 OpenStatusOfDoor1 "DISCRETE";
BA_ "SPN" SG_ 2566759934 OpenStatusOfDoor1 3413;
BA_ "SigType" SG_ 2566759934 LockStatusOfDoor1 "DISCRETE";
BA_ "SPN" SG_ 2566759934 LockStatusOfDoor1 3412;
VAL_ 3221225472 EngStarterMode 15 "notAvailable" 14 "error" 12 "starterInhibitedReasonUnknown" 9 "1011Reserved" 8 "strtrInhbtdDueToStarterOvertemp" 7 "strtrInhbtdDToActiveImmobilizer" 6 "strtrInhbtdDTDrvlnEnggdOthrTrns" 5 "strtrInhbtdDTEngNtReadyForStart" 4 "strtrInhbtdDToEngAlreadyRunning" 3 "strtFnshdStrtrNtActvAftrHvngBnA" 2 "starterActiveGearEngaged" 1 "starterActiveGearNotEngaged" 0 "startNotRqed" ;
VAL_ 3221225472 EngTorqueMode 15 "Not available" 11 "Remote accelerator" 10 "Braking system" 9 "High speed governor" 8 "Torque limiting" 7 "ABS control" 6 "Transmission control" 5 "ASR control" 4 "Road speed governor" 3 "PTO governor" 2 "Cruise control" 1 "Accelerator pedal/operator selec" 0 "Low idle governor/no request (de" ;
VAL_ 3221225472 FailureModeIdentifier5 31 "Not available" 19 "Received network data in error" 18 "Below normal (moderately severe)" 17 "Below normal (least severe)" 16 "Above normal (moderately severe)" 15 "Above normal (least severe)" 14 "Special intstructions" 13 "Out of calibration" 12 "Bad intelligent device" 11 "Root cause not known" 10 "Abnormal rate of change" 9 "Abnormal update rate" 8 "Abnormal frequency" 7 "Mechanical system not responding" 6 "Current above normal" 5 "Current below normal" 4 "Voltage below normal" 3 "Voltage above normal" 2 "Data erratic" 1 "Below normal (most severe)" 0 "Above normal (most severe)" ;
VAL_ 3221225472 FailureModeIdentifier4 31 "Not available" 19 "Received network data in error" 18 "Below normal (moderately severe)" 17 "Below normal (least severe)" 16 "Above normal (moderately severe)" 15 "Above normal (least severe)" 14 "Special intstructions" 13 "Out of calibration" 12 "Bad intelligent device" 11 "Root cause not known" 10 "Abnormal rate of change" 9 "Abnormal update rate" 8 "Abnormal frequency" 7 "Mechanical system not responding" 6 "Current above normal" 5 "Current below normal" 4 "Voltage below normal" 3 "Voltage above normal" 2 "Data erratic" 1 "Below normal (most severe)" 0 "Above normal (most severe)" ;
VAL_ 3221225472 FailureModeIdentifier3 31 "Not available" 19 "Received network data in error" 18 "Below normal (moderately severe)" 17 "Below normal (least severe)" 16 "Above normal (moderately severe)" 15 "Above normal (least severe)" 14 "Special intstructions" 13 "Out of calibration" 12 "Bad intelligent device" 11 "Root cause not known" 10 "Abnormal rate of change" 9 "Abnormal update rate" 8 "Abnormal frequency" 7 "Mechanical system not responding" 6 "Current above normal" 5 "Current below normal" 4 "Voltage below normal" 3 "Voltage above normal" 2 "Data erratic" 1 "Below normal (most severe)" 0 "Above normal (most severe)" ;
VAL_ 3221225472 FlashRedStopLamp 3 "Unavailable / Do Not Flash" 2 "Reserved" 1 "Fast Flash" 0 "Slow Flash" ;
VAL_ 3221225472 FlashProtectLamp 3 "Unavailable / Do Not Flash" 2 "Reserved" 1 "Fast Flash" 0 "Slow Flash" ;
VAL_ 3221225472 FlashMalfuncIndicatorLamp 3 "Unavailable / Do Not Flash" 2 "Reserved" 1 "Fast Flash" 0 "Slow Flash" ;
VAL_ 3221225472 FlashAmberWarningLamp 3 "Unavailable / Do Not Flash" 2 "Reserved" 1 "Fast Flash" 0 "Slow Flash" ;
VAL_ 3221225472 MalfunctionIndicatorLampStatus 3 "Not available" 2 "Reserved" 1 "Lamp on" 0 "Lamp off" ;
VAL_ 3221225472 AmberWarningLampStatus 3 "Not available" 2 "Reserved" 1 "Lamp on" 0 "Lamp off" ;
VAL_ 3221225472 FailureModeIdentifier1 31 "Not available" 19 "Received network data in error" 18 "Below normal (moderately severe)" 17 "Below normal (least severe)" 16 "Above normal (moderately severe)" 15 "Above normal (least severe)" 14 "Special intstructions" 13 "Out of calibration" 12 "Bad intelligent device" 11 "Root cause not known" 10 "Abnormal rate of change" 9 "Abnormal update rate" 8 "Abnormal frequency" 7 "Mechanical system not responding" 6 "Current above normal" 5 "Current below normal" 4 "Voltage below normal" 3 "Voltage above normal" 2 "Data erratic" 1 "Below normal (most severe)" 0 "Above normal (most severe)" ;
VAL_ 3221225472 RedStopLampState 3 "Not available" 2 "Reserved" 1 "Lamp on" 0 "Lamp off" ;
VAL_ 3221225472 ProtectLampStatus 3 "Not available" 2 "Reserved" 1 "Lamp on" 0 "Lamp off" ;
VAL_ 3221225472 FailureModeIdentifier2 31 "Not available" 19 "Received network data in error" 18 "Below normal (moderately severe)" 17 "Below normal (least severe)" 16 "Above normal (moderately severe)" 15 "Above normal (least severe)" 14 "Special intstructions" 13 "Out of calibration" 12 "Bad intelligent device" 11 "Root cause not known" 10 "Abnormal rate of change" 9 "Abnormal update rate" 8 "Abnormal frequency" 7 "Mechanical system not responding" 6 "Current above normal" 5 "Current below normal" 4 "Voltage below normal" 3 "Voltage above normal" 2 "Data erratic" 1 "Below normal (most severe)" 0 "Above normal (most severe)" ;
VAL_ 3221225472 EngVrblGmtryTrbArCtrlShtffValve 3 "NotAvailable" 2 "Reserved" 1 "VGTAirCtrlShutoffValveIsOn" 0 "VGTAirCtrlShutoffValveIsOff" ;
VAL_ 2565406525 ControlByte 24 "EAbort" 23 "EEoMACK" 22 "EDPO" 21 "ECTS" 20 "ERTS" 3 "CannotRespond" 2 "AccessDenied" 1 "NACK" 0 "ACK" 255 "Abort" 32 "BAM" 19 "EoMA" 17 "CTS" 16 "RTS" ;
VAL_ 2565668669 PGNumber 255 "NotAvailable" ;
VAL_ 2565668669 ControlByte 24 "EAbort" 23 "EEoMACK" 22 "EDPO" 21 "ECTS" 20 "ERTS" 3 "CannotRespond" 2 "AccessDenied" 1 "NACK" 0 "ACK" 255 "Abort" 32 "BAM" 19 "EoMA" 17 "CTS" 16 "RTS" ;
VAL_ 2364539904 EngStarterMode 15 "notAvailable" 14 "error" 12 "starterInhibitedReasonUnknown" 9 "1011Reserved" 8 "strtrInhbtdDueToStarterOvertemp" 7 "strtrInhbtdDToActiveImmobilizer" 6 "strtrInhbtdDTDrvlnEnggdOthrTrns" 5 "strtrInhbtdDTEngNtReadyForStart" 4 "strtrInhbtdDToEngAlreadyRunning" 3 "strtFnshdStrtrNtActvAftrHvngBnA" 2 "starterActiveGearEngaged" 1 "starterActiveGearNotEngaged" 0 "startNotRqed" ;
VAL_ 2364539904 EngTorqueMode 15 "Not available" 11 "Remote accelerator" 10 "Braking system" 9 "High speed governor" 8 "Torque limiting" 7 "ABS control" 6 "Transmission control" 5 "ASR control" 4 "Road speed governor" 3 "PTO governor" 2 "Cruise control" 1 "Accelerator pedal/operator selec" 0 "Low idle governor/no request (de" ;
VAL_ 2566835005 FailureModeIdentifier5 31 "Not available" 19 "Received network data in error" 18 "Below normal (moderately severe)" 17 "Below normal (least severe)" 16 "Above normal (moderately severe)" 15 "Above normal (least severe)" 14 "Special intstructions" 13 "Out of calibration" 12 "Bad intelligent device" 11 "Root cause not known" 10 "Abnormal rate of change" 9 "Abnormal update rate" 8 "Abnormal frequency" 7 "Mechanical system not responding" 6 "Current above normal" 5 "Current below normal" 4 "Voltage below normal" 3 "Voltage above normal" 2 "Data erratic" 1 "Below normal (most severe)" 0 "Above normal (most severe)" ;
VAL_ 2566835005 FailureModeIdentifier4 31 "Not available" 19 "Received network data in error" 18 "Below normal (moderately severe)" 17 "Below normal (least severe)" 16 "Above normal (moderately severe)" 15 "Above normal (least severe)" 14 "Special intstructions" 13 "Out of calibration" 12 "Bad intelligent device" 11 "Root cause not known" 10 "Abnormal rate of change" 9 "Abnormal update rate" 8 "Abnormal frequency" 7 "Mechanical system not responding" 6 "Current above normal" 5 "Current below normal" 4 "Voltage below normal" 3 "Voltage above normal" 2 "Data erratic" 1 "Below normal (most severe)" 0 "Above normal (most severe)" ;
VAL_ 2566835005 FailureModeIdentifier1 31 "Not available" 19 "Received network data in error" 18 "Below normal (moderately severe)" 17 "Below normal (least severe)" 16 "Above normal (moderately severe)" 15 "Above normal (least severe)" 14 "Special intstructions" 13 "Out of calibration" 12 "Bad intelligent device" 11 "Root cause not known" 10 "Abnormal rate of change" 9 "Abnormal update rate" 8 "Abnormal frequency" 7 "Mechanical system not responding" 6 "Current above normal" 5 "Current below normal" 4 "Voltage below normal" 3 "Voltage above normal" 2 "Data erratic" 1 "Below normal (most severe)" 0 "Above normal (most severe)" ;
VAL_ 2566835005 MalfunctionIndicatorLampStatus 3 "Not available" 2 "Reserved" 1 "Lamp on" 0 "Lamp off" ;
VAL_ 2566835005 RedStopLampState 3 "Not available" 2 "Reserved" 1 "Lamp on" 0 "Lamp off" ;
VAL_ 2566835005 AmberWarningLampStatus 3 "Not available" 2 "Reserved" 1 "Lamp on" 0 "Lamp off" ;
VAL_ 2566835005 ProtectLampStatus 3 "Not available" 2 "Reserved" 1 "Lamp on" 0 "Lamp off" ;
VAL_ 2566835005 FailureModeIdentifier3 31 "Not available" 19 "Received network data in error" 18 "Below normal (moderately severe)" 17 "Below normal (least severe)" 16 "Above normal (moderately severe)" 15 "Above normal (least severe)" 14 "Special intstructions" 13 "Out of calibration" 12 "Bad intelligent device" 11 "Root cause not known" 10 "Abnormal rate of change" 9 "Abnormal update rate" 8 "Abnormal frequency" 7 "Mechanical system not responding" 6 "Current above normal" 5 "Current below normal" 4 "Voltage below normal" 3 "Voltage above normal" 2 "Data erratic" 1 "Below normal (most severe)" 0 "Above normal (most severe)" ;
VAL_ 2566835005 FlashRedStopLamp 3 "Unavailable / Do Not Flash" 2 "Reserved" 1 "Fast Flash" 0 "Slow Flash" ;
VAL_ 2566835005 FlashProtectLamp 3 "Unavailable / Do Not Flash" 2 "Reserved" 1 "Fast Flash" 0 "Slow Flash" ;
VAL_ 2566835005 FlashMalfuncIndicatorLamp 3 "Unavailable / Do Not Flash" 2 "Reserved" 1 "Fast Flash" 0 "Slow Flash" ;
VAL_ 2566835005 FlashAmberWarningLamp 3 "Unavailable / Do Not Flash" 2 "Reserved" 1 "Fast Flash" 0 "Slow Flash" ;
VAL_ 2566835005 FailureModeIdentifier2 31 "Not available" 19 "Received network data in error" 18 "Below normal (moderately severe)" 17 "Below normal (least severe)" 16 "Above normal (moderately severe)" 15 "Above normal (least severe)" 14 "Special intstructions" 13 "Out of calibration" 12 "Bad intelligent device" 11 "Root cause not known" 10 "Abnormal rate of change" 9 "Abnormal update rate" 8 "Abnormal frequency" 7 "Mechanical system not responding" 6 "Current above normal" 5 "Current below normal" 4 "Voltage below normal" 3 "Voltage above normal" 2 "Data erratic" 1 "Below normal (most severe)" 0 "Above normal (most severe)" ;
VAL_ 2566834749 FailureModeIdentifier5 31 "Not available" 19 "Received network data in error" 18 "Below normal (moderately severe)" 17 "Below normal (least severe)" 16 "Above normal (moderately severe)" 15 "Above normal (least severe)" 14 "Special intstructions" 13 "Out of calibration" 12 "Bad intelligent device" 11 "Root cause not known" 10 "Abnormal rate of change" 9 "Abnormal update rate" 8 "Abnormal frequency" 7 "Mechanical system not responding" 6 "Current above normal" 5 "Current below normal" 4 "Voltage below normal" 3 "Voltage above normal" 2 "Data erratic" 1 "Below normal (most severe)" 0 "Above normal (most severe)" ;
VAL_ 2566834749 FailureModeIdentifier4 31 "Not available" 19 "Received network data in error" 18 "Below normal (moderately severe)" 17 "Below normal (least severe)" 16 "Above normal (moderately severe)" 15 "Above normal (least severe)" 14 "Special intstructions" 13 "Out of calibration" 12 "Bad intelligent device" 11 "Root cause not known" 10 "Abnormal rate of change" 9 "Abnormal update rate" 8 "Abnormal frequency" 7 "Mechanical system not responding" 6 "Current above normal" 5 "Current below normal" 4 "Voltage below normal" 3 "Voltage above normal" 2 "Data erratic" 1 "Below normal (most severe)" 0 "Above normal (most severe)" ;
VAL_ 2566834749 FailureModeIdentifier3 31 "Not available" 19 "Received network data in error" 18 "Below normal (moderately severe)" 17 "Below normal (least severe)" 16 "Above normal (moderately severe)" 15 "Above normal (least severe)" 14 "Special intstructions" 13 "Out of calibration" 12 "Bad intelligent device" 11 "Root cause not known" 10 "Abnormal rate of change" 9 "Abnormal update rate" 8 "Abnormal frequency" 7 "Mechanical system not responding" 6 "Current above normal" 5 "Current below normal" 4 "Voltage below normal" 3 "Voltage above normal" 2 "Data erratic" 1 "Below normal (most severe)" 0 "Above normal (most severe)" ;
VAL_ 2566834749 FlashRedStopLamp 3 "Unavailable / Do Not Flash" 2 "Reserved" 1 "Fast Flash" 0 "Slow Flash" ;
VAL_ 2566834749 FlashProtectLamp 3 "Unavailable / Do Not Flash" 2 "Reserved" 1 "Fast Flash" 0 "Slow Flash" ;
VAL_ 2566834749 FlashMalfuncIndicatorLamp 3 "Unavailable / Do Not Flash" 2 "Reserved" 1 "Fast Flash" 0 "Slow Flash" ;
VAL_ 2566834749 FlashAmberWarningLamp 3 "Unavailable / Do Not Flash" 2 "Reserved" 1 "Fast Flash" 0 "Slow Flash" ;
VAL_ 2566834749 MalfunctionIndicatorLampStatus 3 "Not available" 2 "Reserved" 1 "Lamp on" 0 "Lamp off" ;
VAL_ 2566834749 AmberWarningLampStatus 3 "Not available" 2 "Reserved" 1 "Lamp on" 0 "Lamp off" ;
VAL_ 2566834749 FailureModeIdentifier1 31 "Not available" 19 "Received network data in error" 18 "Below normal (moderately severe)" 17 "Below normal (least severe)" 16 "Above normal (moderately severe)" 15 "Above normal (least severe)" 14 "Special intstructions" 13 "Out of calibration" 12 "Bad intelligent device" 11 "Root cause not known" 10 "Abnormal rate of change" 9 "Abnormal update rate" 8 "Abnormal frequency" 7 "Mechanical system not responding" 6 "Current above normal" 5 "Current below normal" 4 "Voltage below normal" 3 "Voltage above normal" 2 "Data erratic" 1 "Below normal (most severe)" 0 "Above normal (most severe)" ;
VAL_ 2566834749 RedStopLampState 3 "Not available" 2 "Reserved" 1 "Lamp on" 0 "Lamp off" ;
VAL_ 2566834749 ProtectLampStatus 3 "Not available" 2 "Reserved" 1 "Lamp on" 0 "Lamp off" ;
VAL_ 2566834749 FailureModeIdentifier2 31 "Not available" 19 "Received network data in error" 18 "Below normal (moderately severe)" 17 "Below normal (least severe)" 16 "Above normal (moderately severe)" 15 "Above normal (least severe)" 14 "Special intstructions" 13 "Out of calibration" 12 "Bad intelligent device" 11 "Root cause not known" 10 "Abnormal rate of change" 9 "Abnormal update rate" 8 "Abnormal frequency" 7 "Mechanical system not responding" 6 "Current above normal" 5 "Current below normal" 4 "Voltage below normal" 3 "Voltage above normal" 2 "Data erratic" 1 "Below normal (most severe)" 0 "Above normal (most severe)" ;
VAL_ 2566799614 ImplementRearWorkLight 3 "NotAvailable" 2 "FaultDetected" 1 "Activate" 0 "Deactivate" ;
VAL_ 2566799614 ImplementLeftForwardWorkLight 3 "NotAvailable" 2 "FaultDetected" 1 "Activate" 0 "Deactivate" ;
VAL_ 2566799614 ImplementRightForwardWorkLight 3 "NotAvailable" 2 "FaultDetected" 1 "Activate" 0 "Deactivate" ;
VAL_ 2566799614 ImplementLeftFacingWorkLight 3 "NotAvailable" 2 "FaultDetected" 1 "Activate" 0 "Deactivate" ;
VAL_ 2566799614 ImplementRightFacingWorkLight 3 "NotAvailable" 2 "FaultDetected" 1 "Activate" 0 "Deactivate" ;
VAL_ 2566799614 ImplementOEMOption1Light 3 "NotAvailable" 2 "FaultDetected" 1 "Activate" 0 "Deactivate" ;
VAL_ 2566799614 ImplementOEMOption2Light 3 "NotAvailable" 2 "FaultDetected" 1 "Activate" 0 "Deactivate" ;
VAL_ 2566799614 TrctrFrontHighMountedWorkLights 3 "NotAvailable" 2 "FaultDetected" 1 "Activate" 0 "Deactivate" ;
VAL_ 2566799614 TrctorFrontLowMountedWorkLights 3 "NotAvailable" 2 "FaultDetected" 1 "Activate" 0 "Deactivate" ;
VAL_ 2566799614 TrctorSideHighMountedWorkLights 3 "NotAvailable" 2 "FaultDetected" 1 "Activated" 0 "Deactivated" ;
VAL_ 2566799614 TractorSideLowMountedWorkLights 3 "NotAvailable" 2 "FaultDetected" 1 "Activated" 0 "Deactivated" ;
VAL_ 2566799614 TrctorRearHighMountedWorkLights 3 "NotAvailable" 2 "FaultDetected" 1 "Activated" 0 "Deactivated" ;
VAL_ 2566799614 TractorRearLowMountedWorkLights 3 "NotAvailable" 2 "FaultDetected" 1 "Activate" 0 "Deactivate" ;
VAL_ 2566799614 TrctrUndersideMountedWorkLights 3 "NotAvailable" 2 "FaultDetected" 1 "Activate" 0 "Deactivate" ;
VAL_ 2566799614 RearFogLights 3 "NotAvailable" 2 "FaultDetected" 1 "Activated" 0 "Deactivated" ;
VAL_ 2566799614 TractorMarkerLight 3 "NotAvailable" 2 "FaultDetected" 1 "Activated" 0 "Deactivated" ;
VAL_ 2566799614 ImplementMarkerLight 3 "NotAvailable" 2 "FaultDetected" 1 "Activated" 0 "Deactivated" ;
VAL_ 2566799614 TractorClearanceLight 3 "NotAvailable" 2 "FaultDetected" 1 "Activated" 0 "Deactivated" ;
VAL_ 2566799614 ImplementClearanceLight 3 "NotAvailable" 2 "FaultDetected" 1 "Activated" 0 "Deactivated" ;
VAL_ 2566799614 LeftStopLight 3 "NotAvailable" 2 "FaultDetected" 1 "Activated" 0 "Deactivated" ;
VAL_ 2566799614 RightStopLight 3 "NotAvailable" 2 "FaultDetected" 1 "Activated" 0 "Deactivated" ;
VAL_ 2566799614 CenterStopLight 3 "NotAvailable" 2 "FaultDetected" 1 "Activated" 0 "Deactivated" ;
VAL_ 2566799614 BackUpLightAndAlarmHorn 3 "NotAvailable" 2 "FaultDetected" 1 "Activated" 0 "Deactivated" ;
VAL_ 2566799614 LeftTurnSignalLights 3 "NotAvailable" 2 "FaultDetected" 1 "Activated" 0 "Deactivated" ;
VAL_ 2566799614 RightTurnSignalLights 3 "NotAvailable" 2 "FaultDetected" 1 "Activated" 0 "Deactivated" ;
VAL_ 2566799614 RotatingBeaconLight 3 "NotAvailable" 2 "FaultDetected" 1 "Activated" 0 "Deactivated" ;
VAL_ 2566799614 TractorFrontFogLights 3 "NotAvailable" 2 "FaultDetected" 1 "Activated" 0 "Deactivated" ;
VAL_ 2566799614 HighBeamHeadLightData 3 "NotAvailable" 2 "FaultDetected" 1 "Activate" 0 "Deactivate" ;
VAL_ 2566799614 LowBeamHeadLightData 3 "NotAvailable" 2 "FaultDetected" 1 "Activate" 0 "Deactivate" ;
VAL_ 2566799614 AltBeamHeadLightData 3 "NotAvailable" 2 "FaultDetected" 1 "Activate" 0 "Deactivate" ;
VAL_ 2566799614 RunningLight 3 "NotAvailable" 2 "FaultDetected" 1 "Activate" 0 "Deactivate" ;
VAL_ 2365473278 ImplementRearWorkLightCmd 3 "DonTCare" 2 "Reserved" 1 "Activate" 0 "Deactivate" ;
VAL_ 2365473278 ImplmentLeftForwardWorkLightCmd 3 "DonTCare" 2 "Reserved" 1 "Activate" 0 "Deactivate" ;
VAL_ 2365473278 ImplmntRightForwardWorkLightCmd 3 "DonTCare" 2 "Reserved" 1 "Activate" 0 "Deactivate" ;
VAL_ 2365473278 LightingDataRqCmd 3 "DonTCare" 2 "Reserved" 1 "Activate" 0 "Deactivate" ;
VAL_ 2365473278 ImplementLeftFacingWorkLightCmd 3 "DonTCare" 2 "Reserved" 1 "Activate" 0 "Deactivate" ;
VAL_ 2365473278 ImplmentRightFacingWorkLightCmd 3 "DonTCare" 2 "Reserved" 1 "Activate" 0 "Deactivate" ;
VAL_ 2365473278 ImplementOEMOption1LightCmd 3 "DonTCare" 2 "Reserved" 1 "Activate" 0 "Deactivate" ;
VAL_ 2365473278 ImplementOEMOption2LightCmd 3 "DonTCare" 2 "Reserved" 1 "Activate" 0 "Deactivate" ;
VAL_ 2365473278 TrctrFrntHghMuntedWorkLightsCmd 3 "DonTCare" 2 "Reserved" 1 "Activate" 0 "Deactivate" ;
VAL_ 2365473278 TrctrFrntLwMountedWorkLightsCmd 3 "DonTCare" 2 "Reserved" 1 "Activate" 0 "Deactivate" ;
VAL_ 2365473278 TrctrSdHighMountedWorkLightsCmd 3 "DonTCare" 2 "Reserved" 1 "Activate" 0 "Deactivate" ;
VAL_ 2365473278 TrctrSdeLowMountedWorkLightsCmd 3 "DonTCare" 2 "Reserved" 1 "Activate" 0 "Deactivate" ;
VAL_ 2365473278 TrctrRrHighMountedWorkLightsCmd 3 "DonTCare" 2 "Reserved" 1 "Activate" 0 "Deactivate" ;
VAL_ 2365473278 TrctrRarLowMountedWorkLightsCmd 3 "DonTCare" 2 "Reserved" 1 "Activate" 0 "Deactivate" ;
VAL_ 2365473278 TrctrUndrsdMountedWorkLightsCmd 3 "DonTCare" 2 "Reserved" 1 "Activate" 0 "Deactivate" ;
VAL_ 2365473278 RearFogLightCmd 3 "DonTCare" 2 "Reserved" 1 "Activate" 0 "Deactivate" ;
VAL_ 2365473278 TractorMarkerLightCmd 3 "DonTCare" 2 "Reserved" 1 "Activate" 0 "Deactivate" ;
VAL_ 2365473278 ImplementMarkerLightCmd 3 "DonTCare" 2 "Reserved" 1 "Activate" 0 "Deactivate" ;
VAL_ 2365473278 TractorClearanceLightCmd 3 "DonTCare" 2 "Reserved" 1 "Activate" 0 "Deactivate" ;
VAL_ 2365473278 ImplementClearanceLightCmd 3 "DonTCare" 2 "Reserved" 1 "Activate" 0 "Deactivate" ;
VAL_ 2365473278 LeftStopLightCmd 3 "DonTCare" 2 "Reserved" 1 "Activate" 0 "Deactivate" ;
VAL_ 2365473278 RightStopLightCmd 3 "DonTCare" 2 "Reserved" 1 "Activate" 0 "Deactivate" ;
VAL_ 2365473278 CenterStopLightCmd 3 "DonTCare" 2 "Reserved" 1 "Activate" 0 "Deactivate" ;
VAL_ 2365473278 BackUpLightAndAlarmHornCmd 3 "DonTCare" 2 "Reserved" 1 "Activate" 0 "Deactivate" ;
VAL_ 2365473278 LeftTurnSignalLightsCmd 3 "DonTCare" 2 "Reserved" 1 "Activate" 0 "Deactivate" ;
VAL_ 2365473278 RightTurnSignalLightsCmd 3 "DonTCare" 2 "Reserved" 1 "Activate" 0 "Deactivate" ;
VAL_ 2365473278 RotatingBeaconLightCmd 3 "DonTCare" 2 "Reserved" 1 "Activate" 0 "Deactivate" ;
VAL_ 2365473278 TractorFrontFogLightsCmd 3 "DonTCare" 2 "Reserved" 1 "Activate" 0 "Deactivate" ;
VAL_ 2365473278 HighBeamHeadLightCmd 3 "DonTCare" 2 "Reserved" 1 "Activate" 0 "Deactivate" ;
VAL_ 2365473278 LowBeamHeadLightCmd 3 "DonTCare" 2 "Reserved" 1 "Activate" 0 "Deactivate" ;
VAL_ 2365473278 AltBeamHeadLightCmd 3 "DonTCare" 2 "Reserved" 1 "Activate" 0 "Deactivate" ;
VAL_ 2365473278 RunningLightCmd 3 "DonTCare" 2 "Reserved" 1 "Activate" 0 "Deactivate" ;
VAL_ 2365485822 BladeCtrlMode 2 "InactiveAutomaticMode" 1 "AutomaticMode" 0 "ManualMode" ;
VAL_ 2566768894 EngOprtrPrmryIntrmdtSpdSlctStte 15 "NotAvailable" 14 "SAEReserved" 1 "thr1101CtrlSttIsISCSttng1Thru13" 0 "CtrlSttIsISCFnctnltyIsNtRqdEngO" ;
VAL_ 2566769406 EngOprtrPrmryIntrmdtSpeedSelect 15 "NotAvailable" 14 "ErrorCondition" 1 "thr1101IndctsThtISCSttng1Thr13I" 0 "IndctsThtISCFnctnltyIsNtRqdEngO" ;
VAL_ 2566811134 CabHeatingZone 3 "NotAvailable" 2 "Reserved" 1 "CabHeatingZoneOn" 0 "CabHeatingZoneOff" ;
VAL_ 2566811134 EngHeatingZone 3 "NotAvailable" 2 "Reserved" 1 "EngHeatingZoneOn" 0 "EngHeatingZoneOff" ;
VAL_ 2566811134 CabVentilation 3 "NotAvailable" 2 "Reserved" 1 "CabIsVentilated" 0 "CabNotVentilated" ;
VAL_ 2566811134 AuxilaryHeaterWaterPumpStatus 3 "NotAvailable" 2 "Reserved" 1 "WaterPumpIsRunning" 0 "WaterPumpIsNotRunning" ;
VAL_ 2566811134 AuxHeaterMode 15 "NotAvailable" 14 "Error" 4 "1101NotDefined" 3 "NormalMode" 2 "EconomyMode" 1 "OffDTADRPrErpnRgltnsFrTrnsprtOf" 0 "HeaterNotActive" ;
VAL_ 2565867774 FireApparatusPumpEngagement 3 "NotAvailableNotInstalled" 2 "Error" 1 "PumpEngaged" 0 "PumpNotEngaged" ;
VAL_ 2565867774 EngHydPressGovernorSwitch 3 "NotAvailable" 2 "ErrorIndicator" 1 "PressModeActive" 0 "PressModeInactive" ;
VAL_ 2565867774 EngHydPrssGovernorModeIndicator 3 "NotAvailable" 2 "ErrorIndicator" 1 "Enabled" 0 "Disabled" ;
VAL_ 2365449982 HydBrakeFluidLevelSwitch 3 "NotAvailable" 2 "ErrorIndicator" 1 "FluidLevelIsSufficient" 0 "FluidLevelIsNotSufficient" ;
VAL_ 2365449982 HydBrakeSystemAudibleWarningCmd 3 "DontCare" 2 "Reserved" 1 "AudibleWarningOn" 0 "AudibleWarningOff" ;
VAL_ 2365449982 HydBrkePressSupplyStateCircuit2 3 "NotAvailable" 2 "ErrorIndicator" 1 "SupplyIsReliable" 0 "SupplyIsNotReliable" ;
VAL_ 2365449982 HydBrkePressSupplyStateCircuit1 3 "NotAvailable" 2 "ErrorIndicator" 1 "SupplyIsReliable" 0 "SupplyIsNotReliable" ;
VAL_ 2365449982 HydBrkPressWarningStateCircuit2 3 "NotAvailable" 2 "ErrorIndicator" 1 "PressLevelBelowWarningLevel" 0 "PressLevelSufficient" ;
VAL_ 2365449982 HydBrkPressWarningStateCircuit1 3 "NotAvailable" 2 "ErrorIndicator" 1 "PressLevelBelowWarningLevel" 0 "PressLevelSufficient" ;
VAL_ 2566759678 EnggmntSttusTransInputShaftPTO1 3 "NotAvailable" 2 "Error" 1 "DriveIsEngaged" 0 "DriveNotEngaged" ;
VAL_ 2566759678 EnggmntSttusTransInputShaftPTO2 3 "NotAvailable" 2 "Error" 1 "DriveIsEngaged" 0 "DriveNotEngaged" ;
VAL_ 2566759678 EnggmntSttusTransOutputShaftPTO 3 "NotAvailable" 2 "Error" 1 "DriveIsEngaged" 0 "DriveNotEngaged" ;
VAL_ 2566759678 EnggmntSttsTrnsfrCsOtptShaftPTO 3 "NotAvailable" 2 "Error" 1 "DriveIsEngaged" 0 "DriveNotEngaged" ;
VAL_ 2566759678 EnggmntCnsntTransInputShaftPTO1 3 "NotAvailable" 2 "Error" 1 "CnsentGivenPTODriveMayBeEngaged" 0 "CnsntNtGvnPTODrvShldNtBeEngaged" ;
VAL_ 2566759678 EnggmntCnsntTransInputShaftPTO2 3 "NotAvailable" 2 "Error" 1 "CnsentGivenPTODriveMayBeEngaged" 0 "CnsntNtGvnPTODrvShldNtBeEngaged" ;
VAL_ 2566759678 EnggmntCnsntTransOutputShaftPTO 3 "NotAvailable" 2 "Error" 1 "CnsentGivenPTODriveMayBeEngaged" 0 "CnsntNtGvnPTODrvShldNtBeEngaged" ;
VAL_ 2566759678 EnggmntCnsntTrnsfrCsOtptShftPTO 3 "NotAvailable" 2 "Error" 1 "CnsentGivenPTODriveMayBeEngaged" 0 "CnsntNtGvnPTODrvShldNtBeEngaged" ;
VAL_ 2566759678 EnableSwitchTransInputShaftPTO1 3 "NotAvailable" 2 "Error" 1 "EnblSwtchOffPTOOperationDesired" 0 "EnblSwtchOffPTOOprtonNotDesired" ;
VAL_ 2566759678 EnableSwitchTransInputShaftPTO2 3 "NotAvailable" 2 "Error" 1 "EnblSwtchOffPTOOperationDesired" 0 "EnblSwtchOffPTOOprtonNotDesired" ;
VAL_ 2566759678 EnableSwitchTransOutputShaftPTO 3 "NotAvailable" 2 "Error" 1 "EnblSwtchOffPTOOperationDesired" 0 "EnblSwtchOffPTOOprtonNotDesired" ;
VAL_ 2566759678 EnblSwtchTrnsfrCsOutputShaftPTO 3 "NotAvailable" 2 "Error" 1 "EnblSwtchOffPTOOperationDesired" 0 "EnblSwtchOffPTOOprtonNotDesired" ;
VAL_ 2432541694 EngTurboCompressorCtrl 4 "RprsntsFllyOpnTypcllyTrbCmprssr" ;
VAL_ 2566759934 EnableStatusOfDoor10 3 "notAvailable" 2 "error" 1 "doorEnabled" 0 "doorDisabled" ;
VAL_ 2566759934 OpenStatusOfDoor10 3 "notAvailable" 2 "error" 1 "doorOpened" 0 "doorClosed" ;
VAL_ 2566759934 LockStatusOfDoor10 3 "notAvailable" 2 "error" 1 "locked" 0 "unlocked" ;
VAL_ 2566759934 EnableStatusOfDoor9 3 "notAvailable" 2 "error" 1 "doorEnabled" 0 "doorDisabled" ;
VAL_ 2566759934 OpenStatusOfDoor9 3 "notAvailable" 2 "error" 1 "doorOpened" 0 "doorClosed" ;
VAL_ 2566759934 LockStatusOfDoor9 3 "notAvailable" 2 "error" 1 "locked" 0 "unlocked" ;
VAL_ 2566759934 EnableStatusOfDoor8 3 "notAvailable" 2 "error" 1 "doorEnabled" 0 "doorDisabled" ;
VAL_ 2566759934 OpenStatusOfDoor8 3 "notAvailable" 2 "error" 1 "doorOpened" 0 "doorClosed" ;
VAL_ 2566759934 LockStatusOfDoor8 3 "notAvailable" 2 "error" 1 "locked" 0 "unlocked" ;
VAL_ 2566759934 EnableStatusOfDoor7 3 "notAvailable" 2 "error" 1 "doorEnabled" 0 "doorDisabled" ;
VAL_ 2566759934 OpenStatusOfDoor7 3 "notAvailable" 2 "error" 1 "doorOpened" 0 "doorClosed" ;
VAL_ 2566759934 LockStatusOfDoor7 3 "notAvailable" 2 "error" 1 "locked" 0 "unlocked" ;
VAL_ 2566759934 EnableStatusOfDoor6 3 "notAvailable" 2 "error" 1 "doorEnabled" 0 "doorDisabled" ;
VAL_ 2566759934 OpenStatusOfDoor6 3 "notAvailable" 2 "error" 1 "doorOpened" 0 "doorClosed" ;
VAL_ 2566759934 LockStatusOfDoor6 3 "notAvailable" 2 "error" 1 "locked" 0 "unlocked" ;
VAL_ 2566759934 EnableStatusOfDoor5 3 "notAvailable" 2 "error" 1 "doorEnabled" 0 "doorDisabled" ;
VAL_ 2566759934 OpenStatusOfDoor5 3 "notAvailable" 2 "error" 1 "doorOpened" 0 "doorClosed" ;
VAL_ 2566759934 LockStatusOfDoor5 3 "notAvailable" 2 "error" 1 "locked" 0 "unlocked" ;
VAL_ 2566759934 EnableStatusOfDoor4 3 "notAvailable" 2 "error" 1 "doorEnabled" 0 "doorDisabled" ;
VAL_ 2566759934 OpenStatusOfDoor4 3 "notAvailable" 2 "error" 1 "doorOpened" 0 "doorClosed" ;
VAL_ 2566759934 LockStatusOfDoor4 3 "notAvailable" 2 "error" 1 "locked" 0 "unlocked" ;
VAL_ 2566759934 EnableStatusOfDoor3 3 "notAvailable" 2 "error" 1 "doorEnabled" 0 "doorDisabled" ;
VAL_ 2566759934 OpenStatusOfDoor3 3 "notAvailable" 2 "error" 1 "doorOpened" 0 "doorClosed" ;
VAL_ 2566759934 LockStatusOfDoor3 3 "notAvailable" 2 "error" 1 "locked" 0 "unlocked" ;
VAL_ 2566759934 EnableStatusOfDoor2 3 "notAvailable" 2 "error" 1 "doorEnabled" 0 "doorDisabled" ;
VAL_ 2566759934 OpenStatusOfDoor2 3 "notAvailable" 2 "error" 1 "doorOpened" 0 "doorClosed" ;
VAL_ 2566759934 LockStatusOfDoor2 3 "notAvailable" 2 "error" 1 "locked" 0 "unlocked" ;
VAL_ 2566759934 EnableStatusOfDoor1 3 "notAvailable" 2 "error" 1 "doorEnabled" 0 "doorDisabled" ;
VAL_ 2566759934 OpenStatusOfDoor1 3 "notAvailable" 2 "error" 1 "doorOpened" 0 "doorClosed" ;
VAL_ 2566759934 LockStatusOfDoor1 3 "notAvailable" 2 "error" 1 "locked" 0 "unlocked" ;
